VERSION ""

NS_ :

BS_:

BU_:

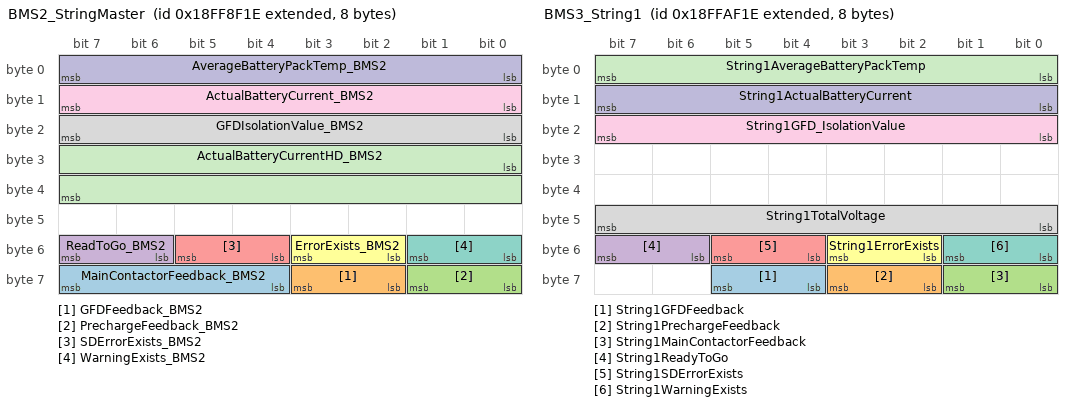
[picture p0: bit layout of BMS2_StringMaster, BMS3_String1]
BO_ 2566885150 BMS2_StringMaster: 8 Vector__XXX
 SG_ MainContactorFeedback_BMS2 : 60|4@1+ (1,0) [0|15] "" Vector__XXX
 SG_ GFDFeedback_BMS2 : 58|2@1+ (1,0) [0|3] "" Vector__XXX
 SG_ PrechargeFeedback_BMS2 : 56|2@1+ (1,0) [0|3] "" Vector__XXX
 SG_ ReadToGo_BMS2 : 54|2@1+ (1,0) [0|3] "" Vector__XXX
 SG_ SDErrorExists_BMS2 : 52|2@1+ (1,0) [0|3] "" Vector__XXX
 SG_ ErrorExists_BMS2 : 50|2@1+ (1,0) [0|3] "" Vector__XXX
 SG_ WarningExists_BMS2 : 48|2@1+ (1,0) [0|3] "" Vector__XXX
 SG_ GFDIsolationValue_BMS2 : 16|8@1+ (4,0) [0|1020] "kOhm" Vector__XXX
 SG_ ActualBatteryCurrent_BMS2 : 8|8@1+ (8,-1000) [-1000|1040] "A" Vector__XXX
 SG_ AverageBatteryPackTemp_BMS2 : 0|8@1+ (0.5,-50) [-50|77.5] "degC" Vector__XXX
 SG_ ActualBatteryCurrentHD_BMS2 : 24|16@1+ (0.065,-2130) [-2130|2129.775] "Amps" Vector__XXX

BO_ 2566893342 BMS3_String1: 8 Vector__XXX
 SG_ String1GFDFeedback : 60|2@1+ (1,0) [0|3] "" Vector__XXX
 SG_ String1PrechargeFeedback : 58|2@1+ (1,0) [0|3] "" Vector__XXX
 SG_ String1MainContactorFeedback : 56|2@1+ (1,0) [0|3] "" Vector__XXX
 SG_ String1ReadyToGo : 54|2@1+ (1,0) [0|3] "" Vector__XXX
 SG_ String1SDErrorExists : 52|2@1+ (1,0) [0|3] "" Vector__XXX
 SG_ String1ErrorExists : 50|2@1+ (1,0) [0|3] "" Vector__XXX
 SG_ String1WarningExists : 48|2@1+ (1,0) [0|3] "" Vector__XXX
 SG_ String1TotalVoltage : 40|8@1+ (3.2,0) [0|816] "Vdc" Vector__XXX
 SG_ String1GFD_IsolationValue : 16|8@1+ (4,0) [0|1020] "kOhm" Vector__XXX
 SG_ String1ActualBatteryCurrent : 8|8@1+ (4,-500) [-500|520] "A" Vector__XXX
 SG_ String1AverageBatteryPackTemp : 0|8@1+ (0.5,50) [50|177.5] "C" Vector__XXX

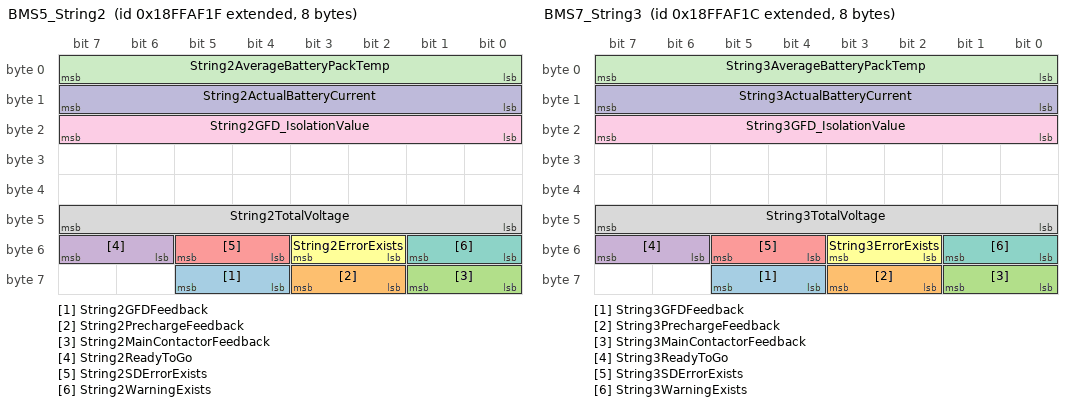
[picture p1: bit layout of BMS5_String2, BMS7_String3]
BO_ 2566893343 BMS5_String2: 8 Vector__XXX
 SG_ String2GFDFeedback : 60|2@1+ (1,0) [0|3] "" Vector__XXX
 SG_ String2PrechargeFeedback : 58|2@1+ (1,0) [0|3] "" Vector__XXX
 SG_ String2MainContactorFeedback : 56|2@1+ (1,0) [0|3] "" Vector__XXX
 SG_ String2ReadyToGo : 54|2@1+ (1,0) [0|3] "" Vector__XXX
 SG_ String2SDErrorExists : 52|2@1+ (1,0) [0|3] "" Vector__XXX
 SG_ String2ErrorExists : 50|2@1+ (1,0) [0|3] "" Vector__XXX
 SG_ String2WarningExists : 48|2@1+ (1,0) [0|3] "" Vector__XXX
 SG_ String2TotalVoltage : 40|8@1+ (3.2,0) [0|816] "Vdc" Vector__XXX
 SG_ String2GFD_IsolationValue : 16|8@1+ (4,0) [0|1020] "kOhm" Vector__XXX
 SG_ String2ActualBatteryCurrent : 8|8@1+ (4,-500) [-500|520] "A" Vector__XXX
 SG_ String2AverageBatteryPackTemp : 0|8@1+ (0.5,50) [50|177.5] "C" Vector__XXX

BO_ 2566893340 BMS7_String3: 8 Vector__XXX
 SG_ String3GFDFeedback : 60|2@1+ (1,0) [0|3] "" Vector__XXX
 SG_ String3PrechargeFeedback : 58|2@1+ (1,0) [0|3] "" Vector__XXX
 SG_ String3MainContactorFeedback : 56|2@1+ (1,0) [0|3] "" Vector__XXX
 SG_ String3ReadyToGo : 54|2@1+ (1,0) [0|3] "" Vector__XXX
 SG_ String3SDErrorExists : 52|2@1+ (1,0) [0|3] "" Vector__XXX
 SG_ String3ErrorExists : 50|2@1+ (1,0) [0|3] "" Vector__XXX
 SG_ String3WarningExists : 48|2@1+ (1,0) [0|3] "" Vector__XXX
 SG_ String3TotalVoltage : 40|8@1+ (3.2,0) [0|816] "Vdc" Vector__XXX
 SG_ String3GFD_IsolationValue : 16|8@1+ (4,0) [0|1020] "kOhm" Vector__XXX
 SG_ String3ActualBatteryCurrent : 8|8@1+ (4,-500) [-500|520] "A" Vector__XXX
 SG_ String3AverageBatteryPackTemp : 0|8@1+ (0.5,50) [50|177.5] "C" Vector__XXX

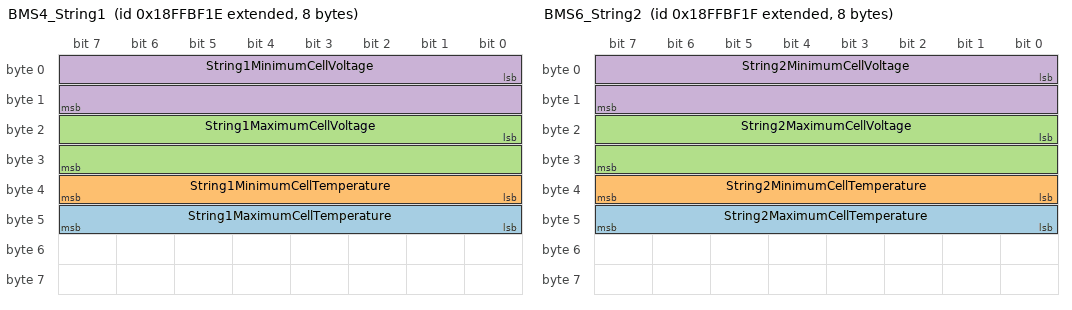
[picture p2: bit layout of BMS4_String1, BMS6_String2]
BO_ 2566897438 BMS4_String1: 8 Vector__XXX
 SG_ String1MaximumCellTemperature : 40|8@1+ (0.5,-50) [-50|77.5] "C" Vector__XXX
 SG_ String1MinimumCellTemperature : 32|8@1+ (0.5,-50) [-50|77.5] "C" Vector__XXX
 SG_ String1MaximumCellVoltage : 16|16@1+ (1,0) [0|65535] "mV" Vector__XXX
 SG_ String1MinimumCellVoltage : 0|16@1+ (1,0) [0|65535] "mV" Vector__XXX

BO_ 2566897439 BMS6_String2: 8 Vector__XXX
 SG_ String2MaximumCellTemperature : 40|8@1+ (0.5,-50) [-50|77.5] "C" Vector__XXX
 SG_ String2MinimumCellTemperature : 32|8@1+ (0.5,-50) [-50|77.5] "C" Vector__XXX
 SG_ String2MaximumCellVoltage : 16|16@1+ (1,0) [0|65535] "mV" Vector__XXX
 SG_ String2MinimumCellVoltage : 0|16@1+ (1,0) [0|65535] "mV" Vector__XXX

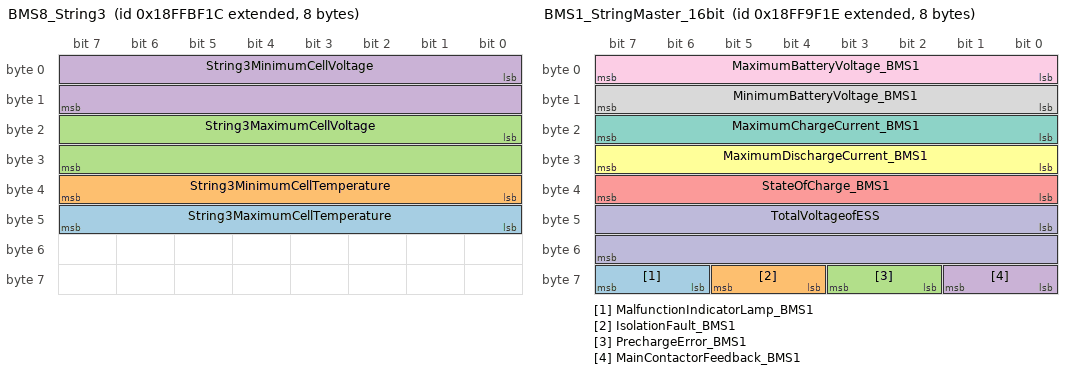
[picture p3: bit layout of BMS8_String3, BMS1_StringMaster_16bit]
BO_ 2566897436 BMS8_String3: 8 Vector__XXX
 SG_ String3MaximumCellTemperature : 40|8@1+ (0.5,-50) [-50|77.5] "C" Vector__XXX
 SG_ String3MinimumCellTemperature : 32|8@1+ (0.5,-50) [-50|77.5] "C" Vector__XXX
 SG_ String3MaximumCellVoltage : 16|16@1+ (1,0) [0|65535] "mV" Vector__XXX
 SG_ String3MinimumCellVoltage : 0|16@1+ (1,0) [0|65535] "mV" Vector__XXX

BO_ 2566889246 BMS1_StringMaster_16bit: 8 Vector__XXX
 SG_ MalfunctionIndicatorLamp_BMS1 : 62|2@1+ (1,0) [0|3] "" Vector__XXX
 SG_ IsolationFault_BMS1 : 60|2@1+ (1,0) [0|3] "" Vector__XXX
 SG_ PrechargeError_BMS1 : 58|2@1+ (1,0) [0|3] "" Vector__XXX
 SG_ MainContactorFeedback_BMS1 : 56|2@1+ (1,0) [0|3] "" Vector__XXX
 SG_ StateOfCharge_BMS1 : 32|8@1+ (0.4,0) [0|102] "%" Vector__XXX
 SG_ MaximumDischargeCurrent_BMS1 : 24|8@1+ (4,0) [0|1020] "A" Vector__XXX
 SG_ MaximumChargeCurrent_BMS1 : 16|8@1+ (4,0) [0|1020] "A" Vector__XXX
 SG_ MinimumBatteryVoltage_BMS1 : 8|8@1+ (3.2,0) [0|816] "Vdc" Vector__XXX
 SG_ MaximumBatteryVoltage_BMS1 : 0|8@1+ (3.2,0) [0|816] "Vdc" Vector__XXX
 SG_ TotalVoltageofESS : 40|16@1+ (0.1,0) [0|6425.5] "V" Vector__XXX

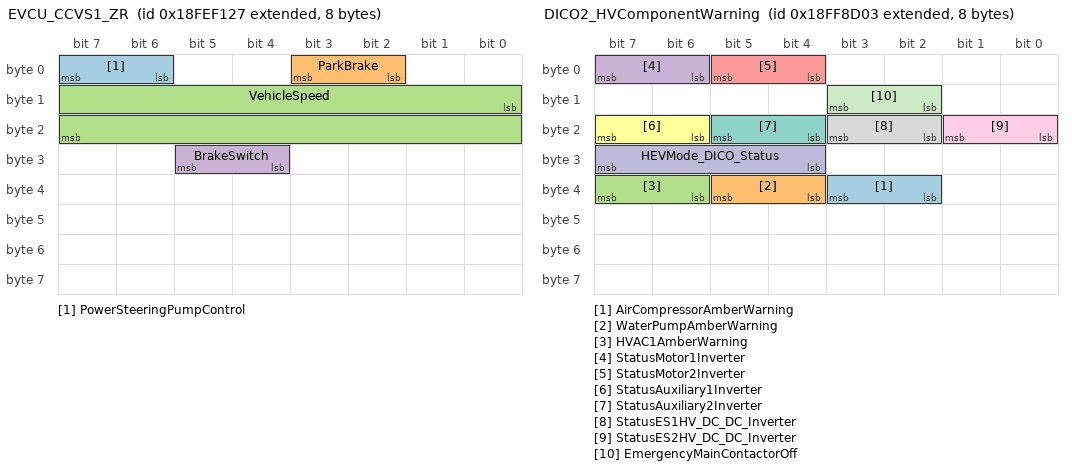
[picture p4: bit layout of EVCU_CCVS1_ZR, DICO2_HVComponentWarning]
BO_ 2566844711 EVCU_CCVS1_ZR: 8 Vector__XXX
 SG_ PowerSteeringPumpControl : 6|2@1+ (1,0) [0|3] "" Vector__XXX
 SG_ ParkBrake : 2|2@1+ (1,0) [0|3] "Enum" Vector__XXX
 SG_ VehicleSpeed : 8|16@1+ (0.00390625,0) [0|250.996] "km/h" Vector__XXX
 SG_ BrakeSwitch : 28|2@1+ (1,0) [0|1] "Enum" Vector__XXX

BO_ 2566885379 DICO5_DriveTempValues: 8 Vector__XXX
 SG_ Motor1WindingTemperature : 8|8@1+ (1,0) [0|255] "C" Vector__XXX
 SG_ iVPM2HeatsinkTemperature : 16|8@1+ (1,-40) [-40|215] "C" Vector__XXX
 SG_ iVPM1HeatsinkTemperature : 0|8@1+ (1,-40) [-40|215] "C" Vector__XXX

BO_ 2566885635 DICO6_BrakeResistor1Temp: 8 Vector__XXX
 SG_ BrakeResistor1Temperature : 16|8@1+ (1,-40) [-40|210] "C" Vector__XXX

BO_ 2566863655 AuxInverterRef1: 8 Vector__XXX
 SG_ SpeedControlAC2WaterPump : 8|8@1+ (0.25,0) [0|63.75] "%" Vector__XXX
 SG_ SpeedControlAC3_AirCompressor : 16|8@1+ (0.25,0) [0|63.75] "%" Vector__XXX
 SG_ SpeedControlAC1_HVAC : 0|8@1+ (0.25,0) [0|63.75] "%" Vector__XXX

BO_ 2566884611 DICO2_HVComponentWarning: 8 Vector__XXX
 SG_ AirCompressorAmberWarning : 34|2@1+ (1,0) [0|3] "" Vector__XXX
 SG_ WaterPumpAmberWarning : 36|2@1+ (1,0) [0|3] "" Vector__XXX
 SG_ HVAC1AmberWarning : 38|2@1+ (1,0) [0|3] "" Vector__XXX
 SG_ StatusMotor1Inverter : 6|2@1+ (1,0) [0|3] "Enum" Vector__XXX
 SG_ StatusMotor2Inverter : 4|2@1+ (1,0) [0|1] "Enum" Vector__XXX
 SG_ StatusAuxiliary1Inverter : 22|2@1+ (1,0) [0|1] "" Vector__XXX
 SG_ StatusAuxiliary2Inverter : 20|2@1+ (1,0) [0|1] "" Vector__XXX
 SG_ StatusES1HV_DC_DC_Inverter : 18|2@1+ (1,0) [0|1] "" Vector__XXX
 SG_ StatusES2HV_DC_DC_Inverter : 16|2@1+ (1,0) [0|1] "" Vector__XXX
 SG_ HEVMode_DICO_Status : 28|4@1+ (1,0) [0|1] "" Vector__XXX
 SG_ EmergencyMainContactorOff : 10|2@1+ (1,0) [0|1] "" Vector__XXX

BO_ 2566885123 DICO1_EVCU: 8 Vector__XXX
 SG_ DriveMotorSpeed : 16|16@1+ (0.46689,-15000) [-15000|15000] "RPM" Vector__XXX
 SG_ GlobalEnablePrechargeSiemens : 11|1@1+ (1,0) [0|1] "" Vector__XXX
 SG_ KeyStartAcknowledge : 2|1@1+ (1,0) [0|1] "" Vector__XXX
 SG_ BrakeResistorPowerFb : 48|8@1+ (1,0) [0|250] "kW" Vector__XXX
 SG_ DriveSystemActive : 0|1@1+ (1,0) [0|1] "Enum" Vector__XXX
 SG_ InitializationPhase : 1|1@1+ (1,0) [0|1] "Enum" Vector__XXX
 SG_ PreChargingActive : 3|1@1+ (1,0) [0|1] "Enum" Vector__XXX
 SG_ DNRStatus : 4|3@1+ (1,0) [0|7] "Enum" Vector__XXX
 SG_ DirectionOfVehicle : 7|1@1+ (1,0) [0|1] "Enum" Vector__XXX
 SG_ RedStopLamp : 8|1@1+ (1,0) [0|1] "Enum" Vector__XXX
 SG_ RedLampFlashing : 9|1@1+ (1,0) [0|1] "Enum" Vector__XXX
 SG_ AmberWarningLamp : 10|1@1+ (1,0) [0|1] "Enum" Vector__XXX
 SG_ CoolingPumpRequestTraction : 12|1@1+ (1,0) [0|1] "Enum" Vector__XXX
 SG_ CoolingFanRequestTraction : 13|1@1+ (1,0) [0|1] "Enum" Vector__XXX
 SG_ PrechargeContactorClosed : 14|1@1+ (1,0) [0|1] "Enum" Vector__XXX
 SG_ MainContactorClosed : 15|1@1+ (1,0) [0|1] "Enum" Vector__XXX
 SG_ ActualDriveMotorTorque : 40|8@1+ (1,-125) [-125|125] "%" Vector__XXX
 SG_ ErrorBufferIndication : 63|1@1+ (1,0) [0|1] "Enum" Vector__XXX
 SG_ ErrorBufferNumer : 56|4@1+ (1,0) [0|1] "Decimal" Vector__XXX

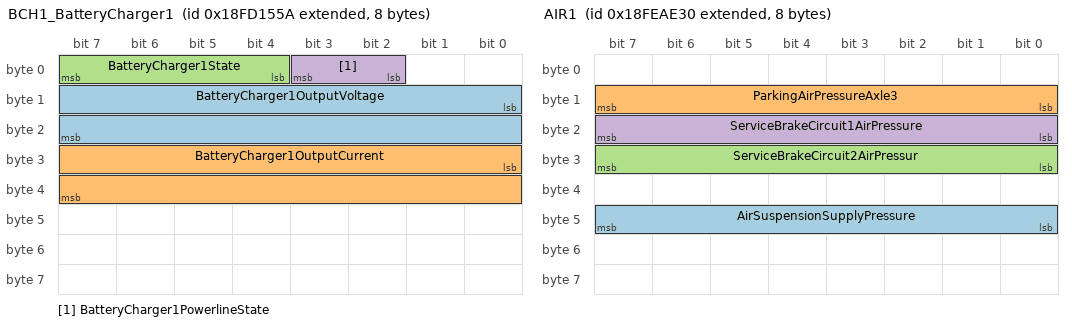
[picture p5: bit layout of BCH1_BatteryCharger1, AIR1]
BO_ 2566722906 BCH1_BatteryCharger1: 8 Vector__XXX
 SG_ BatteryCharger1OutputVoltage : 8|16@1+ (0.05,0) [0|3212.75] "Vdc" Vector__XXX
 SG_ BatteryCharger1OutputCurrent : 24|16@1+ (0.05,-1600) [-1600|1600] "A" Vector__XXX
 SG_ BatteryCharger1State : 4|4@1+ (1,0) [0|1] "Enum" Vector__XXX
 SG_ BatteryCharger1PowerlineState : 2|2@1+ (1,0) [0|1] "Enum" Vector__XXX

BO_ 2566722650 BCH2_BatteryCharger2: 8 Vector__XXX
 SG_ BatteryCharger2OutputVoltage : 8|16@1+ (0.05,0) [0|3276.75] "Vdc" Vector__XXX
 SG_ BatteryCharger2OutputCurrent : 24|16@1+ (0.05,-1600) [-1600|1676.75] "A" Vector__XXX

BO_ 2566827568 AIR1: 8 Vector__XXX
 SG_ AirSuspensionSupplyPressure : 40|8@1+ (0.1,0) [0|25.5] "kPa" Vector__XXX
 SG_ ParkingAirPressureAxle3 : 8|8@1+ (0.1,0) [0|25.5] "kPa" Vector__XXX
 SG_ ServiceBrakeCircuit2AirPressur : 24|8@1+ (0.1,0) [0|25.5] "kPa" Vector__XXX
 SG_ ServiceBrakeCircuit1AirPressure : 16|8@1+ (0.1,0) [0|25.5] "kPa" Vector__XXX

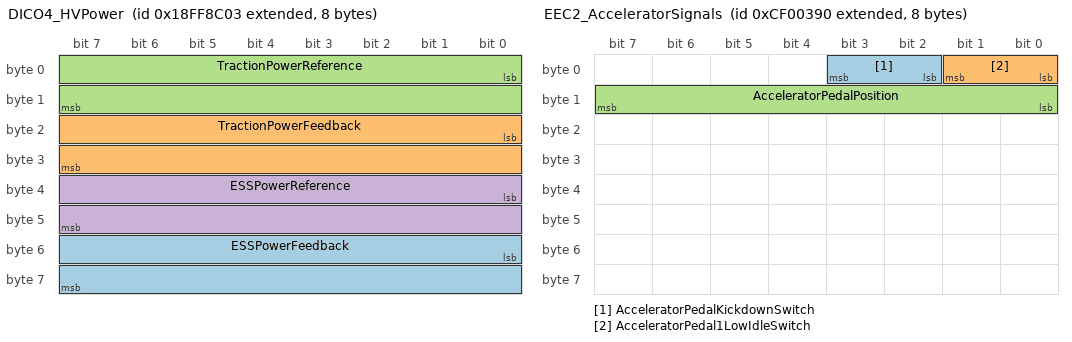
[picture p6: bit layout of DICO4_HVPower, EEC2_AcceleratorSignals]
BO_ 2566884355 DICO4_HVPower: 8 Vector__XXX
 SG_ ESSPowerFeedback : 48|16@1+ (0.0159,-510) [-510|510.001] "kW" Vector__XXX
 SG_ TractionPowerFeedback : 16|16@1+ (0.0159,-510) [-510|510.001] "kW" Vector__XXX
 SG_ TractionPowerReference : 0|16@1+ (0.0159,-510) [-510|510] "kW" Vector__XXX
 SG_ ESSPowerReference : 32|16@1+ (0.0159,-510) [-510|510] "kW" Vector__XXX

BO_ 2566884867 DICO3_DCLinkVoltageCurrent: 8 Vector__XXX
 SG_ DCLinkVoltageDriveSystem : 0|8@1+ (3.2,0) [0|800] "Vdc" Vector__XXX
 SG_ DCLinkTractionCurrent : 8|8@1+ (4,-500) [-500|500] "A" Vector__XXX

BO_ 2364539792 EEC2_AcceleratorSignals: 8 Vector__XXX
 SG_ AcceleratorPedalKickdownSwitch : 2|2@1+ (1,0) [0|3] "" Vector__XXX
 SG_ AcceleratorPedal1LowIdleSwitch : 0|2@1+ (1,0) [0|3] "" Vector__XXX
 SG_ AcceleratorPedalPosition : 8|8@1+ (0.4,0) [0|102] "%" Vector__XXX

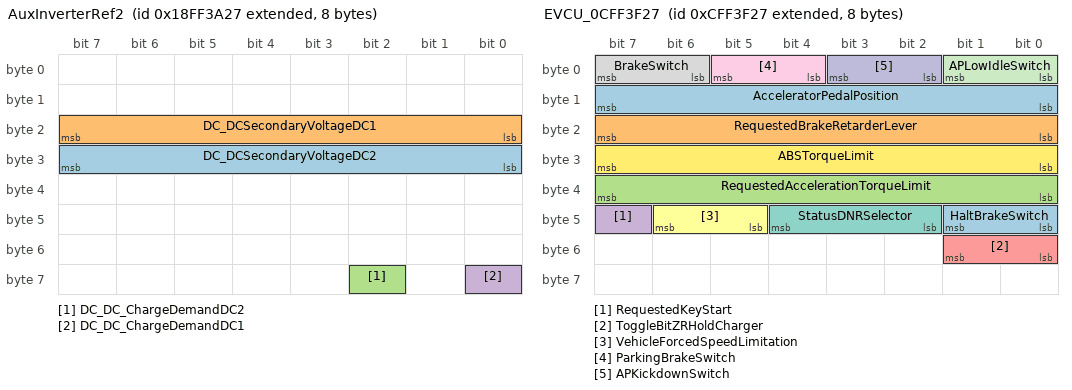
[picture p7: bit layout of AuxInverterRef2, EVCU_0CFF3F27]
BO_ 2566863399 AuxInverterRef2: 8 Vector__XXX
 SG_ DC_DCSecondaryVoltageDC2 : 24|8@1+ (0.2,0) [0|51] "Vdc" Vector__XXX
 SG_ DC_DCSecondaryVoltageDC1 : 16|8@1+ (0.2,0) [0|51] "Vdc" Vector__XXX
 SG_ DC_DC_ChargeDemandDC2 : 58|1@1+ (1,0) [0|1] "Enum" Vector__XXX
 SG_ DC_DC_ChargeDemandDC1 : 56|1@1+ (1,0) [0|1] "" Vector__XXX

BO_ 2566749479 FMS_TellTale_Status: 8 Vector__XXX
 SG_ TellTaleStatus : 1|5@1+ (1,0) [0|31] "" Vector__XXX
 SG_ TelltaleVisible : 0|1@1+ (1,0) [0|1] "" Vector__XXX

BO_ 2566852647 DIA_VH10_Bat: 8 Vector__XXX
 SG_ State_2_7 : 23|1@1+ (1,0) [0|1] "" Vector__XXX
 SG_ State_2_6 : 22|1@1+ (1,0) [0|1] "" Vector__XXX
 SG_ State_2_5 : 21|1@1+ (1,0) [0|1] "" Vector__XXX
 SG_ State_2_4 : 20|1@1+ (1,0) [0|1] "" Vector__XXX
 SG_ State_2_3 : 19|1@1+ (1,0) [0|1] "" Vector__XXX
 SG_ State_2_2 : 18|1@1+ (1,0) [0|1] "" Vector__XXX
 SG_ State_2_1 : 17|1@1+ (1,0) [0|1] "" Vector__XXX
 SG_ EmergencyShutdown : 16|1@1+ (1,0) [0|1] "" Vector__XXX
 SG_ State_1_15 : 14|1@1+ (1,0) [0|1] "" Vector__XXX
 SG_ State_1_14 : 13|1@1+ (1,0) [0|1] "" Vector__XXX
 SG_ State_1_13 : 12|1@1+ (1,0) [0|1] "" Vector__XXX
 SG_ State_1_12 : 11|1@1+ (1,0) [0|1] "" Vector__XXX
 SG_ State_1_11 : 10|1@1+ (1,0) [0|1] "" Vector__XXX
 SG_ State_1_10 : 9|1@1+ (1,0) [0|1] "" Vector__XXX
 SG_ State_1_9 : 8|1@1+ (1,0) [0|1] "" Vector__XXX
 SG_ State_1_8 : 7|1@1+ (1,0) [0|1] "" Vector__XXX
 SG_ State_1_7 : 6|1@1+ (1,0) [0|1] "" Vector__XXX
 SG_ State_1_6 : 5|1@1+ (1,0) [0|1] "" Vector__XXX
 SG_ State_1_5 : 4|1@1+ (1,0) [0|1] "" Vector__XXX
 SG_ State_1_4 : 3|1@1+ (1,0) [0|1] "" Vector__XXX
 SG_ State_1_3 : 2|1@1+ (1,0) [0|1] "" Vector__XXX
 SG_ State_1_2 : 1|1@1+ (1,0) [0|1] "" Vector__XXX
 SG_ State_1_1 : 0|1@1+ (1,0) [0|1] "" Vector__XXX
 SG_ SauconRelays : 48|1@1+ (1,0) [0|1] "" Vector__XXX
 SG_ EmergencySwitchTractionMotor : 47|1@1+ (1,0) [0|1] "" Vector__XXX
 SG_ BatteryVoltage24VLow : 46|1@1+ (1,0) [0|1] "" Vector__XXX
 SG_ SwitchOffplus15Inhibit : 45|1@1+ (1,0) [0|1] "" Vector__XXX
 SG_ ZRHold : 44|1@1+ (1,0) [0|1] "" Vector__XXX
 SG_ Plus15Ignition : 43|1@1+ (1,0) [0|1] "" Vector__XXX
 SG_ Plus30 : 42|1@1+ (1,0) [0|1] "" Vector__XXX
 SG_ EmergencySwitch24V : 41|1@1+ (1,0) [0|1] "" Vector__XXX
 SG_ HighCurrentSwitchOff : 40|1@1+ (1,0) [0|1] "" Vector__XXX
 SG_ ParkBrakeActive : 39|1@1+ (1,0) [0|1] "" Vector__XXX
 SG_ EmergencyFlashers : 38|1@1+ (1,0) [0|1] "" Vector__XXX
 SG_ ZRIcanWakeup : 37|1@1+ (1,0) [0|1] "" Vector__XXX
 SG_ SpeedAbove3kmh : 36|1@1+ (1,0) [0|1] "" Vector__XXX
 SG_ DMUXStateWakeUp : 35|1@1+ (1,0) [0|1] "" Vector__XXX
 SG_ SwitchEngineStart : 34|1@1+ (1,0) [0|1] "" Vector__XXX
 SG_ SwitchIgnitionK15 : 33|1@1+ (1,0) [0|1] "" Vector__XXX
 SG_ SwitchBatteryK30 : 32|1@1+ (1,0) [0|1] "" Vector__XXX

BO_ 2365538087 EVCU_0CFF3F27: 8 Vector__XXX
 SG_ AcceleratorPedalPosition : 8|8@1+ (0.4,0) [0|100] "%" Vector__XXX
 SG_ RequestedBrakeRetarderLever : 16|8@1+ (1,-125) [-125|130] "%" Vector__XXX
 SG_ RequestedAccelerationTorqueLimit : 32|8@1+ (1,-125) [0|130] "%" Vector__XXX
 SG_ RequestedKeyStart : 47|1@1+ (1,0) [0|1] "" Vector__XXX
 SG_ ToggleBitZRHoldCharger : 48|2@1+ (1,0) [0|3] "" Vector__XXX
 SG_ VehicleForcedSpeedLimitation : 45|2@1+ (1,0) [0|1] "Enum" Vector__XXX
 SG_ StatusDNRSelector : 42|3@1+ (1,0) [0|1] "Enum" Vector__XXX
 SG_ BrakeSwitch : 6|2@1+ (1,0) [0|1] "Enum" Vector__XXX
 SG_ ParkingBrakeSwitch : 4|2@1+ (1,0) [0|3] "Enum" Vector__XXX
 SG_ APKickdownSwitch : 2|2@1+ (1,0) [0|3] "Enum" Vector__XXX
 SG_ APLowIdleSwitch : 0|2@1+ (1,0) [0|3] "Enum" Vector__XXX
 SG_ ABSTorqueLimit : 24|8@1+ (1,-125) [-125|130] "%" Vector__XXX
 SG_ HaltBrakeSwitch : 40|2@1+ (1,0) [0|3] "Enum" Vector__XXX

BO_ 2365537831 EVCU_HEVModeBrakeResRef: 8 Vector__XXX
 SG_ BrakeReisistorReference : 32|8@1+ (0.25,0) [0|63.75] "kW" Vector__XXX
 SG_ HEVMode_ZR_Status : 28|4@1+ (1,0) [0|15] "" Vector__XXX

BO_ 2566842927 EVCU_Vehicle_Weight_18FEEA2F: 8 Vector__XXX
 SG_ AxleLocation : 0|8@1+ (1,0) [0|255] "Enum" Vector__XXX
 SG_ VehicleWeight : 8|16@1+ (0.5,0) [0|32767.5] "kg" Vector__XXX

BO_ 2565866755 EVCU_18F00503: 8 Vector__XXX
 SG_ SelectedGear : 0|8@1+ (1,0) [0|255] "Enum" Vector__XXX

BO_ 2566845735 FMS_AmbientConditions: 8 Vector__XXX
 SG_ ExteriorTemperature : 24|16@1+ (0.03125,-273) [-273|1774.96875] "DegC" Vector__XXX
 SG_ InteriorTemperature : 8|16@1+ (0.03215,-273) [-273|1833.95] "DegC" Vector__XXX

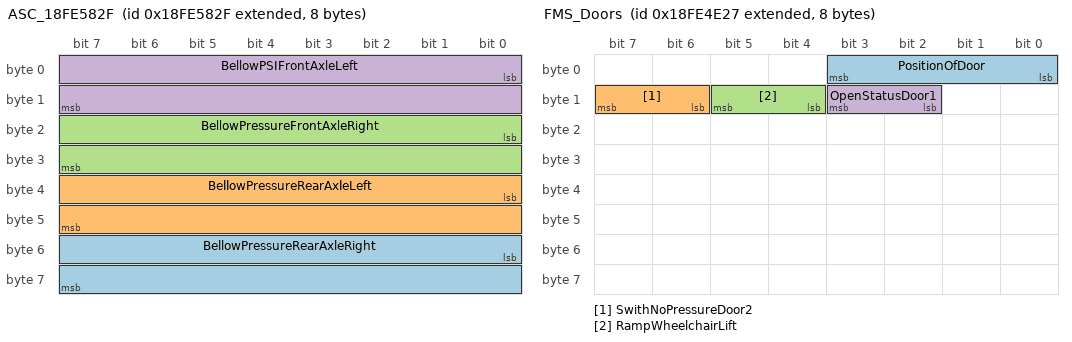
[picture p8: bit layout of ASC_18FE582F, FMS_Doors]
BO_ 2566805551 ASC_18FE582F: 8 Vector__XXX
 SG_ BellowPressureRearAxleRight : 48|16@1+ (0.1,0) [0|6553.5] "kPa" Vector__XXX
 SG_ BellowPressureRearAxleLeft : 32|16@1+ (0.1,0) [0|6553.5] "kPa" Vector__XXX
 SG_ BellowPressureFrontAxleRight : 16|16@1+ (0.1,0) [0|6553.5] "kPa" Vector__XXX
 SG_ BellowPSIFrontAxleLeft : 0|16@1+ (0.1,0) [0|6553.5] "kPa" Vector__XXX

BO_ 2566832407 VDHR_VehicleDistance: 8 Vector__XXX
 SG_ TotalVehicleDistanceHighRes : 0|32@1+ (5,0) [0|21474836475] "Meter" Vector__XXX
 SG_ TripDistanceHighRes : 32|32@1+ (5,0) [0|21474836475] "Meter" Vector__XXX

BO_ 2566802983 FMS_Doors: 8 Vector__XXX
 SG_ PositionOfDoor : 0|4@1+ (1,0) [0|15] "" Vector__XXX
 SG_ SwithNoPressureDoor2 : 14|2@1+ (1,0) [0|3] "" Vector__XXX
 SG_ RampWheelchairLift : 12|2@1+ (1,0) [0|3] "" Vector__XXX
 SG_ OpenStatusDoor1 : 10|2@1+ (1,0) [0|3] "" Vector__XXX

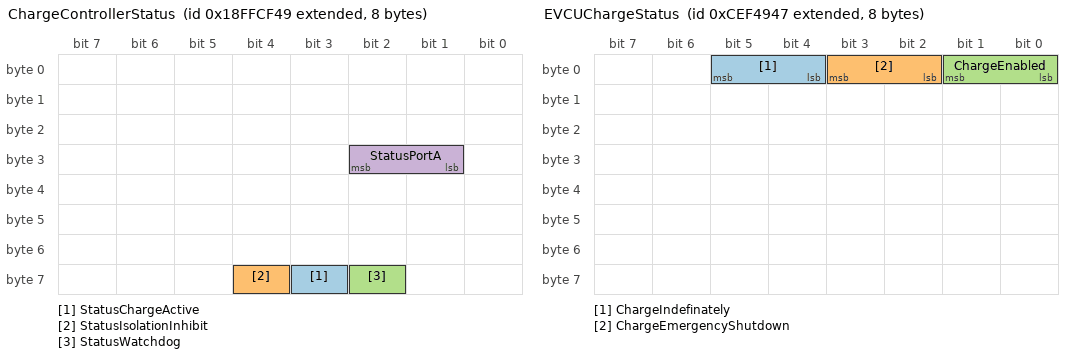
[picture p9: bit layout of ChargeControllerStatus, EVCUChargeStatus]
BO_ 2566901577 ChargeControllerStatus: 8 Vector__XXX
 SG_ StatusChargeActive : 59|1@1+ (1,0) [0|1] "" Vector__XXX
 SG_ StatusIsolationInhibit : 60|1@1+ (1,0) [0|1] "" Vector__XXX
 SG_ StatusWatchdog : 58|1@1+ (1,0) [0|1] "" Vector__XXX
 SG_ StatusPortA : 25|2@1+ (1,0) [0|3] "" Vector__XXX

BO_ 2364492103 EVCUChargeStatus: 8 Vector__XXX
 SG_ ChargeIndefinately : 4|2@1+ (1,0) [0|3] "" Vector__XXX
 SG_ ChargeEmergencyShutdown : 2|2@1+ (1,0) [0|3] "" Vector__XXX
 SG_ ChargeEnabled : 0|2@1+ (1,0) [0|3] "" Vector__XXX

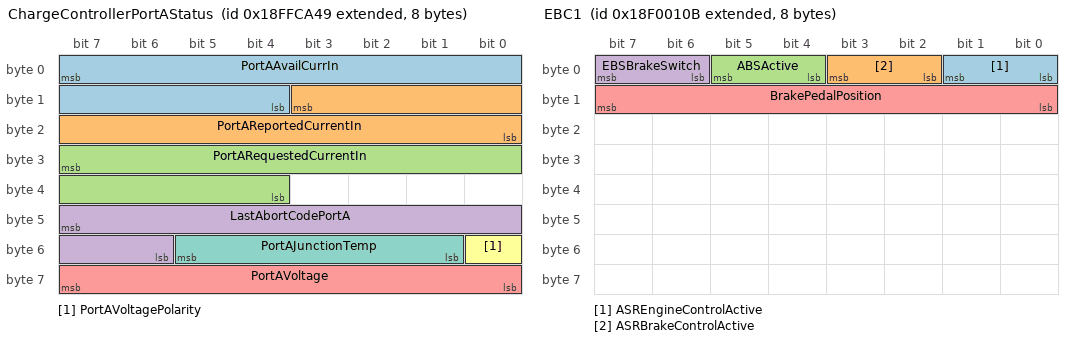
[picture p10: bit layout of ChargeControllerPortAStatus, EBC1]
BO_ 2566900297 ChargeControllerPortAStatus: 8 Vector__XXX
 SG_ PortAAvailCurrIn : 7|12@0+ (0.25,-512) [-512|511.75] "Amp" Vector__XXX
 SG_ PortAReportedCurrentIn : 11|12@0+ (0.25,-512) [-512|511.75] "Amp" Vector__XXX
 SG_ PortARequestedCurrentIn : 31|12@0+ (0.25,-512) [-512|511.75] "Amp" Vector__XXX
 SG_ LastAbortCodePortA : 47|10@0+ (1,0) [0|1023] "" Vector__XXX
 SG_ PortAVoltage : 56|8@1+ (4,0) [0|1020] "Volts" Vector__XXX
 SG_ PortAVoltagePolarity : 48|1@1+ (1,0) [0|1] "" Vector__XXX
 SG_ PortAJunctionTemp : 49|5@1+ (5,-50) [0|1] "C" Vector__XXX

BO_ 2566838782 EVCUGFDStatus_NullAddress: 8 Vector__XXX

BO_ 2566843687 CruiseControlSetSpeed: 8 Vector__XXX

BO_ 2566884099 DICO7_AuxiliaryInverterPower: 8 Vector__XXX
 SG_ PowerFeedbackMotor3 : 0|8@1+ (0.2,0) [0|50] "kW" Vector__XXX
 SG_ PowerFeedbackMotor4 : 8|8@1+ (0.2,0) [0|50] "kW" Vector__XXX
 SG_ SpeedMotor3 : 16|8@1+ (20,0) [0|5000] "rpm" Vector__XXX
 SG_ SpeedMotor4 : 24|8@1+ (20,0) [0|5000] "rpm" Vector__XXX

BO_ 2566885891 DICO8_BrakeResistor2Temp: 8 Vector__XXX
 SG_ BrakeResistor2Temperature : 0|8@1+ (1,0) [0|255] "" Vector__XXX

BO_ 2566701658 HybridSystemState: 8 Vector__XXX
 SG_ OverspeedIndicator : 22|2@1+ (1,0) [0|3] "" Vector__XXX
 SG_ OverspeedAudibleAlarm : 24|2@1+ (1,0) [0|3] "" Vector__XXX

BO_ 2566827553 EBS_BrakePressure: 8 Vector__XXX
 SG_ ServiceBrakeCircuit2AirPsiEBS : 24|8@1+ (1,0) [0|255] "" Vector__XXX
 SG_ ServiceBrakeCircuit1AirPsiEBS : 16|8@1+ (1,0) [0|255] "" Vector__XXX
 SG_ ParkingOrAirTrailerPsiEBS : 8|8@1+ (1,0) [0|255] "" Vector__XXX

BO_ 2565865739 EBC1: 8 Vector__XXX
 SG_ ASREngineControlActive : 0|2@1+ (1,0) [0|3] "Enum" Vector__XXX
 SG_ ASRBrakeControlActive : 2|2@1+ (1,0) [0|3] "Enum" Vector__XXX
 SG_ ABSActive : 4|2@1+ (1,0) [0|3] "Enum" Vector__XXX
 SG_ EBSBrakeSwitch : 6|2@1+ (1,0) [0|3] "Enum" Vector__XXX
 SG_ BrakePedalPosition : 8|8@1+ (0.4,0) [0|100] "%" Vector__XXX

BO_ 2565475111 EBC4_RQST: 8 Vector__XXX

BO_ 2349015240 EBS21: 8 Vector__XXX

BO_ 2566873127 MSF: 8 Vector__XXX

BO_ 2566769959 WipersOWW: 8 Vector__XXX
 SG_ WiperSpeed : 3|5@1+ (1,0) [0|31] "" Vector__XXX

BO_ 2566827591 FMS_AIR1: 8 Vector__XXX

BO_ 2566805543 FMS_ASC_AirSuspensionControl: 8 Vector__XXX

BO_ 2566744103 FMS_GCVW_Vehicle_Weight: 8 Vector__XXX

BO_ 2566615335 FMS_Generic_Tx_Message: 8 Vector__XXX

BO_ 2566609191 FMS_HVESP1HIST: 8 Vector__XXX

BO_ 2565902631 FMS_HVESSD2: 8 Vector__XXX

BO_ 2565472295 FMS_RQST: 8 Vector__XXX

BO_ 2566841895 FMS_TD_TimeDate: 8 Vector__XXX

BO_ 2566877735 FMS_VHD5_Power_Values: 8 Vector__XXX

BO_ 2566832423 FMS_VHDR_Distance: 8 Vector__XXX

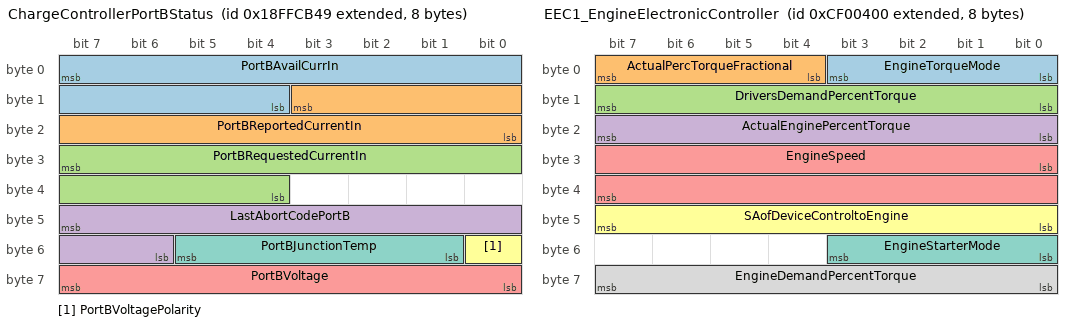
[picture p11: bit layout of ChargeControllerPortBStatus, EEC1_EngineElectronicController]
BO_ 2566900553 ChargeControllerPortBStatus: 8 Vector__XXX
 SG_ PortBAvailCurrIn : 7|12@0+ (0.25,-512) [-512|511.75] "Amp" Vector__XXX
 SG_ PortBReportedCurrentIn : 11|12@0+ (0.25,-512) [-512|511.75] "Amp" Vector__XXX
 SG_ PortBRequestedCurrentIn : 31|12@0+ (0.25,-512) [-512|511.75] "Amp" Vector__XXX
 SG_ LastAbortCodePortB : 47|10@0+ (1,0) [0|1023] "" Vector__XXX
 SG_ PortBVoltage : 56|8@1+ (4,0) [0|1020] "Volts" Vector__XXX
 SG_ PortBVoltagePolarity : 48|1@1+ (1,0) [0|1] "" Vector__XXX
 SG_ PortBJunctionTemp : 49|5@1+ (5,-50) [0|1] "C" Vector__XXX

BO_ 2364539904 EEC1_EngineElectronicController: 8 Vector__XXX
 SG_ EngineTorqueMode : 0|4@1+ (1,0) [0|15] "Enum" Vector__XXX
 SG_ ActualPercTorqueFractional : 4|4@1+ (1,0) [0|1] "" Vector__XXX
 SG_ DriversDemandPercentTorque : 8|8@1+ (1,-125) [-125|125] "%" Vector__XXX
 SG_ ActualEnginePercentTorque : 16|8@1+ (1,-125) [-125|125] "%" Vector__XXX
 SG_ EngineSpeed : 24|16@1+ (0.125,0) [0|8191.875] "rpm" Vector__XXX
 SG_ SAofDeviceControltoEngine : 40|8@1+ (1,0) [0|1] "" Vector__XXX
 SG_ EngineStarterMode : 48|4@1+ (1,0) [0|1] "" Vector__XXX
 SG_ EngineDemandPercentTorque : 56|8@1+ (1,-125) [-125|125] "%" Vector__XXX

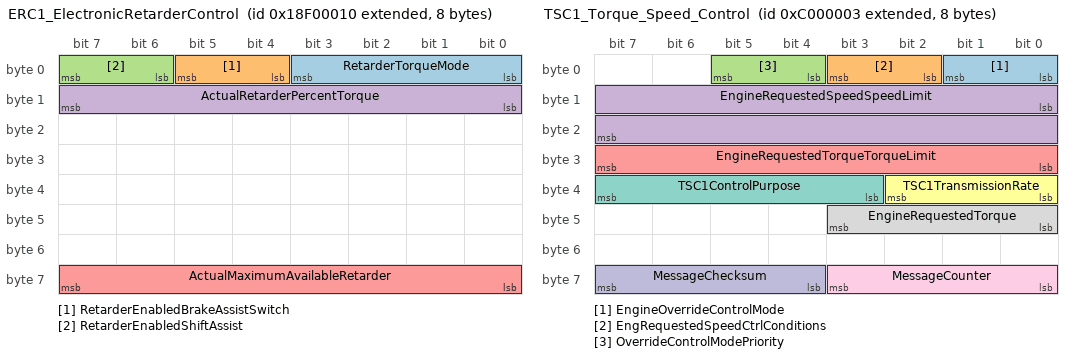
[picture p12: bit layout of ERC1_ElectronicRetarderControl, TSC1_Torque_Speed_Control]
BO_ 2565865488 ERC1_ElectronicRetarderControl: 8 Vector__XXX
 SG_ RetarderTorqueMode : 0|4@1+ (1,0) [0|1] "" Vector__XXX
 SG_ RetarderEnabledBrakeAssistSwitch : 4|2@1+ (1,0) [0|1] "Enum" Vector__XXX
 SG_ RetarderEnabledShiftAssist : 6|2@1+ (1,0) [0|1] "Enum" Vector__XXX
 SG_ ActualRetarderPercentTorque : 8|8@1+ (1,-125) [-125|125] "%" Vector__XXX
 SG_ ActualMaximumAvailableRetarder : 56|8@1+ (1,-125) [-125|125] "%" Vector__XXX

BO_ 2348810243 TSC1_Torque_Speed_Control: 8 Vector__XXX
 SG_ EngineOverrideControlMode : 0|2@1+ (1,0) [0|3] "" Vector__XXX
 SG_ EngRequestedSpeedCtrlConditions : 2|2@1+ (1,0) [0|3] "" Vector__XXX
 SG_ OverrideControlModePriority : 4|2@1+ (1,0) [0|3] "" Vector__XXX
 SG_ EngineRequestedSpeedSpeedLimit : 8|16@1+ (0.125,0) [0|8031.875] "rpm" Vector__XXX
 SG_ EngineRequestedTorqueTorqueLimit : 24|8@1+ (1,-125) [-125|125] "%" Vector__XXX
 SG_ TSC1TransmissionRate : 32|3@1+ (1,0) [0|7] "" Vector__XXX
 SG_ TSC1ControlPurpose : 35|5@1+ (1,0) [0|31] "" Vector__XXX
 SG_ EngineRequestedTorque : 40|4@1+ (0.125,0) [0|1.625] "%" Vector__XXX
 SG_ MessageCounter : 56|4@1+ (1,0) [0|15] "" Vector__XXX
 SG_ MessageChecksum : 60|4@1+ (1,0) [0|15] "" Vector__XXX

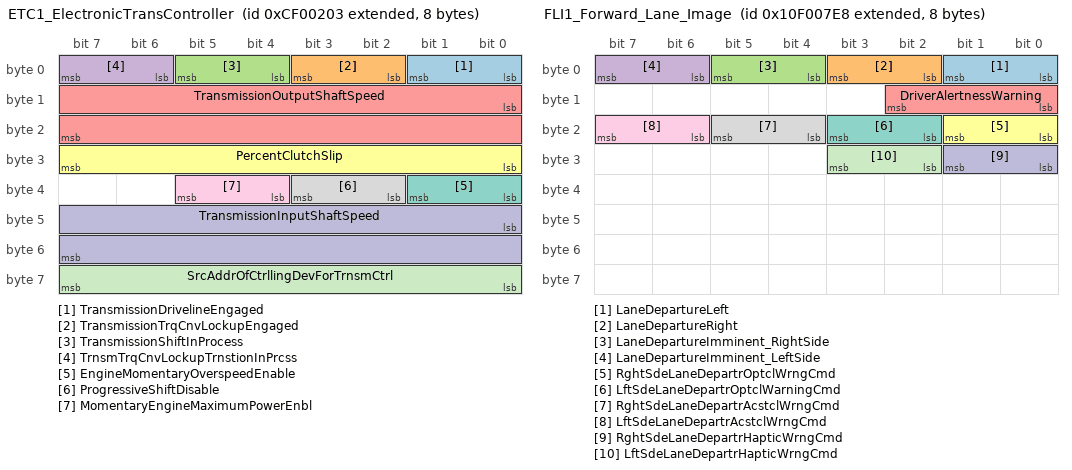
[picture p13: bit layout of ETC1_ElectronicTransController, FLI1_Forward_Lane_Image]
BO_ 2364539395 ETC1_ElectronicTransController: 8 Vector__XXX
 SG_ TransmissionDrivelineEngaged : 0|2@1+ (1,0) [0|3] "" Vector__XXX
 SG_ TransmissionTrqCnvLockupEngaged : 2|2@1+ (1,0) [0|3] "" Vector__XXX
 SG_ TransmissionShiftInProcess : 4|2@1+ (1,0) [0|3] "" Vector__XXX
 SG_ TrnsmTrqCnvLockupTrnstionInPrcss : 6|2@1+ (1,0) [0|3] "" Vector__XXX
 SG_ TransmissionOutputShaftSpeed : 8|16@1+ (0.125,0) [0|8031.875] "rpm" Vector__XXX
 SG_ PercentClutchSlip : 24|8@1+ (0.4,0) [0|100] "%" Vector__XXX
 SG_ EngineMomentaryOverspeedEnable : 32|2@1+ (1,0) [0|3] "" Vector__XXX
 SG_ ProgressiveShiftDisable : 34|2@1+ (1,0) [0|3] "" Vector__XXX
 SG_ MomentaryEngineMaximumPowerEnbl : 36|2@1+ (1,0) [0|3] "" Vector__XXX
 SG_ TransmissionInputShaftSpeed : 40|16@1+ (0.125,0) [0|8031.875] "rpm" Vector__XXX
 SG_ SrcAddrOfCtrllingDevForTrnsmCtrl : 56|8@1+ (1,0) [0|255] "" Vector__XXX

BO_ 2431649768 FLI1_Forward_Lane_Image: 8 Vector__XXX
 SG_ LaneDepartureLeft : 0|2@1+ (1,0) [0|3] "" Vector__XXX
 SG_ LaneDepartureRight : 2|2@1+ (1,0) [0|3] "" Vector__XXX
 SG_ LaneDepartureImminent_RightSide : 4|2@1+ (1,0) [0|3] "" Vector__XXX
 SG_ LaneDepartureImminent_LeftSide : 6|2@1+ (1,0) [0|3] "" Vector__XXX
 SG_ DriverAlertnessWarning : 8|3@1+ (1,0) [0|7] "" Vector__XXX
 SG_ RghtSdeLaneDepartrOptclWrngCmd : 16|2@1+ (1,0) [0|3] "" Vector__XXX
 SG_ LftSdeLaneDepartrOptclWarningCmd : 18|2@1+ (1,0) [0|3] "" Vector__XXX
 SG_ RghtSdeLaneDepartrAcstclWrngCmd : 20|2@1+ (1,0) [0|3] "" Vector__XXX
 SG_ LftSdeLaneDepartrAcstclWrngCmd : 22|2@1+ (1,0) [0|3] "" Vector__XXX
 SG_ RghtSdeLaneDepartrHapticWrngCmd : 24|2@1+ (1,0) [0|3] "" Vector__XXX
 SG_ LftSdeLaneDepartrHapticWrngCmd : 26|2@1+ (1,0) [0|3] "" Vector__XXX

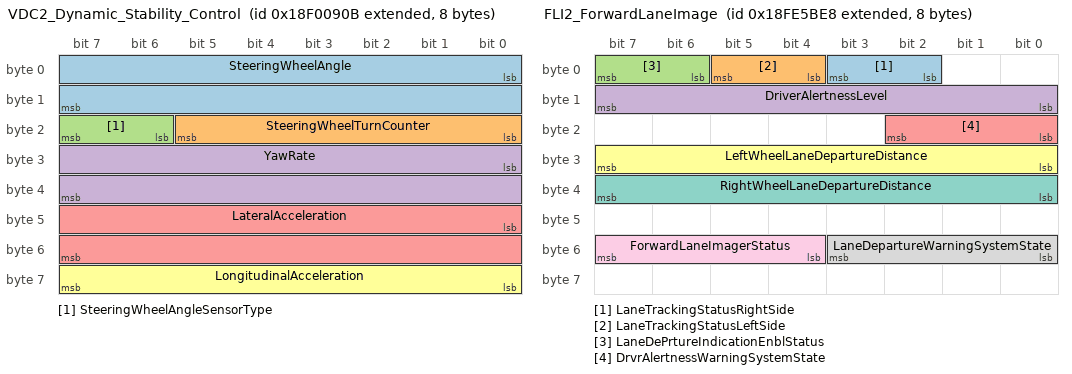
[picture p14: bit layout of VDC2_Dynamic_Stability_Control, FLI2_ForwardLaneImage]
BO_ 2565867787 VDC2_Dynamic_Stability_Control: 8 Vector__XXX
 SG_ SteeringWheelAngle : 0|16@1+ (0.0009765625,-31.374) [-31.374|31.3750234375] "rad" Vector__XXX
 SG_ SteeringWheelTurnCounter : 16|6@1+ (1,-32) [-32|29] "" Vector__XXX
 SG_ SteeringWheelAngleSensorType : 22|2@1+ (1,0) [0|3] "" Vector__XXX
 SG_ YawRate : 24|16@1+ (0.0001220703125,-3.92) [-3.92|3.9236279296875] "rad/s" Vector__XXX
 SG_ LateralAcceleration : 40|16@1+ (0.00048828125,-15.687) [-15.687|15.68751171875] "m/s^2" Vector__XXX
 SG_ LongitudinalAcceleration : 56|8@1+ (0.1,-12.5) [-12.5|12.5] "m/s^2" Vector__XXX

BO_ 2566806504 FLI2_ForwardLaneImage: 8 Vector__XXX
 SG_ LaneTrackingStatusRightSide : 2|2@1+ (1,0) [0|3] "" Vector__XXX
 SG_ LaneTrackingStatusLeftSide : 4|2@1+ (1,0) [0|3] "" Vector__XXX
 SG_ LaneDePrtureIndicationEnblStatus : 6|2@1+ (1,0) [0|3] "" Vector__XXX
 SG_ DriverAlertnessLevel : 8|8@1+ (0.4,0) [0|100] "%" Vector__XXX
 SG_ DrvrAlertnessWarningSystemState : 16|3@1+ (1,0) [0|7] "" Vector__XXX
 SG_ LeftWheelLaneDepartureDistance : 24|8@1+ (1,-125) [-125|125] "cm" Vector__XXX
 SG_ RightWheelLaneDepartureDistance : 32|8@1+ (1,-125) [-125|125] "cm" Vector__XXX
 SG_ LaneDepartureWarningSystemState : 48|4@1+ (1,0) [0|15] "" Vector__XXX
 SG_ ForwardLaneImagerStatus : 52|4@1+ (1,0) [0|15] "" Vector__XXX

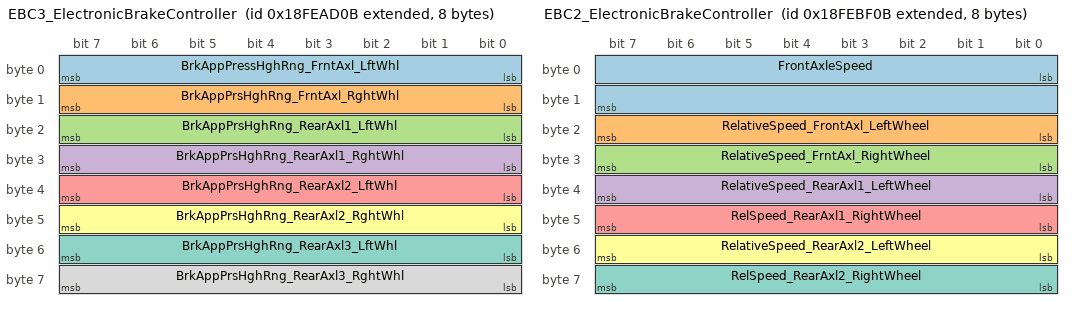
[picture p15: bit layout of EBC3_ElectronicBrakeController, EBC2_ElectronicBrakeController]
BO_ 2566827275 EBC3_ElectronicBrakeController: 8 Vector__XXX
 SG_ BrkAppPressHghRng_FrntAxl_LftWhl : 0|8@1+ (5,0) [0|1250] "kPa" Vector__XXX
 SG_ BrkAppPrsHghRng_FrntAxl_RghtWhl : 8|8@1+ (5,0) [0|1250] "kPa" Vector__XXX
 SG_ BrkAppPrsHghRng_RearAxl1_LftWhl : 16|8@1+ (5,0) [0|1250] "kPa" Vector__XXX
 SG_ BrkAppPrsHghRng_RearAxl1_RghtWhl : 24|8@1+ (5,0) [0|1250] "kPa" Vector__XXX
 SG_ BrkAppPrsHghRng_RearAxl2_LftWhl : 32|8@1+ (5,0) [0|1250] "kPa" Vector__XXX
 SG_ BrkAppPrsHghRng_RearAxl2_RghtWhl : 40|8@1+ (5,0) [0|1250] "kPa" Vector__XXX
 SG_ BrkAppPrsHghRng_RearAxl3_LftWhl : 48|8@1+ (5,0) [0|1250] "kPa" Vector__XXX
 SG_ BrkAppPrsHghRng_RearAxl3_RghtWhl : 56|8@1+ (5,0) [0|1250] "kPa" Vector__XXX

BO_ 2566831883 EBC2_ElectronicBrakeController: 8 Vector__XXX
 SG_ FrontAxleSpeed : 0|16@1+ (0.00390625,0) [0|250.99609375] "km/h" Vector__XXX
 SG_ RelativeSpeed_FrontAxl_LeftWheel : 16|8@1+ (0.0625,-7.8125) [-7.8125|7.8125] "km/h" Vector__XXX
 SG_ RelativeSpeed_FrntAxl_RightWheel : 24|8@1+ (0.0625,-7.8125) [-7.8125|7.8125] "km/h" Vector__XXX
 SG_ RelativeSpeed_RearAxl1_LeftWheel : 32|8@1+ (0.0625,-7.8125) [-7.8125|7.8125] "km/h" Vector__XXX
 SG_ RelSpeed_RearAxl1_RightWheel : 40|8@1+ (0.0625,-7.8125) [-7.8125|7.8125] "km/h" Vector__XXX
 SG_ RelativeSpeed_RearAxl2_LeftWheel : 48|8@1+ (0.0625,-7.8125) [-7.8125|7.8125] "km/h" Vector__XXX
 SG_ RelSpeed_RearAxl2_RightWheel : 56|8@1+ (0.0625,-7.8125) [-7.8125|7.8125] "km/h" Vector__XXX

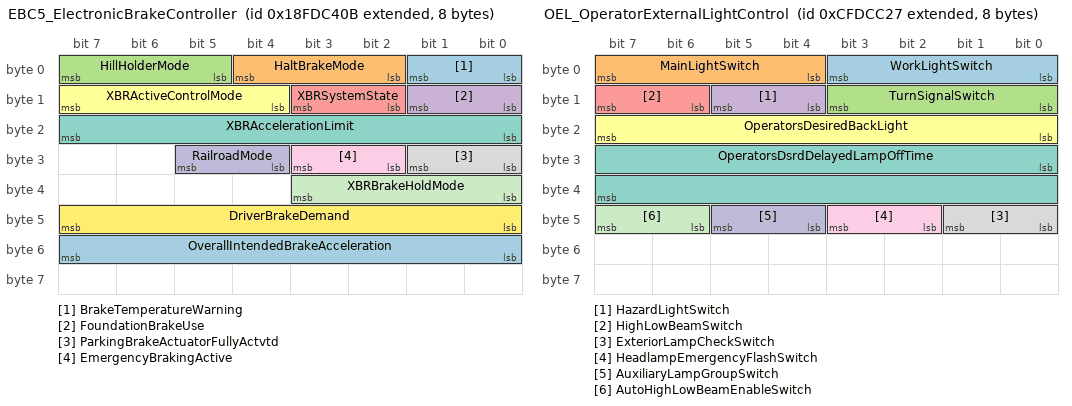
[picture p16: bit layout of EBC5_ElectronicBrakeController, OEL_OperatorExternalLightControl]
BO_ 2566767627 EBC5_ElectronicBrakeController: 8 Vector__XXX
 SG_ BrakeTemperatureWarning : 0|2@1+ (1,0) [0|3] "" Vector__XXX
 SG_ HaltBrakeMode : 2|3@1+ (1,0) [0|7] "" Vector__XXX
 SG_ HillHolderMode : 5|3@1+ (1,0) [0|7] "" Vector__XXX
 SG_ FoundationBrakeUse : 8|2@1+ (1,0) [0|3] "" Vector__XXX
 SG_ XBRSystemState : 10|2@1+ (1,0) [0|3] "" Vector__XXX
 SG_ XBRActiveControlMode : 12|4@1+ (1,0) [0|15] "" Vector__XXX
 SG_ XBRAccelerationLimit : 16|8@1+ (0.1,-12.5) [-12.5|12.5] "m/s^2" Vector__XXX
 SG_ ParkingBrakeActuatorFullyActvtd : 24|2@1+ (1,0) [0|3] "" Vector__XXX
 SG_ EmergencyBrakingActive : 26|2@1+ (1,0) [0|3] "" Vector__XXX
 SG_ RailroadMode : 28|2@1+ (1,0) [0|3] "" Vector__XXX
 SG_ XBRBrakeHoldMode : 32|4@1+ (1,0) [0|15] "" Vector__XXX
 SG_ DriverBrakeDemand : 40|8@1+ (0.1,-12.5) [-12.5|12.5] "m/s^2" Vector__XXX
 SG_ OverallIntendedBrakeAcceleration : 48|8@1+ (0.1,-12.5) [-12.5|12.5] "m/s^2" Vector__XXX

BO_ 2566844762 CCVS1_SourceAddress_5A: 8 Vector__XXX
 SG_ TwoSpeedAxleSwitch : 0|2@1+ (1,0) [0|3] "" Vector__XXX
 SG_ ParkingBrakeSwitch : 2|2@1+ (1,0) [0|3] "" Vector__XXX
 SG_ CruiseControlPauseSwitch : 4|2@1+ (1,0) [0|3] "" Vector__XXX
 SG_ ParkBrakeReleaseInhibitRequest : 6|2@1+ (1,0) [0|3] "" Vector__XXX
 SG_ WheelBasedVehicleSpeed : 8|16@1+ (0.00390625,0) [0|250.99609375] "km/h" Vector__XXX
 SG_ CruiseControlActive : 24|2@1+ (1,0) [0|3] "" Vector__XXX
 SG_ CruiseControlEnableSwitch : 26|2@1+ (1,0) [0|3] "" Vector__XXX
 SG_ BrakeSwitch_CCVS1_Signal : 28|2@1+ (1,0) [0|3] "" Vector__XXX
 SG_ ClutchSwitch : 30|2@1+ (1,0) [0|3] "" Vector__XXX
 SG_ CruiseControlSetSwitch : 32|2@1+ (1,0) [0|3] "" Vector__XXX
 SG_ CruiseControlCoastSwitch : 34|2@1+ (1,0) [0|3] "" Vector__XXX
 SG_ CruiseControlResumeSwitch : 36|2@1+ (1,0) [0|3] "" Vector__XXX
 SG_ CruiseControlAccelerateSwitch : 38|2@1+ (1,0) [0|3] "" Vector__XXX
 SG_ CruiseControlSetSpeed : 40|8@1+ (1,0) [0|250] "km/h" Vector__XXX
 SG_ PTOGovernorState : 48|5@1+ (1,0) [0|31] "" Vector__XXX
 SG_ CruiseControlStates : 53|3@1+ (1,0) [0|7] "" Vector__XXX
 SG_ EngineIdleIncrementSwitch : 56|2@1+ (1,0) [0|3] "" Vector__XXX
 SG_ EngineIdleDecrementSwitch : 58|2@1+ (1,0) [0|3] "" Vector__XXX
 SG_ EngineDiagnosticTestModeSwitch : 60|2@1+ (1,0) [0|3] "" Vector__XXX
 SG_ EngineShutdownOverrideSwitch : 62|2@1+ (1,0) [0|3] "" Vector__XXX

BO_ 2365443111 OEL_OperatorExternalLightControl: 8 Vector__XXX
 SG_ WorkLightSwitch : 0|4@1+ (1,0) [0|15] "" Vector__XXX
 SG_ MainLightSwitch : 4|4@1+ (1,0) [0|15] "" Vector__XXX
 SG_ TurnSignalSwitch : 8|4@1+ (1,0) [0|15] "" Vector__XXX
 SG_ HazardLightSwitch : 12|2@1+ (1,0) [0|3] "" Vector__XXX
 SG_ HighLowBeamSwitch : 14|2@1+ (1,0) [0|3] "" Vector__XXX
 SG_ OperatorsDesiredBackLight : 16|8@1+ (0.4,0) [0|100] "%" Vector__XXX
 SG_ OperatorsDsrdDelayedLampOffTime : 24|16@1+ (1,0) [0|64255] "s" Vector__XXX
 SG_ ExteriorLampCheckSwitch : 40|2@1+ (1,0) [0|3] "" Vector__XXX
 SG_ HeadlampEmergencyFlashSwitch : 42|2@1+ (1,0) [0|3] "" Vector__XXX
 SG_ AuxiliaryLampGroupSwitch : 44|2@1+ (1,0) [0|3] "" Vector__XXX
 SG_ AutoHighLowBeamEnableSwitch : 46|2@1+ (1,0) [0|3] "" Vector__XXX

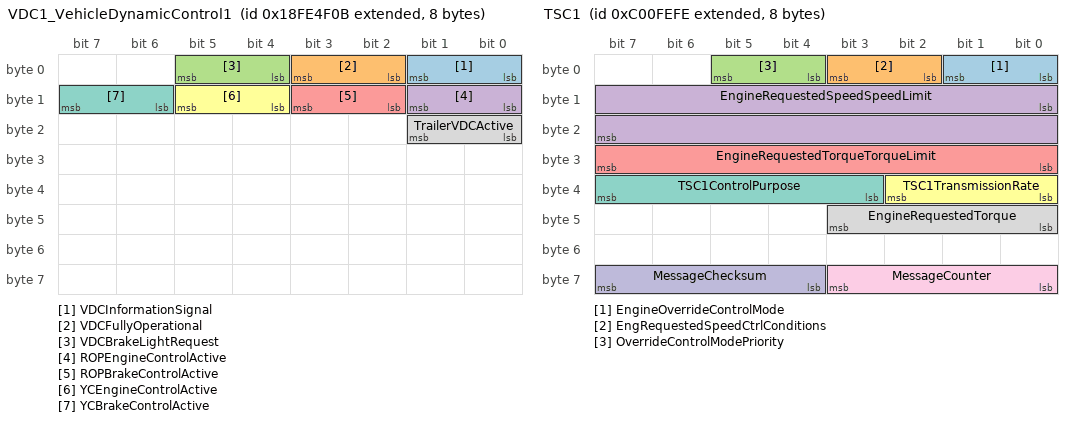
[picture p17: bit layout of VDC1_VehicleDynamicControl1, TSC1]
BO_ 2566803211 VDC1_VehicleDynamicControl1: 8 Vector__XXX
 SG_ VDCInformationSignal : 0|2@1+ (1,0) [0|3] "" Vector__XXX
 SG_ VDCFullyOperational : 2|2@1+ (1,0) [0|3] "" Vector__XXX
 SG_ VDCBrakeLightRequest : 4|2@1+ (1,0) [0|3] "" Vector__XXX
 SG_ ROPEngineControlActive : 8|2@1+ (1,0) [0|3] "" Vector__XXX
 SG_ ROPBrakeControlActive : 10|2@1+ (1,0) [0|3] "" Vector__XXX
 SG_ YCEngineControlActive : 12|2@1+ (1,0) [0|3] "" Vector__XXX
 SG_ YCBrakeControlActive : 14|2@1+ (1,0) [0|3] "" Vector__XXX
 SG_ TrailerVDCActive : 16|2@1+ (1,0) [0|3] "" Vector__XXX

BO_ 2566805807 ASC3_AirSuspensionControl3: 8 Vector__XXX
 SG_ RelativeLevelFrontAxleLeft : 0|16@1+ (0.1,-3200) [-3200|3225.5] "mm" Vector__XXX
 SG_ RelativeLevelFrontAxleRight : 16|16@1+ (0.1,-3200) [-3200|3225.5] "mm" Vector__XXX
 SG_ RelativeLevelRearAxleLeft : 32|16@1+ (0.1,-3200) [-3200|3225.5] "mm" Vector__XXX
 SG_ RelativeLevelRearAxleRight : 48|16@1+ (0.1,-3200) [-3200|3225.5] "mm" Vector__XXX

BO_ 2365479471 ASC1_AirSuspensionControl1: 8 Vector__XXX
 SG_ NominalLevelFrontAxle : 0|4@1+ (1,0) [0|15] "" Vector__XXX
 SG_ NominalLevelRearAxle : 4|4@1+ (1,0) [0|15] "" Vector__XXX
 SG_ BelowNominalLevelFrontAxle : 8|2@1+ (1,0) [0|3] "" Vector__XXX
 SG_ BelowNominalLevelRearAxle : 10|2@1+ (1,0) [0|3] "" Vector__XXX
 SG_ AboveNominalLevelFrontAxle : 12|2@1+ (1,0) [0|3] "" Vector__XXX
 SG_ AboveNominalLevelRearAxle : 14|2@1+ (1,0) [0|3] "" Vector__XXX
 SG_ LoweringControlModeFrontAxle : 16|2@1+ (1,0) [0|3] "" Vector__XXX
 SG_ LoweringControlModeRearAxle : 18|2@1+ (1,0) [0|3] "" Vector__XXX
 SG_ LiftingControlModeFrontAxle : 20|2@1+ (1,0) [0|3] "" Vector__XXX
 SG_ LiftingControlModeRearAxle : 22|2@1+ (1,0) [0|3] "" Vector__XXX
 SG_ KneelingInformation : 24|4@1+ (1,0) [0|15] "" Vector__XXX
 SG_ LevelControlMode : 28|4@1+ (1,0) [0|15] "" Vector__XXX
 SG_ SecurityDevice : 32|2@1+ (1,0) [0|3] "" Vector__XXX
 SG_ VehicleMotionInhibit : 34|2@1+ (1,0) [0|3] "" Vector__XXX
 SG_ DoorRelease : 36|2@1+ (1,0) [0|3] "" Vector__XXX
 SG_ LiftAxle1Position : 38|2@1+ (1,0) [0|3] "" Vector__XXX
 SG_ FrontAxleInBumperRange : 40|2@1+ (1,0) [0|3] "" Vector__XXX
 SG_ RearAxleInBumperRange : 42|2@1+ (1,0) [0|3] "" Vector__XXX
 SG_ LiftAxle2Position : 46|2@1+ (1,0) [0|3] "" Vector__XXX
 SG_ SuspensionRemoteControl1 : 48|2@1+ (1,0) [0|3] "" Vector__XXX
 SG_ SuspensionRemoteControl2 : 50|2@1+ (1,0) [0|3] "" Vector__XXX
 SG_ AllowLevelCtrlDuringBrkngStatus : 52|2@1+ (1,0) [0|3] "" Vector__XXX
 SG_ SpeedDependantLevelControlStatus : 54|2@1+ (1,0) [0|3] "" Vector__XXX
 SG_ SuspensionCtrlRefusalInformation : 56|4@1+ (1,0) [0|15] "" Vector__XXX
 SG_ MemoryLevel : 60|4@1+ (1,0) [0|15] "" Vector__XXX

BO_ 2348875518 TSC1: 8 Vector__XXX
 SG_ EngineOverrideControlMode : 0|2@1+ (1,0) [0|3] "" Vector__XXX
 SG_ EngRequestedSpeedCtrlConditions : 2|2@1+ (1,0) [0|3] "" Vector__XXX
 SG_ OverrideControlModePriority : 4|2@1+ (1,0) [0|3] "" Vector__XXX
 SG_ EngineRequestedSpeedSpeedLimit : 8|16@1+ (0.125,0) [0|8031.875] "rpm" Vector__XXX
 SG_ EngineRequestedTorqueTorqueLimit : 24|8@1+ (1,-125) [-125|125] "%" Vector__XXX
 SG_ TSC1TransmissionRate : 32|3@1+ (1,0) [0|7] "" Vector__XXX
 SG_ TSC1ControlPurpose : 35|5@1+ (1,0) [0|31] "" Vector__XXX
 SG_ EngineRequestedTorque : 40|4@1+ (0.125,0) [0|1.625] "%" Vector__XXX
 SG_ MessageCounter : 56|4@1+ (1,0) [0|15] "" Vector__XXX
 SG_ MessageChecksum : 60|4@1+ (1,0) [0|15] "" Vector__XXX

BO_ 2632711934 TPDT: 8 Vector__XXX
 SG_ SequenceNumber : 0|8@1+ (1,0) [0|255] "" Vector__XXX
 SG_ PacketizedData : 8|56@1+ (1,0) [0|7.20575940379279E+016] "" Vector__XXX

BO_ 2632777470 TPCM: 8 Vector__XXX
 SG_ TPCM_Mux M : 0|8@1+ (1,0) [0|0] "" Vector__XXX
 SG_ TotalMessageSize16 m16 : 8|16@1+ (1,0) [0|64255] "" Vector__XXX
 SG_ TotalNumberOfPackets16 m16 : 24|8@1+ (1,0) [0|255] "" Vector__XXX
 SG_ MaximumNumberOfPackets m16 : 32|8@1+ (1,0) [0|255] "" Vector__XXX
 SG_ PGNOfThePacketedMessage16 m16 : 40|24@1+ (1,0) [0|16777215] "" Vector__XXX
 SG_ NumberOfPacketsThatCanBeSent m17 : 8|8@1+ (1,0) [0|255] "" Vector__XXX
 SG_ NextPacketNumberToBeSent m17 : 16|8@1+ (1,0) [0|255] "" Vector__XXX
 SG_ PGNOfThePacketedMessage17 m17 : 40|24@1+ (1,0) [0|16777215] "" Vector__XXX
 SG_ TotalMessageSize19 m19 : 8|16@1+ (1,0) [0|64255] "" Vector__XXX
 SG_ TotalNumberOfPackets19 m19 : 24|8@1+ (1,0) [0|255] "" Vector__XXX
 SG_ PGNOfThePacketedMessage19 m19 : 40|24@1+ (1,0) [0|16777215] "" Vector__XXX
 SG_ TotalMessageSize32 m32 : 8|16@1+ (1,0) [0|64255] "" Vector__XXX
 SG_ TotalNumberOfPackets32 m32 : 24|8@1+ (1,0) [0|255] "" Vector__XXX
 SG_ PGNOfThePacketedMessage32 m32 : 40|24@1+ (1,0) [0|16777215] "" Vector__XXX
 SG_ ConnectionAbortReason m255 : 8|8@1+ (1,0) [0|255] "" Vector__XXX
 SG_ ParameterGrpNoOfPacketedMessage m255 : 40|24@1+ (1,0) [0|16777215] "" Vector__XXX

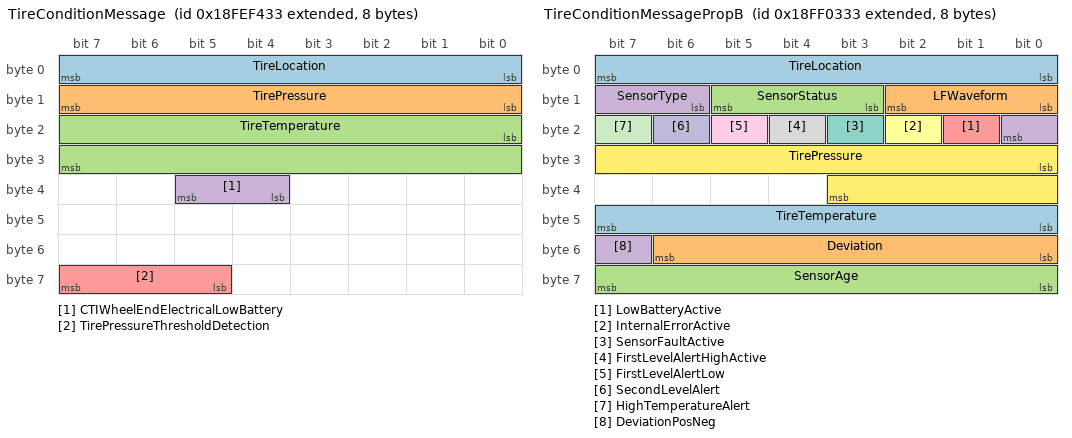
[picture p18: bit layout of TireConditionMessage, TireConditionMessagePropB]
BO_ 2566845491 TireConditionMessage: 8 Vector__XXX
 SG_ TireLocation : 0|8@1+ (1,0) [0|1] "" Vector__XXX
 SG_ TirePressure : 8|8@1+ (4,0) [0|1000] "kpa" Vector__XXX
 SG_ TireTemperature : 16|16@1+ (0.03125,-273) [-273|1735] "deg C" Vector__XXX
 SG_ CTIWheelEndElectricalLowBattery : 36|2@1+ (1,0) [0|1] "" Vector__XXX
 SG_ TirePressureThresholdDetection : 61|3@1+ (1,0) [0|1] "" Vector__XXX

BO_ 2566849331 TireConditionMessagePropB: 8 Vector__XXX
 SG_ TireLocation : 0|8@1+ (1,0) [0|1] "" Vector__XXX
 SG_ LFWaveform : 8|3@1+ (1,0) [0|1] "" Vector__XXX
 SG_ SensorStatus : 11|3@1+ (1,0) [0|1] "" Vector__XXX
 SG_ SensorType : 14|3@1+ (1,0) [0|1] "" Vector__XXX
 SG_ LowBatteryActive : 17|1@1+ (1,0) [0|1] "" Vector__XXX
 SG_ InternalErrorActive : 18|1@1+ (1,0) [0|1] "" Vector__XXX
 SG_ SensorFaultActive : 19|1@1+ (1,0) [0|1] "" Vector__XXX
 SG_ FirstLevelAlertHighActive : 20|1@1+ (1,0) [0|1] "" Vector__XXX
 SG_ FirstLevelAlertLow : 21|1@1+ (1,0) [0|1] "" Vector__XXX
 SG_ SecondLevelAlert : 22|1@1+ (1,0) [0|1] "" Vector__XXX
 SG_ HighTemperatureAlert : 23|1@1+ (1,0) [0|1] "" Vector__XXX
 SG_ TirePressure : 24|12@1+ (1,0) [0|4000] "kPa" Vector__XXX
 SG_ TireTemperature : 40|8@1+ (1,-40) [0|1] "Deg C" Vector__XXX
 SG_ Deviation : 48|7@1+ (4,0) [0|508] "kPa" Vector__XXX
 SG_ SensorAge : 56|8@1+ (1,0) [0|1] "Minutes" Vector__XXX
 SG_ DeviationPosNeg : 55|1@1+ (1,0) [0|1] "" Vector__XXX

BO_ 2566849587 FaultSettingMessage: 8 Vector__XXX

BO_ 2566849843 TrailerConnectionMessage: 8 Vector__XXX

BO_ 2566850355 DualTireImbalanceMessage: 8 Vector__XXX

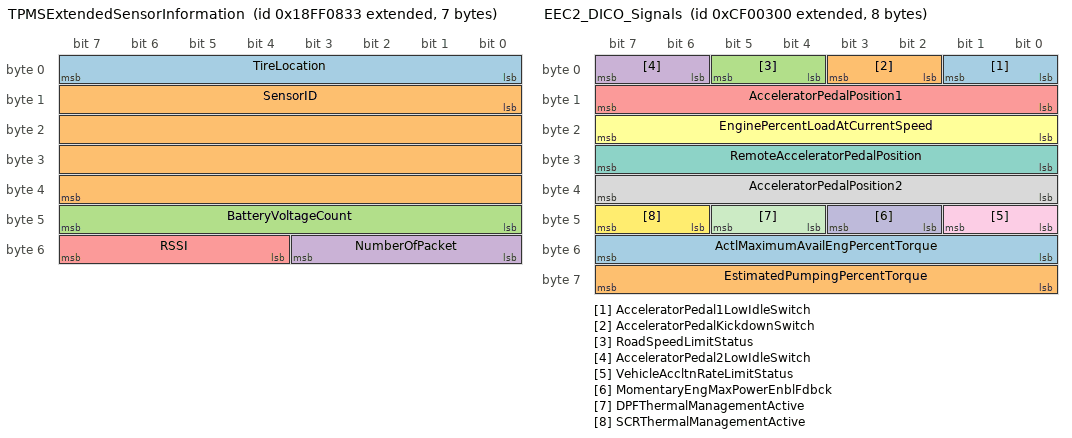
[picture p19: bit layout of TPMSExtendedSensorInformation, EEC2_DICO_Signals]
BO_ 2566850611 TPMSExtendedSensorInformation: 7 Vector__XXX
 SG_ TireLocation : 0|8@1+ (1,0) [0|1] "" Vector__XXX
 SG_ SensorID : 8|32@1+ (1,0) [0|1] "" Vector__XXX
 SG_ BatteryVoltageCount : 40|8@1+ (0.018,0) [0|1] "Vdc" Vector__XXX
 SG_ NumberOfPacket : 48|4@1+ (1,0) [0|1] "" Vector__XXX
 SG_ RSSI : 52|4@1+ (2,-110) [-110|-80] "dBm" Vector__XXX

BO_ 2566834735 DM01_Suspension_Controller: 50 Vector__XXX
 SG_ ProtectLamp : 0|2@1+ (1,0) [0|3] "" Vector__XXX
 SG_ AmberWarningLamp : 2|2@1+ (1,0) [0|3] "" Vector__XXX
 SG_ RedStopLamp : 4|2@1+ (1,0) [0|3] "" Vector__XXX
 SG_ MalfunctionIndicatorLamp : 6|2@1+ (1,0) [0|3] "" Vector__XXX
 SG_ FlashProtectLamp : 8|2@1+ (1,0) [0|3] "" Vector__XXX
 SG_ FlashAmberWarningLamp : 10|2@1+ (1,0) [0|3] "" Vector__XXX
 SG_ FlashRedStopLamp : 12|2@1+ (1,0) [0|3] "" Vector__XXX
 SG_ FlashMalfunctionIndicatorLamp : 14|2@1+ (1,0) [0|3] "" Vector__XXX
 SG_ SuspectParameterNumber : 23|19@0+ (1,0) [0|524287] "" Vector__XXX
 SG_ FailureModeIdentifier : 32|5@1+ (1,0) [0|31] "" Vector__XXX
 SG_ OccurrenceCount : 40|7@1+ (1,0) [0|127] "" Vector__XXX
 SG_ SPNConversionMethod : 47|1@1+ (1,0) [0|1] "" Vector__XXX
 SG_ SuspectParameterNumber2 : 55|19@0+ (1,0) [0|524287] "" Vector__XXX
 SG_ FailureModeIdentifier2 : 64|5@1+ (1,0) [0|31] "" Vector__XXX
 SG_ OccurrenceCount2 : 72|7@1+ (1,0) [0|127] "" Vector__XXX
 SG_ SPNConversionMethod2 : 79|1@1+ (1,0) [0|1] "" Vector__XXX
 SG_ SuspectParameterNumber3 : 87|19@0+ (1,0) [0|524287] "" Vector__XXX
 SG_ FailureModeIdentifier3 : 96|5@1+ (1,0) [0|31] "" Vector__XXX
 SG_ OccurrenceCount3 : 104|7@1+ (1,0) [0|127] "" Vector__XXX
 SG_ SPNConversionMethod3 : 111|1@1+ (1,0) [0|1] "" Vector__XXX
 SG_ SuspectParameterNumber4 : 119|19@0+ (1,0) [0|524287] "" Vector__XXX
 SG_ FailureModeIdentifier4 : 128|5@1+ (1,0) [0|31] "" Vector__XXX
 SG_ OccurrenceCount4 : 136|7@1+ (1,0) [0|127] "" Vector__XXX
 SG_ SPNConversionMethod4 : 143|1@1+ (1,0) [0|1] "" Vector__XXX
 SG_ SuspectParameterNumber5 : 151|19@0+ (1,0) [0|524287] "" Vector__XXX
 SG_ FailureModeIdentifier5 : 160|5@1+ (1,0) [0|31] "" Vector__XXX
 SG_ OccurrenceCount5 : 168|7@1+ (1,0) [0|127] "" Vector__XXX
 SG_ SPNConversionMethod5 : 175|1@1+ (1,0) [0|1] "" Vector__XXX
 SG_ SuspectParameterNumber6 : 183|19@0+ (1,0) [0|524287] "" Vector__XXX
 SG_ FailureModeIdentifier6 : 192|5@1+ (1,0) [0|31] "" Vector__XXX
 SG_ OccurrenceCount6 : 200|7@1+ (1,0) [0|127] "" Vector__XXX
 SG_ SPNConversionMethod6 : 207|1@1+ (1,0) [0|1] "" Vector__XXX
 SG_ SuspectParameterNumber7 : 215|19@0+ (1,0) [0|524287] "" Vector__XXX
 SG_ FailureModeIdentifier7 : 224|5@1+ (1,0) [0|31] "" Vector__XXX
 SG_ OccurrenceCount7 : 232|7@1+ (1,0) [0|127] "" Vector__XXX
 SG_ SPNConversionMethod7 : 239|1@1+ (1,0) [0|1] "" Vector__XXX
 SG_ SuspectParameterNumber8 : 247|19@0+ (1,0) [0|524287] "" Vector__XXX
 SG_ FailureModeIdentifier8 : 256|5@1+ (1,0) [0|31] "" Vector__XXX
 SG_ OccurrenceCount8 : 264|7@1+ (1,0) [0|127] "" Vector__XXX
 SG_ SPNConversionMethod8 : 271|1@1+ (1,0) [0|1] "" Vector__XXX
 SG_ SuspectParameterNumber9 : 279|19@0+ (1,0) [0|524287] "" Vector__XXX
 SG_ FailureModeIdentifier9 : 288|5@1+ (1,0) [0|31] "" Vector__XXX
 SG_ OccurrenceCount9 : 296|7@1+ (1,0) [0|127] "" Vector__XXX
 SG_ SPNConversionMethod9 : 303|1@1+ (1,0) [0|1] "" Vector__XXX
 SG_ SuspectParameterNumber10 : 311|19@0+ (1,0) [0|524287] "" Vector__XXX
 SG_ FailureModeIdentifier10 : 320|5@1+ (1,0) [0|31] "" Vector__XXX
 SG_ OccurrenceCount10 : 328|7@1+ (1,0) [0|127] "" Vector__XXX
 SG_ SPNConversionMethod10 : 335|1@1+ (1,0) [0|1] "" Vector__XXX
 SG_ SuspectParameterNumber11 : 343|19@0+ (1,0) [0|524287] "" Vector__XXX
 SG_ FailureModeIdentifier11 : 352|5@1+ (1,0) [0|31] "" Vector__XXX
 SG_ OccurrenceCount11 : 360|7@1+ (1,0) [0|127] "" Vector__XXX
 SG_ SPNConversionMethod11 : 367|1@1+ (1,0) [0|1] "" Vector__XXX
 SG_ SuspectParameterNumber12 : 375|19@0+ (1,0) [0|524287] "" Vector__XXX
 SG_ FailureModeIdentifier12 : 384|5@1+ (1,0) [0|31] "" Vector__XXX
 SG_ OccurrenceCount12 : 392|7@1+ (1,0) [0|127] "" Vector__XXX
 SG_ SPNConversionMethod12 : 399|1@1+ (1,0) [0|1] "" Vector__XXX

BO_ 2566834737 DM01_CabController_ZR: 50 Vector__XXX
 SG_ ProtectLamp : 0|2@1+ (1,0) [0|3] "" Vector__XXX
 SG_ AmberWarningLamp : 2|2@1+ (1,0) [0|3] "" Vector__XXX
 SG_ RedStopLamp : 4|2@1+ (1,0) [0|3] "" Vector__XXX
 SG_ MalfunctionIndicatorLamp : 6|2@1+ (1,0) [0|3] "" Vector__XXX
 SG_ FlashProtectLamp : 8|2@1+ (1,0) [0|3] "" Vector__XXX
 SG_ FlashAmberWarningLamp : 10|2@1+ (1,0) [0|3] "" Vector__XXX
 SG_ FlashRedStopLamp : 12|2@1+ (1,0) [0|3] "" Vector__XXX
 SG_ FlashMalfunctionIndicatorLamp : 14|2@1+ (1,0) [0|3] "" Vector__XXX
 SG_ SuspectParameterNumber : 23|19@0+ (1,0) [0|524287] "" Vector__XXX
 SG_ FailureModeIdentifier : 32|5@1+ (1,0) [0|31] "" Vector__XXX
 SG_ OccurrenceCount : 40|7@1+ (1,0) [0|127] "" Vector__XXX
 SG_ SPNConversionMethod : 47|1@1+ (1,0) [0|1] "" Vector__XXX
 SG_ SuspectParameterNumber2 : 55|19@0+ (1,0) [0|524287] "" Vector__XXX
 SG_ FailureModeIdentifier2 : 64|5@1+ (1,0) [0|31] "" Vector__XXX
 SG_ OccurrenceCount2 : 72|7@1+ (1,0) [0|127] "" Vector__XXX
 SG_ SPNConversionMethod2 : 79|1@1+ (1,0) [0|1] "" Vector__XXX
 SG_ SuspectParameterNumber3 : 87|19@0+ (1,0) [0|524287] "" Vector__XXX
 SG_ FailureModeIdentifier3 : 96|5@1+ (1,0) [0|31] "" Vector__XXX
 SG_ OccurrenceCount3 : 104|7@1+ (1,0) [0|127] "" Vector__XXX
 SG_ SPNConversionMethod3 : 111|1@1+ (1,0) [0|1] "" Vector__XXX
 SG_ SuspectParameterNumber4 : 119|19@0+ (1,0) [0|524287] "" Vector__XXX
 SG_ FailureModeIdentifier4 : 128|5@1+ (1,0) [0|31] "" Vector__XXX
 SG_ OccurrenceCount4 : 136|7@1+ (1,0) [0|127] "" Vector__XXX
 SG_ SPNConversionMethod4 : 143|1@1+ (1,0) [0|1] "" Vector__XXX
 SG_ SuspectParameterNumber5 : 151|19@0+ (1,0) [0|524287] "" Vector__XXX
 SG_ FailureModeIdentifier5 : 160|5@1+ (1,0) [0|31] "" Vector__XXX
 SG_ OccurrenceCount5 : 168|7@1+ (1,0) [0|127] "" Vector__XXX
 SG_ SPNConversionMethod5 : 175|1@1+ (1,0) [0|1] "" Vector__XXX
 SG_ SuspectParameterNumber6 : 183|19@0+ (1,0) [0|524287] "" Vector__XXX
 SG_ FailureModeIdentifier6 : 192|5@1+ (1,0) [0|31] "" Vector__XXX
 SG_ OccurrenceCount6 : 200|7@1+ (1,0) [0|127] "" Vector__XXX
 SG_ SPNConversionMethod6 : 207|1@1+ (1,0) [0|1] "" Vector__XXX
 SG_ SuspectParameterNumber7 : 215|19@0+ (1,0) [0|524287] "" Vector__XXX
 SG_ FailureModeIdentifier7 : 224|5@1+ (1,0) [0|31] "" Vector__XXX
 SG_ OccurrenceCount7 : 232|7@1+ (1,0) [0|127] "" Vector__XXX
 SG_ SPNConversionMethod7 : 239|1@1+ (1,0) [0|1] "" Vector__XXX
 SG_ SuspectParameterNumber8 : 247|19@0+ (1,0) [0|524287] "" Vector__XXX
 SG_ FailureModeIdentifier8 : 256|5@1+ (1,0) [0|31] "" Vector__XXX
 SG_ OccurrenceCount8 : 264|7@1+ (1,0) [0|127] "" Vector__XXX
 SG_ SPNConversionMethod8 : 271|1@1+ (1,0) [0|1] "" Vector__XXX
 SG_ SuspectParameterNumber9 : 279|19@0+ (1,0) [0|524287] "" Vector__XXX
 SG_ FailureModeIdentifier9 : 288|5@1+ (1,0) [0|31] "" Vector__XXX
 SG_ OccurrenceCount9 : 296|7@1+ (1,0) [0|127] "" Vector__XXX
 SG_ SPNConversionMethod9 : 303|1@1+ (1,0) [0|1] "" Vector__XXX
 SG_ SuspectParameterNumber10 : 311|19@0+ (1,0) [0|524287] "" Vector__XXX
 SG_ FailureModeIdentifier10 : 320|5@1+ (1,0) [0|31] "" Vector__XXX
 SG_ OccurrenceCount10 : 328|7@1+ (1,0) [0|127] "" Vector__XXX
 SG_ SPNConversionMethod10 : 335|1@1+ (1,0) [0|1] "" Vector__XXX
 SG_ SuspectParameterNumber11 : 343|19@0+ (1,0) [0|524287] "" Vector__XXX
 SG_ FailureModeIdentifier11 : 352|5@1+ (1,0) [0|31] "" Vector__XXX
 SG_ OccurrenceCount11 : 360|7@1+ (1,0) [0|127] "" Vector__XXX
 SG_ SPNConversionMethod11 : 367|1@1+ (1,0) [0|1] "" Vector__XXX
 SG_ SuspectParameterNumber12 : 375|19@0+ (1,0) [0|524287] "" Vector__XXX
 SG_ FailureModeIdentifier12 : 384|5@1+ (1,0) [0|31] "" Vector__XXX
 SG_ OccurrenceCount12 : 392|7@1+ (1,0) [0|127] "" Vector__XXX
 SG_ SPNConversionMethod12 : 399|1@1+ (1,0) [0|1] "" Vector__XXX

BO_ 2566834761 DM01_ChargeController: 50 Vector__XXX
 SG_ ProtectLamp : 0|2@1+ (1,0) [0|3] "" Vector__XXX
 SG_ AmberWarningLamp : 2|2@1+ (1,0) [0|3] "" Vector__XXX
 SG_ RedStopLamp : 4|2@1+ (1,0) [0|3] "" Vector__XXX
 SG_ MalfunctionIndicatorLamp : 6|2@1+ (1,0) [0|3] "" Vector__XXX
 SG_ FlashProtectLamp : 8|2@1+ (1,0) [0|3] "" Vector__XXX
 SG_ FlashAmberWarningLamp : 10|2@1+ (1,0) [0|3] "" Vector__XXX
 SG_ FlashRedStopLamp : 12|2@1+ (1,0) [0|3] "" Vector__XXX
 SG_ FlashMalfunctionIndicatorLamp : 14|2@1+ (1,0) [0|3] "" Vector__XXX
 SG_ SuspectParameterNumber : 23|19@0+ (1,0) [0|524287] "" Vector__XXX
 SG_ FailureModeIdentifier : 32|5@1+ (1,0) [0|31] "" Vector__XXX
 SG_ OccurrenceCount : 40|7@1+ (1,0) [0|127] "" Vector__XXX
 SG_ SPNConversionMethod : 47|1@1+ (1,0) [0|1] "" Vector__XXX
 SG_ SuspectParameterNumber2 : 55|19@0+ (1,0) [0|524287] "" Vector__XXX
 SG_ FailureModeIdentifier2 : 64|5@1+ (1,0) [0|31] "" Vector__XXX
 SG_ OccurrenceCount2 : 72|7@1+ (1,0) [0|127] "" Vector__XXX
 SG_ SPNConversionMethod2 : 79|1@1+ (1,0) [0|1] "" Vector__XXX
 SG_ SuspectParameterNumber3 : 87|19@0+ (1,0) [0|524287] "" Vector__XXX
 SG_ FailureModeIdentifier3 : 96|5@1+ (1,0) [0|31] "" Vector__XXX
 SG_ OccurrenceCount3 : 104|7@1+ (1,0) [0|127] "" Vector__XXX
 SG_ SPNConversionMethod3 : 111|1@1+ (1,0) [0|1] "" Vector__XXX
 SG_ SuspectParameterNumber4 : 119|19@0+ (1,0) [0|524287] "" Vector__XXX
 SG_ FailureModeIdentifier4 : 128|5@1+ (1,0) [0|31] "" Vector__XXX
 SG_ OccurrenceCount4 : 136|7@1+ (1,0) [0|127] "" Vector__XXX
 SG_ SPNConversionMethod4 : 143|1@1+ (1,0) [0|1] "" Vector__XXX
 SG_ SuspectParameterNumber5 : 151|19@0+ (1,0) [0|524287] "" Vector__XXX
 SG_ FailureModeIdentifier5 : 160|5@1+ (1,0) [0|31] "" Vector__XXX
 SG_ OccurrenceCount5 : 168|7@1+ (1,0) [0|127] "" Vector__XXX
 SG_ SPNConversionMethod5 : 175|1@1+ (1,0) [0|1] "" Vector__XXX
 SG_ SuspectParameterNumber6 : 183|19@0+ (1,0) [0|524287] "" Vector__XXX
 SG_ FailureModeIdentifier6 : 192|5@1+ (1,0) [0|31] "" Vector__XXX
 SG_ OccurrenceCount6 : 200|7@1+ (1,0) [0|127] "" Vector__XXX
 SG_ SPNConversionMethod6 : 207|1@1+ (1,0) [0|1] "" Vector__XXX
 SG_ SuspectParameterNumber7 : 215|19@0+ (1,0) [0|524287] "" Vector__XXX
 SG_ FailureModeIdentifier7 : 224|5@1+ (1,0) [0|31] "" Vector__XXX
 SG_ OccurrenceCount7 : 232|7@1+ (1,0) [0|127] "" Vector__XXX
 SG_ SPNConversionMethod7 : 239|1@1+ (1,0) [0|1] "" Vector__XXX
 SG_ SuspectParameterNumber8 : 247|19@0+ (1,0) [0|524287] "" Vector__XXX
 SG_ FailureModeIdentifier8 : 256|5@1+ (1,0) [0|31] "" Vector__XXX
 SG_ OccurrenceCount8 : 264|7@1+ (1,0) [0|127] "" Vector__XXX
 SG_ SPNConversionMethod8 : 271|1@1+ (1,0) [0|1] "" Vector__XXX
 SG_ SuspectParameterNumber9 : 279|19@0+ (1,0) [0|524287] "" Vector__XXX
 SG_ FailureModeIdentifier9 : 288|5@1+ (1,0) [0|31] "" Vector__XXX
 SG_ OccurrenceCount9 : 296|7@1+ (1,0) [0|127] "" Vector__XXX
 SG_ SPNConversionMethod9 : 303|1@1+ (1,0) [0|1] "" Vector__XXX
 SG_ SuspectParameterNumber10 : 311|19@0+ (1,0) [0|524287] "" Vector__XXX
 SG_ FailureModeIdentifier10 : 320|5@1+ (1,0) [0|31] "" Vector__XXX
 SG_ OccurrenceCount10 : 328|7@1+ (1,0) [0|127] "" Vector__XXX
 SG_ SPNConversionMethod10 : 335|1@1+ (1,0) [0|1] "" Vector__XXX
 SG_ SuspectParameterNumber11 : 343|19@0+ (1,0) [0|524287] "" Vector__XXX
 SG_ FailureModeIdentifier11 : 352|5@1+ (1,0) [0|31] "" Vector__XXX
 SG_ OccurrenceCount11 : 360|7@1+ (1,0) [0|127] "" Vector__XXX
 SG_ SPNConversionMethod11 : 367|1@1+ (1,0) [0|1] "" Vector__XXX
 SG_ SuspectParameterNumber12 : 375|19@0+ (1,0) [0|524287] "" Vector__XXX
 SG_ FailureModeIdentifier12 : 384|5@1+ (1,0) [0|31] "" Vector__XXX
 SG_ OccurrenceCount12 : 392|7@1+ (1,0) [0|127] "" Vector__XXX
 SG_ SPNConversionMethod12 : 399|1@1+ (1,0) [0|1] "" Vector__XXX

BO_ 2566834691 DM01_Siemens_DICO: 50 Vector__XXX
 SG_ ProtectLamp : 0|2@1+ (1,0) [0|3] "" Vector__XXX
 SG_ AmberWarningLamp : 2|2@1+ (1,0) [0|3] "" Vector__XXX
 SG_ RedStopLamp : 4|2@1+ (1,0) [0|3] "" Vector__XXX
 SG_ MalfunctionIndicatorLamp : 6|2@1+ (1,0) [0|3] "" Vector__XXX
 SG_ FlashProtectLamp : 8|2@1+ (1,0) [0|3] "" Vector__XXX
 SG_ FlashAmberWarningLamp : 10|2@1+ (1,0) [0|3] "" Vector__XXX
 SG_ FlashRedStopLamp : 12|2@1+ (1,0) [0|3] "" Vector__XXX
 SG_ FlashMalfunctionIndicatorLamp : 14|2@1+ (1,0) [0|3] "" Vector__XXX
 SG_ SuspectParameterNumber : 23|19@0+ (1,0) [0|524287] "" Vector__XXX
 SG_ FailureModeIdentifier : 32|5@1+ (1,0) [0|31] "" Vector__XXX
 SG_ OccurrenceCount : 40|7@1+ (1,0) [0|127] "" Vector__XXX
 SG_ SPNConversionMethod : 47|1@1+ (1,0) [0|1] "" Vector__XXX
 SG_ SuspectParameterNumber2 : 55|19@0+ (1,0) [0|524287] "" Vector__XXX
 SG_ FailureModeIdentifier2 : 64|5@1+ (1,0) [0|31] "" Vector__XXX
 SG_ OccurrenceCount2 : 72|7@1+ (1,0) [0|127] "" Vector__XXX
 SG_ SPNConversionMethod2 : 79|1@1+ (1,0) [0|1] "" Vector__XXX
 SG_ SuspectParameterNumber3 : 87|19@0+ (1,0) [0|524287] "" Vector__XXX
 SG_ FailureModeIdentifier3 : 96|5@1+ (1,0) [0|31] "" Vector__XXX
 SG_ OccurrenceCount3 : 104|7@1+ (1,0) [0|127] "" Vector__XXX
 SG_ SPNConversionMethod3 : 111|1@1+ (1,0) [0|1] "" Vector__XXX
 SG_ SuspectParameterNumber4 : 119|19@0+ (1,0) [0|524287] "" Vector__XXX
 SG_ FailureModeIdentifier4 : 128|5@1+ (1,0) [0|31] "" Vector__XXX
 SG_ OccurrenceCount4 : 136|7@1+ (1,0) [0|127] "" Vector__XXX
 SG_ SPNConversionMethod4 : 143|1@1+ (1,0) [0|1] "" Vector__XXX
 SG_ SuspectParameterNumber5 : 151|19@0+ (1,0) [0|524287] "" Vector__XXX
 SG_ FailureModeIdentifier5 : 160|5@1+ (1,0) [0|31] "" Vector__XXX
 SG_ OccurrenceCount5 : 168|7@1+ (1,0) [0|127] "" Vector__XXX
 SG_ SPNConversionMethod5 : 175|1@1+ (1,0) [0|1] "" Vector__XXX
 SG_ SuspectParameterNumber6 : 183|19@0+ (1,0) [0|524287] "" Vector__XXX
 SG_ FailureModeIdentifier6 : 192|5@1+ (1,0) [0|31] "" Vector__XXX
 SG_ OccurrenceCount6 : 200|7@1+ (1,0) [0|127] "" Vector__XXX
 SG_ SPNConversionMethod6 : 207|1@1+ (1,0) [0|1] "" Vector__XXX
 SG_ SuspectParameterNumber7 : 215|19@0+ (1,0) [0|524287] "" Vector__XXX
 SG_ FailureModeIdentifier7 : 224|5@1+ (1,0) [0|31] "" Vector__XXX
 SG_ OccurrenceCount7 : 232|7@1+ (1,0) [0|127] "" Vector__XXX
 SG_ SPNConversionMethod7 : 239|1@1+ (1,0) [0|1] "" Vector__XXX
 SG_ SuspectParameterNumber8 : 247|19@0+ (1,0) [0|524287] "" Vector__XXX
 SG_ FailureModeIdentifier8 : 256|5@1+ (1,0) [0|31] "" Vector__XXX
 SG_ OccurrenceCount8 : 264|7@1+ (1,0) [0|127] "" Vector__XXX
 SG_ SPNConversionMethod8 : 271|1@1+ (1,0) [0|1] "" Vector__XXX
 SG_ SuspectParameterNumber9 : 279|19@0+ (1,0) [0|524287] "" Vector__XXX
 SG_ FailureModeIdentifier9 : 288|5@1+ (1,0) [0|31] "" Vector__XXX
 SG_ OccurrenceCount9 : 296|7@1+ (1,0) [0|127] "" Vector__XXX
 SG_ SPNConversionMethod9 : 303|1@1+ (1,0) [0|1] "" Vector__XXX
 SG_ SuspectParameterNumber10 : 311|19@0+ (1,0) [0|524287] "" Vector__XXX
 SG_ FailureModeIdentifier10 : 320|5@1+ (1,0) [0|31] "" Vector__XXX
 SG_ OccurrenceCount10 : 328|7@1+ (1,0) [0|127] "" Vector__XXX
 SG_ SPNConversionMethod10 : 335|1@1+ (1,0) [0|1] "" Vector__XXX
 SG_ SuspectParameterNumber11 : 343|19@0+ (1,0) [0|524287] "" Vector__XXX
 SG_ FailureModeIdentifier11 : 352|5@1+ (1,0) [0|31] "" Vector__XXX
 SG_ OccurrenceCount11 : 360|7@1+ (1,0) [0|127] "" Vector__XXX
 SG_ SPNConversionMethod11 : 367|1@1+ (1,0) [0|1] "" Vector__XXX
 SG_ SuspectParameterNumber12 : 375|19@0+ (1,0) [0|524287] "" Vector__XXX
 SG_ FailureModeIdentifier12 : 384|5@1+ (1,0) [0|31] "" Vector__XXX
 SG_ OccurrenceCount12 : 392|7@1+ (1,0) [0|127] "" Vector__XXX
 SG_ SPNConversionMethod12 : 399|1@1+ (1,0) [0|1] "" Vector__XXX

BO_ 2566834920 DM01_LaneDepartureCamera: 50 Vector__XXX
 SG_ ProtectLamp : 0|2@1+ (1,0) [0|3] "" Vector__XXX
 SG_ AmberWarningLamp : 2|2@1+ (1,0) [0|3] "" Vector__XXX
 SG_ RedStopLamp : 4|2@1+ (1,0) [0|3] "" Vector__XXX
 SG_ MalfunctionIndicatorLamp : 6|2@1+ (1,0) [0|3] "" Vector__XXX
 SG_ FlashProtectLamp : 8|2@1+ (1,0) [0|3] "" Vector__XXX
 SG_ FlashAmberWarningLamp : 10|2@1+ (1,0) [0|3] "" Vector__XXX
 SG_ FlashRedStopLamp : 12|2@1+ (1,0) [0|3] "" Vector__XXX
 SG_ FlashMalfunctionIndicatorLamp : 14|2@1+ (1,0) [0|3] "" Vector__XXX
 SG_ SuspectParameterNumber : 23|19@0+ (1,0) [0|524287] "" Vector__XXX
 SG_ FailureModeIdentifier : 32|5@1+ (1,0) [0|31] "" Vector__XXX
 SG_ OccurrenceCount : 40|7@1+ (1,0) [0|127] "" Vector__XXX
 SG_ SPNConversionMethod : 47|1@1+ (1,0) [0|1] "" Vector__XXX
 SG_ SuspectParameterNumber2 : 55|19@0+ (1,0) [0|524287] "" Vector__XXX
 SG_ FailureModeIdentifier2 : 64|5@1+ (1,0) [0|31] "" Vector__XXX
 SG_ OccurrenceCount2 : 72|7@1+ (1,0) [0|127] "" Vector__XXX
 SG_ SPNConversionMethod2 : 79|1@1+ (1,0) [0|1] "" Vector__XXX
 SG_ SuspectParameterNumber3 : 87|19@0+ (1,0) [0|524287] "" Vector__XXX
 SG_ FailureModeIdentifier3 : 96|5@1+ (1,0) [0|31] "" Vector__XXX
 SG_ OccurrenceCount3 : 104|7@1+ (1,0) [0|127] "" Vector__XXX
 SG_ SPNConversionMethod3 : 111|1@1+ (1,0) [0|1] "" Vector__XXX
 SG_ SuspectParameterNumber4 : 119|19@0+ (1,0) [0|524287] "" Vector__XXX
 SG_ FailureModeIdentifier4 : 128|5@1+ (1,0) [0|31] "" Vector__XXX
 SG_ OccurrenceCount4 : 136|7@1+ (1,0) [0|127] "" Vector__XXX
 SG_ SPNConversionMethod4 : 143|1@1+ (1,0) [0|1] "" Vector__XXX
 SG_ SuspectParameterNumber5 : 151|19@0+ (1,0) [0|524287] "" Vector__XXX
 SG_ FailureModeIdentifier5 : 160|5@1+ (1,0) [0|31] "" Vector__XXX
 SG_ OccurrenceCount5 : 168|7@1+ (1,0) [0|127] "" Vector__XXX
 SG_ SPNConversionMethod5 : 175|1@1+ (1,0) [0|1] "" Vector__XXX
 SG_ SuspectParameterNumber6 : 183|19@0+ (1,0) [0|524287] "" Vector__XXX
 SG_ FailureModeIdentifier6 : 192|5@1+ (1,0) [0|31] "" Vector__XXX
 SG_ OccurrenceCount6 : 200|7@1+ (1,0) [0|127] "" Vector__XXX
 SG_ SPNConversionMethod6 : 207|1@1+ (1,0) [0|1] "" Vector__XXX
 SG_ SuspectParameterNumber7 : 215|19@0+ (1,0) [0|524287] "" Vector__XXX
 SG_ FailureModeIdentifier7 : 224|5@1+ (1,0) [0|31] "" Vector__XXX
 SG_ OccurrenceCount7 : 232|7@1+ (1,0) [0|127] "" Vector__XXX
 SG_ SPNConversionMethod7 : 239|1@1+ (1,0) [0|1] "" Vector__XXX
 SG_ SuspectParameterNumber8 : 247|19@0+ (1,0) [0|524287] "" Vector__XXX
 SG_ FailureModeIdentifier8 : 256|5@1+ (1,0) [0|31] "" Vector__XXX
 SG_ OccurrenceCount8 : 264|7@1+ (1,0) [0|127] "" Vector__XXX
 SG_ SPNConversionMethod8 : 271|1@1+ (1,0) [0|1] "" Vector__XXX
 SG_ SuspectParameterNumber9 : 279|19@0+ (1,0) [0|524287] "" Vector__XXX
 SG_ FailureModeIdentifier9 : 288|5@1+ (1,0) [0|31] "" Vector__XXX
 SG_ OccurrenceCount9 : 296|7@1+ (1,0) [0|127] "" Vector__XXX
 SG_ SPNConversionMethod9 : 303|1@1+ (1,0) [0|1] "" Vector__XXX
 SG_ SuspectParameterNumber10 : 311|19@0+ (1,0) [0|524287] "" Vector__XXX
 SG_ FailureModeIdentifier10 : 320|5@1+ (1,0) [0|31] "" Vector__XXX
 SG_ OccurrenceCount10 : 328|7@1+ (1,0) [0|127] "" Vector__XXX
 SG_ SPNConversionMethod10 : 335|1@1+ (1,0) [0|1] "" Vector__XXX
 SG_ SuspectParameterNumber11 : 343|19@0+ (1,0) [0|524287] "" Vector__XXX
 SG_ FailureModeIdentifier11 : 352|5@1+ (1,0) [0|31] "" Vector__XXX
 SG_ OccurrenceCount11 : 360|7@1+ (1,0) [0|127] "" Vector__XXX
 SG_ SPNConversionMethod11 : 367|1@1+ (1,0) [0|1] "" Vector__XXX
 SG_ SuspectParameterNumber12 : 375|19@0+ (1,0) [0|524287] "" Vector__XXX
 SG_ FailureModeIdentifier12 : 384|5@1+ (1,0) [0|31] "" Vector__XXX
 SG_ OccurrenceCount12 : 392|7@1+ (1,0) [0|127] "" Vector__XXX
 SG_ SPNConversionMethod12 : 399|1@1+ (1,0) [0|1] "" Vector__XXX

BO_ 2566834734 DM01_Power_Steering_Controller: 50 Vector__XXX
 SG_ ProtectLamp : 0|2@1+ (1,0) [0|3] "" Vector__XXX
 SG_ AmberWarningLamp : 2|2@1+ (1,0) [0|3] "" Vector__XXX
 SG_ RedStopLamp : 4|2@1+ (1,0) [0|3] "" Vector__XXX
 SG_ MalfunctionIndicatorLamp : 6|2@1+ (1,0) [0|3] "" Vector__XXX
 SG_ FlashProtectLamp : 8|2@1+ (1,0) [0|3] "" Vector__XXX
 SG_ FlashAmberWarningLamp : 10|2@1+ (1,0) [0|3] "" Vector__XXX
 SG_ FlashRedStopLamp : 12|2@1+ (1,0) [0|3] "" Vector__XXX
 SG_ FlashMalfunctionIndicatorLamp : 14|2@1+ (1,0) [0|3] "" Vector__XXX
 SG_ SuspectParameterNumber : 23|19@0+ (1,0) [0|524287] "" Vector__XXX
 SG_ FailureModeIdentifier : 32|5@1+ (1,0) [0|31] "" Vector__XXX
 SG_ OccurrenceCount : 40|7@1+ (1,0) [0|127] "" Vector__XXX
 SG_ SPNConversionMethod : 47|1@1+ (1,0) [0|1] "" Vector__XXX
 SG_ SuspectParameterNumber2 : 55|19@0+ (1,0) [0|524287] "" Vector__XXX
 SG_ FailureModeIdentifier2 : 64|5@1+ (1,0) [0|31] "" Vector__XXX
 SG_ OccurrenceCount2 : 72|7@1+ (1,0) [0|127] "" Vector__XXX
 SG_ SPNConversionMethod2 : 79|1@1+ (1,0) [0|1] "" Vector__XXX
 SG_ SuspectParameterNumber3 : 87|19@0+ (1,0) [0|524287] "" Vector__XXX
 SG_ FailureModeIdentifier3 : 96|5@1+ (1,0) [0|31] "" Vector__XXX
 SG_ OccurrenceCount3 : 104|7@1+ (1,0) [0|127] "" Vector__XXX
 SG_ SPNConversionMethod3 : 111|1@1+ (1,0) [0|1] "" Vector__XXX
 SG_ SuspectParameterNumber4 : 119|19@0+ (1,0) [0|524287] "" Vector__XXX
 SG_ FailureModeIdentifier4 : 128|5@1+ (1,0) [0|31] "" Vector__XXX
 SG_ OccurrenceCount4 : 136|7@1+ (1,0) [0|127] "" Vector__XXX
 SG_ SPNConversionMethod4 : 143|1@1+ (1,0) [0|1] "" Vector__XXX
 SG_ SuspectParameterNumber5 : 151|19@0+ (1,0) [0|524287] "" Vector__XXX
 SG_ FailureModeIdentifier5 : 160|5@1+ (1,0) [0|31] "" Vector__XXX
 SG_ OccurrenceCount5 : 168|7@1+ (1,0) [0|127] "" Vector__XXX
 SG_ SPNConversionMethod5 : 175|1@1+ (1,0) [0|1] "" Vector__XXX
 SG_ SuspectParameterNumber6 : 183|19@0+ (1,0) [0|524287] "" Vector__XXX
 SG_ FailureModeIdentifier6 : 192|5@1+ (1,0) [0|31] "" Vector__XXX
 SG_ OccurrenceCount6 : 200|7@1+ (1,0) [0|127] "" Vector__XXX
 SG_ SPNConversionMethod6 : 207|1@1+ (1,0) [0|1] "" Vector__XXX
 SG_ SuspectParameterNumber7 : 215|19@0+ (1,0) [0|524287] "" Vector__XXX
 SG_ FailureModeIdentifier7 : 224|5@1+ (1,0) [0|31] "" Vector__XXX
 SG_ OccurrenceCount7 : 232|7@1+ (1,0) [0|127] "" Vector__XXX
 SG_ SPNConversionMethod7 : 239|1@1+ (1,0) [0|1] "" Vector__XXX
 SG_ SuspectParameterNumber8 : 247|19@0+ (1,0) [0|524287] "" Vector__XXX
 SG_ FailureModeIdentifier8 : 256|5@1+ (1,0) [0|31] "" Vector__XXX
 SG_ OccurrenceCount8 : 264|7@1+ (1,0) [0|127] "" Vector__XXX
 SG_ SPNConversionMethod8 : 271|1@1+ (1,0) [0|1] "" Vector__XXX
 SG_ SuspectParameterNumber9 : 279|19@0+ (1,0) [0|524287] "" Vector__XXX
 SG_ FailureModeIdentifier9 : 288|5@1+ (1,0) [0|31] "" Vector__XXX
 SG_ OccurrenceCount9 : 296|7@1+ (1,0) [0|127] "" Vector__XXX
 SG_ SPNConversionMethod9 : 303|1@1+ (1,0) [0|1] "" Vector__XXX
 SG_ SuspectParameterNumber10 : 311|19@0+ (1,0) [0|524287] "" Vector__XXX
 SG_ FailureModeIdentifier10 : 320|5@1+ (1,0) [0|31] "" Vector__XXX
 SG_ OccurrenceCount10 : 328|7@1+ (1,0) [0|127] "" Vector__XXX
 SG_ SPNConversionMethod10 : 335|1@1+ (1,0) [0|1] "" Vector__XXX
 SG_ SuspectParameterNumber11 : 343|19@0+ (1,0) [0|524287] "" Vector__XXX
 SG_ FailureModeIdentifier11 : 352|5@1+ (1,0) [0|31] "" Vector__XXX
 SG_ OccurrenceCount11 : 360|7@1+ (1,0) [0|127] "" Vector__XXX
 SG_ SPNConversionMethod11 : 367|1@1+ (1,0) [0|1] "" Vector__XXX
 SG_ SuspectParameterNumber12 : 375|19@0+ (1,0) [0|524287] "" Vector__XXX
 SG_ FailureModeIdentifier12 : 384|5@1+ (1,0) [0|31] "" Vector__XXX
 SG_ OccurrenceCount12 : 392|7@1+ (1,0) [0|127] "" Vector__XXX
 SG_ SPNConversionMethod12 : 399|1@1+ (1,0) [0|1] "" Vector__XXX

BO_ 2566834690 DM01_ESM_Controller: 50 Vector__XXX
 SG_ ProtectLamp : 0|2@1+ (1,0) [0|3] "" Vector__XXX
 SG_ AmberWarningLamp : 2|2@1+ (1,0) [0|3] "" Vector__XXX
 SG_ RedStopLamp : 4|2@1+ (1,0) [0|3] "" Vector__XXX
 SG_ MalfunctionIndicatorLamp : 6|2@1+ (1,0) [0|3] "" Vector__XXX
 SG_ FlashProtectLamp : 8|2@1+ (1,0) [0|3] "" Vector__XXX
 SG_ FlashAmberWarningLamp : 10|2@1+ (1,0) [0|3] "" Vector__XXX
 SG_ FlashRedStopLamp : 12|2@1+ (1,0) [0|3] "" Vector__XXX
 SG_ FlashMalfunctionIndicatorLamp : 14|2@1+ (1,0) [0|3] "" Vector__XXX
 SG_ SuspectParameterNumber : 23|19@0+ (1,0) [0|524287] "" Vector__XXX
 SG_ FailureModeIdentifier : 32|5@1+ (1,0) [0|31] "" Vector__XXX
 SG_ OccurrenceCount : 40|7@1+ (1,0) [0|127] "" Vector__XXX
 SG_ SPNConversionMethod : 47|1@1+ (1,0) [0|1] "" Vector__XXX
 SG_ SuspectParameterNumber2 : 55|19@0+ (1,0) [0|524287] "" Vector__XXX
 SG_ FailureModeIdentifier2 : 64|5@1+ (1,0) [0|31] "" Vector__XXX
 SG_ OccurrenceCount2 : 72|7@1+ (1,0) [0|127] "" Vector__XXX
 SG_ SPNConversionMethod2 : 79|1@1+ (1,0) [0|1] "" Vector__XXX
 SG_ SuspectParameterNumber3 : 87|19@0+ (1,0) [0|524287] "" Vector__XXX
 SG_ FailureModeIdentifier3 : 96|5@1+ (1,0) [0|31] "" Vector__XXX
 SG_ OccurrenceCount3 : 104|7@1+ (1,0) [0|127] "" Vector__XXX
 SG_ SPNConversionMethod3 : 111|1@1+ (1,0) [0|1] "" Vector__XXX
 SG_ SuspectParameterNumber4 : 119|19@0+ (1,0) [0|524287] "" Vector__XXX
 SG_ FailureModeIdentifier4 : 128|5@1+ (1,0) [0|31] "" Vector__XXX
 SG_ OccurrenceCount4 : 136|7@1+ (1,0) [0|127] "" Vector__XXX
 SG_ SPNConversionMethod4 : 143|1@1+ (1,0) [0|1] "" Vector__XXX
 SG_ SuspectParameterNumber5 : 151|19@0+ (1,0) [0|524287] "" Vector__XXX
 SG_ FailureModeIdentifier5 : 160|5@1+ (1,0) [0|31] "" Vector__XXX
 SG_ OccurrenceCount5 : 168|7@1+ (1,0) [0|127] "" Vector__XXX
 SG_ SPNConversionMethod5 : 175|1@1+ (1,0) [0|1] "" Vector__XXX
 SG_ SuspectParameterNumber6 : 183|19@0+ (1,0) [0|524287] "" Vector__XXX
 SG_ FailureModeIdentifier6 : 192|5@1+ (1,0) [0|31] "" Vector__XXX
 SG_ OccurrenceCount6 : 200|7@1+ (1,0) [0|127] "" Vector__XXX
 SG_ SPNConversionMethod6 : 207|1@1+ (1,0) [0|1] "" Vector__XXX
 SG_ SuspectParameterNumber7 : 215|19@0+ (1,0) [0|524287] "" Vector__XXX
 SG_ FailureModeIdentifier7 : 224|5@1+ (1,0) [0|31] "" Vector__XXX
 SG_ OccurrenceCount7 : 232|7@1+ (1,0) [0|127] "" Vector__XXX
 SG_ SPNConversionMethod7 : 239|1@1+ (1,0) [0|1] "" Vector__XXX
 SG_ SuspectParameterNumber8 : 247|19@0+ (1,0) [0|524287] "" Vector__XXX
 SG_ FailureModeIdentifier8 : 256|5@1+ (1,0) [0|31] "" Vector__XXX
 SG_ OccurrenceCount8 : 264|7@1+ (1,0) [0|127] "" Vector__XXX
 SG_ SPNConversionMethod8 : 271|1@1+ (1,0) [0|1] "" Vector__XXX
 SG_ SuspectParameterNumber9 : 279|19@0+ (1,0) [0|524287] "" Vector__XXX
 SG_ FailureModeIdentifier9 : 288|5@1+ (1,0) [0|31] "" Vector__XXX
 SG_ OccurrenceCount9 : 296|7@1+ (1,0) [0|127] "" Vector__XXX
 SG_ SPNConversionMethod9 : 303|1@1+ (1,0) [0|1] "" Vector__XXX
 SG_ SuspectParameterNumber10 : 311|19@0+ (1,0) [0|524287] "" Vector__XXX
 SG_ FailureModeIdentifier10 : 320|5@1+ (1,0) [0|31] "" Vector__XXX
 SG_ OccurrenceCount10 : 328|7@1+ (1,0) [0|127] "" Vector__XXX
 SG_ SPNConversionMethod10 : 335|1@1+ (1,0) [0|1] "" Vector__XXX
 SG_ SuspectParameterNumber11 : 343|19@0+ (1,0) [0|524287] "" Vector__XXX
 SG_ FailureModeIdentifier11 : 352|5@1+ (1,0) [0|31] "" Vector__XXX
 SG_ OccurrenceCount11 : 360|7@1+ (1,0) [0|127] "" Vector__XXX
 SG_ SPNConversionMethod11 : 367|1@1+ (1,0) [0|1] "" Vector__XXX
 SG_ SuspectParameterNumber12 : 375|19@0+ (1,0) [0|524287] "" Vector__XXX
 SG_ FailureModeIdentifier12 : 384|5@1+ (1,0) [0|31] "" Vector__XXX
 SG_ OccurrenceCount12 : 392|7@1+ (1,0) [0|127] "" Vector__XXX
 SG_ SPNConversionMethod12 : 399|1@1+ (1,0) [0|1] "" Vector__XXX

BO_ 2566834711 DM01_Instrument_Cluster: 50 Vector__XXX
 SG_ ProtectLamp : 0|2@1+ (1,0) [0|3] "" Vector__XXX
 SG_ AmberWarningLamp : 2|2@1+ (1,0) [0|3] "" Vector__XXX
 SG_ RedStopLamp : 4|2@1+ (1,0) [0|3] "" Vector__XXX
 SG_ MalfunctionIndicatorLamp : 6|2@1+ (1,0) [0|3] "" Vector__XXX
 SG_ FlashProtectLamp : 8|2@1+ (1,0) [0|3] "" Vector__XXX
 SG_ FlashAmberWarningLamp : 10|2@1+ (1,0) [0|3] "" Vector__XXX
 SG_ FlashRedStopLamp : 12|2@1+ (1,0) [0|3] "" Vector__XXX
 SG_ FlashMalfunctionIndicatorLamp : 14|2@1+ (1,0) [0|3] "" Vector__XXX
 SG_ SuspectParameterNumber : 23|19@0+ (1,0) [0|524287] "" Vector__XXX
 SG_ FailureModeIdentifier : 32|5@1+ (1,0) [0|31] "" Vector__XXX
 SG_ OccurrenceCount : 40|7@1+ (1,0) [0|127] "" Vector__XXX
 SG_ SPNConversionMethod : 47|1@1+ (1,0) [0|1] "" Vector__XXX
 SG_ SuspectParameterNumber2 : 55|19@0+ (1,0) [0|524287] "" Vector__XXX
 SG_ FailureModeIdentifier2 : 64|5@1+ (1,0) [0|31] "" Vector__XXX
 SG_ OccurrenceCount2 : 72|7@1+ (1,0) [0|127] "" Vector__XXX
 SG_ SPNConversionMethod2 : 79|1@1+ (1,0) [0|1] "" Vector__XXX
 SG_ SuspectParameterNumber3 : 87|19@0+ (1,0) [0|524287] "" Vector__XXX
 SG_ FailureModeIdentifier3 : 96|5@1+ (1,0) [0|31] "" Vector__XXX
 SG_ OccurrenceCount3 : 104|7@1+ (1,0) [0|127] "" Vector__XXX
 SG_ SPNConversionMethod3 : 111|1@1+ (1,0) [0|1] "" Vector__XXX
 SG_ SuspectParameterNumber4 : 119|19@0+ (1,0) [0|524287] "" Vector__XXX
 SG_ FailureModeIdentifier4 : 128|5@1+ (1,0) [0|31] "" Vector__XXX
 SG_ OccurrenceCount4 : 136|7@1+ (1,0) [0|127] "" Vector__XXX
 SG_ SPNConversionMethod4 : 143|1@1+ (1,0) [0|1] "" Vector__XXX
 SG_ SuspectParameterNumber5 : 151|19@0+ (1,0) [0|524287] "" Vector__XXX
 SG_ FailureModeIdentifier5 : 160|5@1+ (1,0) [0|31] "" Vector__XXX
 SG_ OccurrenceCount5 : 168|7@1+ (1,0) [0|127] "" Vector__XXX
 SG_ SPNConversionMethod5 : 175|1@1+ (1,0) [0|1] "" Vector__XXX
 SG_ SuspectParameterNumber6 : 183|19@0+ (1,0) [0|524287] "" Vector__XXX
 SG_ FailureModeIdentifier6 : 192|5@1+ (1,0) [0|31] "" Vector__XXX
 SG_ OccurrenceCount6 : 200|7@1+ (1,0) [0|127] "" Vector__XXX
 SG_ SPNConversionMethod6 : 207|1@1+ (1,0) [0|1] "" Vector__XXX
 SG_ SuspectParameterNumber7 : 215|19@0+ (1,0) [0|524287] "" Vector__XXX
 SG_ FailureModeIdentifier7 : 224|5@1+ (1,0) [0|31] "" Vector__XXX
 SG_ OccurrenceCount7 : 232|7@1+ (1,0) [0|127] "" Vector__XXX
 SG_ SPNConversionMethod7 : 239|1@1+ (1,0) [0|1] "" Vector__XXX
 SG_ SuspectParameterNumber8 : 247|19@0+ (1,0) [0|524287] "" Vector__XXX
 SG_ FailureModeIdentifier8 : 256|5@1+ (1,0) [0|31] "" Vector__XXX
 SG_ OccurrenceCount8 : 264|7@1+ (1,0) [0|127] "" Vector__XXX
 SG_ SPNConversionMethod8 : 271|1@1+ (1,0) [0|1] "" Vector__XXX
 SG_ SuspectParameterNumber9 : 279|19@0+ (1,0) [0|524287] "" Vector__XXX
 SG_ FailureModeIdentifier9 : 288|5@1+ (1,0) [0|31] "" Vector__XXX
 SG_ OccurrenceCount9 : 296|7@1+ (1,0) [0|127] "" Vector__XXX
 SG_ SPNConversionMethod9 : 303|1@1+ (1,0) [0|1] "" Vector__XXX
 SG_ SuspectParameterNumber10 : 311|19@0+ (1,0) [0|524287] "" Vector__XXX
 SG_ FailureModeIdentifier10 : 320|5@1+ (1,0) [0|31] "" Vector__XXX
 SG_ OccurrenceCount10 : 328|7@1+ (1,0) [0|127] "" Vector__XXX
 SG_ SPNConversionMethod10 : 335|1@1+ (1,0) [0|1] "" Vector__XXX
 SG_ SuspectParameterNumber11 : 343|19@0+ (1,0) [0|524287] "" Vector__XXX
 SG_ FailureModeIdentifier11 : 352|5@1+ (1,0) [0|31] "" Vector__XXX
 SG_ OccurrenceCount11 : 360|7@1+ (1,0) [0|127] "" Vector__XXX
 SG_ SPNConversionMethod11 : 367|1@1+ (1,0) [0|1] "" Vector__XXX
 SG_ SuspectParameterNumber12 : 375|19@0+ (1,0) [0|524287] "" Vector__XXX
 SG_ FailureModeIdentifier12 : 384|5@1+ (1,0) [0|31] "" Vector__XXX
 SG_ OccurrenceCount12 : 392|7@1+ (1,0) [0|127] "" Vector__XXX
 SG_ SPNConversionMethod12 : 399|1@1+ (1,0) [0|1] "" Vector__XXX

BO_ 2566834725 DM01_Gateway: 50 Vector__XXX
 SG_ ProtectLamp : 0|2@1+ (1,0) [0|3] "" Vector__XXX
 SG_ AmberWarningLamp : 2|2@1+ (1,0) [0|3] "" Vector__XXX
 SG_ RedStopLamp : 4|2@1+ (1,0) [0|3] "" Vector__XXX
 SG_ MalfunctionIndicatorLamp : 6|2@1+ (1,0) [0|3] "" Vector__XXX
 SG_ FlashProtectLamp : 8|2@1+ (1,0) [0|3] "" Vector__XXX
 SG_ FlashAmberWarningLamp : 10|2@1+ (1,0) [0|3] "" Vector__XXX
 SG_ FlashRedStopLamp : 12|2@1+ (1,0) [0|3] "" Vector__XXX
 SG_ FlashMalfunctionIndicatorLamp : 14|2@1+ (1,0) [0|3] "" Vector__XXX
 SG_ SuspectParameterNumber : 23|19@0+ (1,0) [0|524287] "" Vector__XXX
 SG_ FailureModeIdentifier : 32|5@1+ (1,0) [0|31] "" Vector__XXX
 SG_ OccurrenceCount : 40|7@1+ (1,0) [0|127] "" Vector__XXX
 SG_ SPNConversionMethod : 47|1@1+ (1,0) [0|1] "" Vector__XXX
 SG_ SuspectParameterNumber2 : 55|19@0+ (1,0) [0|524287] "" Vector__XXX
 SG_ FailureModeIdentifier2 : 64|5@1+ (1,0) [0|31] "" Vector__XXX
 SG_ OccurrenceCount2 : 72|7@1+ (1,0) [0|127] "" Vector__XXX
 SG_ SPNConversionMethod2 : 79|1@1+ (1,0) [0|1] "" Vector__XXX
 SG_ SuspectParameterNumber3 : 87|19@0+ (1,0) [0|524287] "" Vector__XXX
 SG_ FailureModeIdentifier3 : 96|5@1+ (1,0) [0|31] "" Vector__XXX
 SG_ OccurrenceCount3 : 104|7@1+ (1,0) [0|127] "" Vector__XXX
 SG_ SPNConversionMethod3 : 111|1@1+ (1,0) [0|1] "" Vector__XXX
 SG_ SuspectParameterNumber4 : 119|19@0+ (1,0) [0|524287] "" Vector__XXX
 SG_ FailureModeIdentifier4 : 128|5@1+ (1,0) [0|31] "" Vector__XXX
 SG_ OccurrenceCount4 : 136|7@1+ (1,0) [0|127] "" Vector__XXX
 SG_ SPNConversionMethod4 : 143|1@1+ (1,0) [0|1] "" Vector__XXX
 SG_ SuspectParameterNumber5 : 151|19@0+ (1,0) [0|524287] "" Vector__XXX
 SG_ FailureModeIdentifier5 : 160|5@1+ (1,0) [0|31] "" Vector__XXX
 SG_ OccurrenceCount5 : 168|7@1+ (1,0) [0|127] "" Vector__XXX
 SG_ SPNConversionMethod5 : 175|1@1+ (1,0) [0|1] "" Vector__XXX
 SG_ SuspectParameterNumber6 : 183|19@0+ (1,0) [0|524287] "" Vector__XXX
 SG_ FailureModeIdentifier6 : 192|5@1+ (1,0) [0|31] "" Vector__XXX
 SG_ OccurrenceCount6 : 200|7@1+ (1,0) [0|127] "" Vector__XXX
 SG_ SPNConversionMethod6 : 207|1@1+ (1,0) [0|1] "" Vector__XXX
 SG_ SuspectParameterNumber7 : 215|19@0+ (1,0) [0|524287] "" Vector__XXX
 SG_ FailureModeIdentifier7 : 224|5@1+ (1,0) [0|31] "" Vector__XXX
 SG_ OccurrenceCount7 : 232|7@1+ (1,0) [0|127] "" Vector__XXX
 SG_ SPNConversionMethod7 : 239|1@1+ (1,0) [0|1] "" Vector__XXX
 SG_ SuspectParameterNumber8 : 247|19@0+ (1,0) [0|524287] "" Vector__XXX
 SG_ FailureModeIdentifier8 : 256|5@1+ (1,0) [0|31] "" Vector__XXX
 SG_ OccurrenceCount8 : 264|7@1+ (1,0) [0|127] "" Vector__XXX
 SG_ SPNConversionMethod8 : 271|1@1+ (1,0) [0|1] "" Vector__XXX
 SG_ SuspectParameterNumber9 : 279|19@0+ (1,0) [0|524287] "" Vector__XXX
 SG_ FailureModeIdentifier9 : 288|5@1+ (1,0) [0|31] "" Vector__XXX
 SG_ OccurrenceCount9 : 296|7@1+ (1,0) [0|127] "" Vector__XXX
 SG_ SPNConversionMethod9 : 303|1@1+ (1,0) [0|1] "" Vector__XXX
 SG_ SuspectParameterNumber10 : 311|19@0+ (1,0) [0|524287] "" Vector__XXX
 SG_ FailureModeIdentifier10 : 320|5@1+ (1,0) [0|31] "" Vector__XXX
 SG_ OccurrenceCount10 : 328|7@1+ (1,0) [0|127] "" Vector__XXX
 SG_ SPNConversionMethod10 : 335|1@1+ (1,0) [0|1] "" Vector__XXX
 SG_ SuspectParameterNumber11 : 343|19@0+ (1,0) [0|524287] "" Vector__XXX
 SG_ FailureModeIdentifier11 : 352|5@1+ (1,0) [0|31] "" Vector__XXX
 SG_ OccurrenceCount11 : 360|7@1+ (1,0) [0|127] "" Vector__XXX
 SG_ SPNConversionMethod11 : 367|1@1+ (1,0) [0|1] "" Vector__XXX
 SG_ SuspectParameterNumber12 : 375|19@0+ (1,0) [0|524287] "" Vector__XXX
 SG_ FailureModeIdentifier12 : 384|5@1+ (1,0) [0|31] "" Vector__XXX
 SG_ OccurrenceCount12 : 392|7@1+ (1,0) [0|127] "" Vector__XXX
 SG_ SPNConversionMethod12 : 399|1@1+ (1,0) [0|1] "" Vector__XXX

BO_ 2566834739 DM01_TirePressureController: 50 Vector__XXX
 SG_ ProtectLamp : 0|2@1+ (1,0) [0|3] "" Vector__XXX
 SG_ AmberWarningLamp : 2|2@1+ (1,0) [0|3] "" Vector__XXX
 SG_ RedStopLamp : 4|2@1+ (1,0) [0|3] "" Vector__XXX
 SG_ MalfunctionIndicatorLamp : 6|2@1+ (1,0) [0|3] "" Vector__XXX
 SG_ FlashProtectLamp : 8|2@1+ (1,0) [0|3] "" Vector__XXX
 SG_ FlashAmberWarningLamp : 10|2@1+ (1,0) [0|3] "" Vector__XXX
 SG_ FlashRedStopLamp : 12|2@1+ (1,0) [0|3] "" Vector__XXX
 SG_ FlashMalfunctionIndicatorLamp : 14|2@1+ (1,0) [0|3] "" Vector__XXX
 SG_ SuspectParameterNumber : 23|19@0+ (1,0) [0|524287] "" Vector__XXX
 SG_ FailureModeIdentifier : 32|5@1+ (1,0) [0|31] "" Vector__XXX
 SG_ OccurrenceCount : 40|7@1+ (1,0) [0|127] "" Vector__XXX
 SG_ SPNConversionMethod : 47|1@1+ (1,0) [0|1] "" Vector__XXX
 SG_ SuspectParameterNumber2 : 55|19@0+ (1,0) [0|524287] "" Vector__XXX
 SG_ FailureModeIdentifier2 : 64|5@1+ (1,0) [0|31] "" Vector__XXX
 SG_ OccurrenceCount2 : 72|7@1+ (1,0) [0|127] "" Vector__XXX
 SG_ SPNConversionMethod2 : 79|1@1+ (1,0) [0|1] "" Vector__XXX
 SG_ SuspectParameterNumber3 : 87|19@0+ (1,0) [0|524287] "" Vector__XXX
 SG_ FailureModeIdentifier3 : 96|5@1+ (1,0) [0|31] "" Vector__XXX
 SG_ OccurrenceCount3 : 104|7@1+ (1,0) [0|127] "" Vector__XXX
 SG_ SPNConversionMethod3 : 111|1@1+ (1,0) [0|1] "" Vector__XXX
 SG_ SuspectParameterNumber4 : 119|19@0+ (1,0) [0|524287] "" Vector__XXX
 SG_ FailureModeIdentifier4 : 128|5@1+ (1,0) [0|31] "" Vector__XXX
 SG_ OccurrenceCount4 : 136|7@1+ (1,0) [0|127] "" Vector__XXX
 SG_ SPNConversionMethod4 : 143|1@1+ (1,0) [0|1] "" Vector__XXX
 SG_ SuspectParameterNumber5 : 151|19@0+ (1,0) [0|524287] "" Vector__XXX
 SG_ FailureModeIdentifier5 : 160|5@1+ (1,0) [0|31] "" Vector__XXX
 SG_ OccurrenceCount5 : 168|7@1+ (1,0) [0|127] "" Vector__XXX
 SG_ SPNConversionMethod5 : 175|1@1+ (1,0) [0|1] "" Vector__XXX
 SG_ SuspectParameterNumber6 : 183|19@0+ (1,0) [0|524287] "" Vector__XXX
 SG_ FailureModeIdentifier6 : 192|5@1+ (1,0) [0|31] "" Vector__XXX
 SG_ OccurrenceCount6 : 200|7@1+ (1,0) [0|127] "" Vector__XXX
 SG_ SPNConversionMethod6 : 207|1@1+ (1,0) [0|1] "" Vector__XXX
 SG_ SuspectParameterNumber7 : 215|19@0+ (1,0) [0|524287] "" Vector__XXX
 SG_ FailureModeIdentifier7 : 224|5@1+ (1,0) [0|31] "" Vector__XXX
 SG_ OccurrenceCount7 : 232|7@1+ (1,0) [0|127] "" Vector__XXX
 SG_ SPNConversionMethod7 : 239|1@1+ (1,0) [0|1] "" Vector__XXX
 SG_ SuspectParameterNumber8 : 247|19@0+ (1,0) [0|524287] "" Vector__XXX
 SG_ FailureModeIdentifier8 : 256|5@1+ (1,0) [0|31] "" Vector__XXX
 SG_ OccurrenceCount8 : 264|7@1+ (1,0) [0|127] "" Vector__XXX
 SG_ SPNConversionMethod8 : 271|1@1+ (1,0) [0|1] "" Vector__XXX
 SG_ SuspectParameterNumber9 : 279|19@0+ (1,0) [0|524287] "" Vector__XXX
 SG_ FailureModeIdentifier9 : 288|5@1+ (1,0) [0|31] "" Vector__XXX
 SG_ OccurrenceCount9 : 296|7@1+ (1,0) [0|127] "" Vector__XXX
 SG_ SPNConversionMethod9 : 303|1@1+ (1,0) [0|1] "" Vector__XXX
 SG_ SuspectParameterNumber10 : 311|19@0+ (1,0) [0|524287] "" Vector__XXX
 SG_ FailureModeIdentifier10 : 320|5@1+ (1,0) [0|31] "" Vector__XXX
 SG_ OccurrenceCount10 : 328|7@1+ (1,0) [0|127] "" Vector__XXX
 SG_ SPNConversionMethod10 : 335|1@1+ (1,0) [0|1] "" Vector__XXX
 SG_ SuspectParameterNumber11 : 343|19@0+ (1,0) [0|524287] "" Vector__XXX
 SG_ FailureModeIdentifier11 : 352|5@1+ (1,0) [0|31] "" Vector__XXX
 SG_ OccurrenceCount11 : 360|7@1+ (1,0) [0|127] "" Vector__XXX
 SG_ SPNConversionMethod11 : 367|1@1+ (1,0) [0|1] "" Vector__XXX
 SG_ SuspectParameterNumber12 : 375|19@0+ (1,0) [0|524287] "" Vector__XXX
 SG_ FailureModeIdentifier12 : 384|5@1+ (1,0) [0|31] "" Vector__XXX
 SG_ OccurrenceCount12 : 392|7@1+ (1,0) [0|127] "" Vector__XXX
 SG_ SPNConversionMethod12 : 399|1@1+ (1,0) [0|1] "" Vector__XXX

BO_ 2566834699 DM01_ElectronicBrakeController: 50 Vector__XXX
 SG_ ProtectLamp : 0|2@1+ (1,0) [0|3] "" Vector__XXX
 SG_ AmberWarningLamp : 2|2@1+ (1,0) [0|3] "" Vector__XXX
 SG_ RedStopLamp : 4|2@1+ (1,0) [0|3] "" Vector__XXX
 SG_ MalfunctionIndicatorLamp : 6|2@1+ (1,0) [0|3] "" Vector__XXX
 SG_ FlashProtectLamp : 8|2@1+ (1,0) [0|3] "" Vector__XXX
 SG_ FlashAmberWarningLamp : 10|2@1+ (1,0) [0|3] "" Vector__XXX
 SG_ FlashRedStopLamp : 12|2@1+ (1,0) [0|3] "" Vector__XXX
 SG_ FlashMalfunctionIndicatorLamp : 14|2@1+ (1,0) [0|3] "" Vector__XXX
 SG_ SuspectParameterNumber : 23|19@0+ (1,0) [0|524287] "" Vector__XXX
 SG_ FailureModeIdentifier : 32|5@1+ (1,0) [0|31] "" Vector__XXX
 SG_ OccurrenceCount : 40|7@1+ (1,0) [0|127] "" Vector__XXX
 SG_ SPNConversionMethod : 47|1@1+ (1,0) [0|1] "" Vector__XXX
 SG_ SuspectParameterNumber2 : 55|19@0+ (1,0) [0|524287] "" Vector__XXX
 SG_ FailureModeIdentifier2 : 64|5@1+ (1,0) [0|31] "" Vector__XXX
 SG_ OccurrenceCount2 : 72|7@1+ (1,0) [0|127] "" Vector__XXX
 SG_ SPNConversionMethod2 : 79|1@1+ (1,0) [0|1] "" Vector__XXX
 SG_ SuspectParameterNumber3 : 87|19@0+ (1,0) [0|524287] "" Vector__XXX
 SG_ FailureModeIdentifier3 : 96|5@1+ (1,0) [0|31] "" Vector__XXX
 SG_ OccurrenceCount3 : 104|7@1+ (1,0) [0|127] "" Vector__XXX
 SG_ SPNConversionMethod3 : 111|1@1+ (1,0) [0|1] "" Vector__XXX
 SG_ SuspectParameterNumber4 : 119|19@0+ (1,0) [0|524287] "" Vector__XXX
 SG_ FailureModeIdentifier4 : 128|5@1+ (1,0) [0|31] "" Vector__XXX
 SG_ OccurrenceCount4 : 136|7@1+ (1,0) [0|127] "" Vector__XXX
 SG_ SPNConversionMethod4 : 143|1@1+ (1,0) [0|1] "" Vector__XXX
 SG_ SuspectParameterNumber5 : 151|19@0+ (1,0) [0|524287] "" Vector__XXX
 SG_ FailureModeIdentifier5 : 160|5@1+ (1,0) [0|31] "" Vector__XXX
 SG_ OccurrenceCount5 : 168|7@1+ (1,0) [0|127] "" Vector__XXX
 SG_ SPNConversionMethod5 : 175|1@1+ (1,0) [0|1] "" Vector__XXX
 SG_ SuspectParameterNumber6 : 183|19@0+ (1,0) [0|524287] "" Vector__XXX
 SG_ FailureModeIdentifier6 : 192|5@1+ (1,0) [0|31] "" Vector__XXX
 SG_ OccurrenceCount6 : 200|7@1+ (1,0) [0|127] "" Vector__XXX
 SG_ SPNConversionMethod6 : 207|1@1+ (1,0) [0|1] "" Vector__XXX
 SG_ SuspectParameterNumber7 : 215|19@0+ (1,0) [0|524287] "" Vector__XXX
 SG_ FailureModeIdentifier7 : 224|5@1+ (1,0) [0|31] "" Vector__XXX
 SG_ OccurrenceCount7 : 232|7@1+ (1,0) [0|127] "" Vector__XXX
 SG_ SPNConversionMethod7 : 239|1@1+ (1,0) [0|1] "" Vector__XXX
 SG_ SuspectParameterNumber8 : 247|19@0+ (1,0) [0|524287] "" Vector__XXX
 SG_ FailureModeIdentifier8 : 256|5@1+ (1,0) [0|31] "" Vector__XXX
 SG_ OccurrenceCount8 : 264|7@1+ (1,0) [0|127] "" Vector__XXX
 SG_ SPNConversionMethod8 : 271|1@1+ (1,0) [0|1] "" Vector__XXX
 SG_ SuspectParameterNumber9 : 279|19@0+ (1,0) [0|524287] "" Vector__XXX
 SG_ FailureModeIdentifier9 : 288|5@1+ (1,0) [0|31] "" Vector__XXX
 SG_ OccurrenceCount9 : 296|7@1+ (1,0) [0|127] "" Vector__XXX
 SG_ SPNConversionMethod9 : 303|1@1+ (1,0) [0|1] "" Vector__XXX
 SG_ SuspectParameterNumber10 : 311|19@0+ (1,0) [0|524287] "" Vector__XXX
 SG_ FailureModeIdentifier10 : 320|5@1+ (1,0) [0|31] "" Vector__XXX
 SG_ OccurrenceCount10 : 328|7@1+ (1,0) [0|127] "" Vector__XXX
 SG_ SPNConversionMethod10 : 335|1@1+ (1,0) [0|1] "" Vector__XXX
 SG_ SuspectParameterNumber11 : 343|19@0+ (1,0) [0|524287] "" Vector__XXX
 SG_ FailureModeIdentifier11 : 352|5@1+ (1,0) [0|31] "" Vector__XXX
 SG_ OccurrenceCount11 : 360|7@1+ (1,0) [0|127] "" Vector__XXX
 SG_ SPNConversionMethod11 : 367|1@1+ (1,0) [0|1] "" Vector__XXX
 SG_ SuspectParameterNumber12 : 375|19@0+ (1,0) [0|524287] "" Vector__XXX
 SG_ FailureModeIdentifier12 : 384|5@1+ (1,0) [0|31] "" Vector__XXX
 SG_ OccurrenceCount12 : 392|7@1+ (1,0) [0|127] "" Vector__XXX
 SG_ SPNConversionMethod12 : 399|1@1+ (1,0) [0|1] "" Vector__XXX

BO_ 2566759719 Door_Control_2_ZR: 8 Vector__XXX
 SG_ LockStatusOfDoor1 : 0|2@1+ (1,0) [0|3] "" Vector__XXX
 SG_ OpenStatusOfDoor1 : 2|2@1+ (1,0) [0|3] "" Vector__XXX
 SG_ EnableStatusOfDoor1 : 4|2@1+ (1,0) [0|3] "" Vector__XXX
 SG_ LockStatusOfDoor2 : 6|2@1+ (1,0) [0|3] "" Vector__XXX
 SG_ OpenStatusOfDoor2 : 8|2@1+ (1,0) [0|3] "" Vector__XXX
 SG_ EnableStatusOfDoor2 : 10|2@1+ (1,0) [0|3] "" Vector__XXX
 SG_ LockStatusOfDoor3 : 12|2@1+ (1,0) [0|3] "" Vector__XXX
 SG_ OpenStatusOfDoor3 : 14|2@1+ (1,0) [0|3] "" Vector__XXX
 SG_ EnableStatusOfDoor3 : 16|2@1+ (1,0) [0|3] "" Vector__XXX
 SG_ LockStatusOfDoor4 : 18|2@1+ (1,0) [0|3] "" Vector__XXX
 SG_ OpenStatusOfDoor4 : 20|2@1+ (1,0) [0|3] "" Vector__XXX
 SG_ EnableStatusOfDoor4 : 22|2@1+ (1,0) [0|3] "" Vector__XXX
 SG_ LockStatusOfDoor5 : 24|2@1+ (1,0) [0|3] "" Vector__XXX
 SG_ OpenStatusOfDoor5 : 26|2@1+ (1,0) [0|3] "" Vector__XXX
 SG_ EnableStatusOfDoor5 : 28|2@1+ (1,0) [0|3] "" Vector__XXX
 SG_ LockStatusOfDoor6 : 30|2@1+ (1,0) [0|3] "" Vector__XXX
 SG_ OpenStatusOfDoor6 : 32|2@1+ (1,0) [0|3] "" Vector__XXX
 SG_ EnableStatusOfDoor6 : 34|2@1+ (1,0) [0|3] "" Vector__XXX
 SG_ LockStatusOfDoor7 : 36|2@1+ (1,0) [0|3] "" Vector__XXX
 SG_ OpenStatusOfDoor7 : 38|2@1+ (1,0) [0|3] "" Vector__XXX
 SG_ EnableStatusOfDoor7 : 40|2@1+ (1,0) [0|3] "" Vector__XXX
 SG_ LockStatusOfDoor8 : 42|2@1+ (1,0) [0|3] "" Vector__XXX
 SG_ OpenStatusOfDoor8 : 44|2@1+ (1,0) [0|3] "" Vector__XXX
 SG_ EnableStatusOfDoor8 : 46|2@1+ (1,0) [0|3] "" Vector__XXX
 SG_ LockStatusOfDoor9 : 48|2@1+ (1,0) [0|3] "" Vector__XXX
 SG_ OpenStatusOfDoor9 : 50|2@1+ (1,0) [0|3] "" Vector__XXX
 SG_ EnableStatusOfDoor9 : 52|2@1+ (1,0) [0|3] "" Vector__XXX
 SG_ LockStatusOfDoor10 : 54|2@1+ (1,0) [0|3] "" Vector__XXX
 SG_ OpenStatusOfDoor10 : 56|2@1+ (1,0) [0|3] "" Vector__XXX
 SG_ EnableStatusOfDoor10 : 58|2@1+ (1,0) [0|3] "" Vector__XXX

BO_ 2364539648 EEC2_DICO_Signals: 8 Vector__XXX
 SG_ AcceleratorPedal1LowIdleSwitch : 0|2@1+ (1,0) [0|3] "" Vector__XXX
 SG_ AcceleratorPedalKickdownSwitch : 2|2@1+ (1,0) [0|3] "" Vector__XXX
 SG_ RoadSpeedLimitStatus : 4|2@1+ (1,0) [0|3] "" Vector__XXX
 SG_ AcceleratorPedal2LowIdleSwitch : 6|2@1+ (1,0) [0|3] "" Vector__XXX
 SG_ AcceleratorPedalPosition1 : 8|8@1+ (0.4,0) [0|100] "%" Vector__XXX
 SG_ EnginePercentLoadAtCurrentSpeed : 16|8@1+ (1,0) [0|250] "%" Vector__XXX
 SG_ RemoteAcceleratorPedalPosition : 24|8@1+ (0.4,0) [0|100] "%" Vector__XXX
 SG_ AcceleratorPedalPosition2 : 32|8@1+ (0.4,0) [0|100] "%" Vector__XXX
 SG_ VehicleAccltnRateLimitStatus : 40|2@1+ (1,0) [0|3] "" Vector__XXX
 SG_ MomentaryEngMaxPowerEnblFdbck : 42|2@1+ (1,0) [0|3] "" Vector__XXX
 SG_ DPFThermalManagementActive : 44|2@1+ (1,0) [0|3] "" Vector__XXX
 SG_ SCRThermalManagementActive : 46|2@1+ (1,0) [0|3] "" Vector__XXX
 SG_ ActlMaximumAvailEngPercentTorque : 48|8@1+ (0.4,0) [0|100] "%" Vector__XXX
 SG_ EstimatedPumpingPercentTorque : 56|8@1+ (1,-125) [-125|125] "%" Vector__XXX

CM_ SG_ 2566885123 GlobalEnablePrechargeSiemens "This may not be the correct signal - if 1 it usually means generator error?";
CM_ SG_ 2566885123 DriveSystemActive "Pulses Enabled";
CM_ SG_ 2566885123 InitializationPhase "1 during initialization";
CM_ SG_ 2566885123 PreChargingActive "1 during startup phase (precharging)";
CM_ SG_ 2566885123 DirectionOfVehicle "1 - vehicle is traveling forward";
CM_ SG_ 2566885123 ErrorBufferIndication "New error code is indicated here with a value of 1";
CM_ SG_ 2566885123 ErrorBufferNumer "Position in error buffer where most recent error is logged";
CM_ BO_ 2566722906 "Not on the ZR Network";
CM_ BO_ 2566722650 "Not on the ZR network";
CM_ SG_ 2566863399 DC_DC_ChargeDemandDC2 "Not Reliable for Logging";
CM_ SG_ 2566863399 DC_DC_ChargeDemandDC1 "On or off for charging enabled from DC to DC inverters";
CM_ SG_ 2566901577 StatusChargeActive "Charge Active status bit";
CM_ BO_ 2566900297 "Port A last abort code is in this message";
CM_ BO_ 2566843687 "Not used yet.";
CM_ BO_ 2566884099 "Not used yet.  Will provide power feedback from auxiliaries";
CM_ BO_ 2566885891 "Not really used yet.  Value can be got from brake resistor 1 since they are in series.";
CM_ SG_ 2566885891 BrakeResistor2Temperature "Not used reisistors connected in series";
CM_ SG_ 2566701658 OverspeedAudibleAlarm "Not Used";
CM_ BO_ 2566609191 "High Voltage Battery State of health";
CM_ BO_ 2565902631 "High voltage battery state of charge";
CM_ BO_ 2566900553 "Port A last abort code is in this message";
CM_ BO_ 2364539904 "SAE Stadard Message";
CM_ SG_ 2364539904 EngineTorqueMode "See SPN512_A and SPN_512_B for engine control";
CM_ SG_ 2364539904 ActualPercTorqueFractional "Used to represent the fractional portion of torque for the actual percent torque";
CM_ BO_ 2565865488 "Electronic Retarder Controller 1";
CM_ SG_ 2565865488 RetarderTorqueMode "0000 Means no retarder request, everything above is a request";
CM_ BO_ 2348810243 "Torque/Speed Control 1";
CM_ BO_ 2364539395 "Electronic Transmission Controller 1";
CM_ BO_ 2431649768 "Forward Lane Image 1";
CM_ BO_ 2565867787 "Vehicle Dynamic Stability Control 2";
CM_ BO_ 2566806504 "Forward Lane Image 2";
CM_ BO_ 2566827275 "Wheel Application Pressure High Range Information";
CM_ BO_ 2566831883 "Wheel Speed Information";
CM_ BO_ 2566767627 "Electronic Brake Controller 5";
CM_ BO_ 2566844762 "Cruise Control/Vehicle Speed 1";
CM_ BO_ 2365443111 "Operators External Light Controls Message";
CM_ BO_ 2566803211 "Vehicle Dynamic Stability Control 1";
CM_ BO_ 2566805807 "Air Suspension Control 3";
CM_ BO_ 2365479471 "Air Suspension Control 1";
CM_ BO_ 2348875518 "Torque/Speed Control 1";
CM_ BO_ 2632711934 "Transport Protocol - Data Transfer";
CM_ BO_ 2632777470 "Transport Protocol - Connection Management";
CM_ SG_ 2632777470 TPCM_Mux "Request to Send";
CM_ SG_ 2566850611 RSSI "Only reads between -80 dBm and -110 dBm";
CM_ BO_ 2566834735 "Active Diagnostic Trouble Codes";
CM_ BO_ 2566834737 "Active Diagnostic Trouble Codes";
CM_ BO_ 2566834761 "Active Diagnostic Trouble Codes";
CM_ BO_ 2566834691 "Active Diagnostic Trouble Codes";
CM_ BO_ 2566834920 "Active Diagnostic Trouble Codes";
CM_ BO_ 2566834734 "Active Diagnostic Trouble Codes";
CM_ BO_ 2566834690 "Active Diagnostic Trouble Codes";
CM_ BO_ 2566834711 "Active Diagnostic Trouble Codes";
CM_ BO_ 2566834725 "Active Diagnostic Trouble Codes";
CM_ BO_ 2566834739 "Active Diagnostic Trouble Codes";
CM_ BO_ 2566834699 "Active Diagnostic Trouble Codes";
CM_ BO_ 2566759719 "Door Control 2";
CM_ BO_ 2364539648 "Electronic Engine Controller 2";
BA_DEF_  "BusType" STRING ;
BA_DEF_  "ProtocolType" STRING ;
BA_DEF_ BO_  "VFrameFormat" ENUM  "StandardCAN","ExtendedCAN","reserved","J1939PG";
BA_DEF_ BO_  "GenMsgCycleTime" INT 0 65535;
BA_DEF_ SG_  "GenSigStartValue" FLOAT -3.4E+038 3.4E+038;
BA_DEF_ SG_  "SPN" INT -3.4E+038 3.4E+038;
BA_DEF_DEF_  "BusType" "CAN";
BA_DEF_DEF_  "ProtocolType" "J1939";
BA_DEF_DEF_  "VFrameFormat" "J1939PG";
BA_DEF_DEF_  "GenMsgCycleTime" 0;
BA_DEF_DEF_  "GenSigStartValue" 0;
BA_DEF_DEF_  "SPN" 0;
BA_ "GenMsgCycleTime" BO_ 2348810243 10;
BA_ "GenMsgCycleTime" BO_ 2364539395 10;
BA_ "GenMsgCycleTime" BO_ 2431649768 50;
BA_ "GenMsgCycleTime" BO_ 2565867787 10;
BA_ "GenMsgCycleTime" BO_ 2566806504 100;
BA_ "GenMsgCycleTime" BO_ 2566827275 100;
BA_ "GenMsgCycleTime" BO_ 2566831883 100;
BA_ "GenMsgCycleTime" BO_ 2566767627 100;
BA_ "GenMsgCycleTime" BO_ 2566844762 100;
BA_ "GenMsgCycleTime" BO_ 2365443111 1000;
BA_ "GenMsgCycleTime" BO_ 2566803211 100;
BA_ "GenMsgCycleTime" BO_ 2566805807 100;
BA_ "GenMsgCycleTime" BO_ 2365479471 100;
BA_ "GenMsgCycleTime" BO_ 2348875518 10;
BA_ "GenMsgCycleTime" BO_ 2566759719 100;
BA_ "GenMsgCycleTime" BO_ 2364539648 50;
BA_ "GenSigStartValue" SG_ 2566893342 String1AverageBatteryPackTemp 50;
BA_ "GenSigStartValue" SG_ 2566893343 String2AverageBatteryPackTemp 50;
BA_ "GenSigStartValue" SG_ 2566893340 String3AverageBatteryPackTemp 50;
BA_ "SPN" SG_ 2632711934 SequenceNumber 2572;
BA_ "SPN" SG_ 2632711934 PacketizedData 2573;
BA_ "SPN" SG_ 2632777470 TotalMessageSize16 2557;
BA_ "SPN" SG_ 2632777470 TotalNumberOfPackets16 2558;
BA_ "SPN" SG_ 2632777470 MaximumNumberOfPackets 2559;
BA_ "SPN" SG_ 2632777470 PGNOfThePacketedMessage16 2560;
BA_ "SPN" SG_ 2632777470 NumberOfPacketsThatCanBeSent 2561;
BA_ "SPN" SG_ 2632777470 NextPacketNumberToBeSent 2562;
BA_ "SPN" SG_ 2632777470 PGNOfThePacketedMessage17 2563;
BA_ "SPN" SG_ 2632777470 TotalMessageSize19 2564;
BA_ "SPN" SG_ 2632777470 TotalNumberOfPackets19 2565;
BA_ "SPN" SG_ 2632777470 PGNOfThePacketedMessage19 2566;
BA_ "SPN" SG_ 2632777470 TotalMessageSize32 2567;
BA_ "SPN" SG_ 2632777470 TotalNumberOfPackets32 2568;
BA_ "SPN" SG_ 2632777470 PGNOfThePacketedMessage32 2569;
BA_ "SPN" SG_ 2632777470 ConnectionAbortReason 2570;
BA_ "SPN" SG_ 2632777470 ParameterGrpNoOfPacketedMessage 2571;
BA_ "GenSigStartValue" SG_ 2566850611 RSSI -80;
BA_ "SPN" SG_ 2566834735 ProtectLamp 987;
BA_ "SPN" SG_ 2566834735 AmberWarningLamp 624;
BA_ "SPN" SG_ 2566834735 RedStopLamp 623;
BA_ "SPN" SG_ 2566834735 MalfunctionIndicatorLamp 1213;
BA_ "SPN" SG_ 2566834735 FlashProtectLamp 3041;
BA_ "SPN" SG_ 2566834735 FlashAmberWarningLamp 3040;
BA_ "SPN" SG_ 2566834735 FlashRedStopLamp 3039;
BA_ "SPN" SG_ 2566834735 FlashMalfunctionIndicatorLamp 3038;
BA_ "SPN" SG_ 2566834735 SuspectParameterNumber 1214;
BA_ "SPN" SG_ 2566834735 FailureModeIdentifier 1215;
BA_ "SPN" SG_ 2566834735 OccurrenceCount 1216;
BA_ "SPN" SG_ 2566834735 SPNConversionMethod 1706;
BA_ "SPN" SG_ 2566834735 SuspectParameterNumber2 1214;
BA_ "SPN" SG_ 2566834735 FailureModeIdentifier2 1215;
BA_ "SPN" SG_ 2566834735 OccurrenceCount2 1216;
BA_ "SPN" SG_ 2566834735 SPNConversionMethod2 1706;
BA_ "SPN" SG_ 2566834735 SuspectParameterNumber3 1214;
BA_ "SPN" SG_ 2566834735 FailureModeIdentifier3 1215;
BA_ "SPN" SG_ 2566834735 OccurrenceCount3 1216;
BA_ "SPN" SG_ 2566834735 SPNConversionMethod3 1706;
BA_ "SPN" SG_ 2566834735 SuspectParameterNumber4 1214;
BA_ "SPN" SG_ 2566834735 FailureModeIdentifier4 1215;
BA_ "SPN" SG_ 2566834735 OccurrenceCount4 1216;
BA_ "SPN" SG_ 2566834735 SPNConversionMethod4 1706;
BA_ "SPN" SG_ 2566834735 SuspectParameterNumber5 1214;
BA_ "SPN" SG_ 2566834735 FailureModeIdentifier5 1215;
BA_ "SPN" SG_ 2566834735 OccurrenceCount5 1216;
BA_ "SPN" SG_ 2566834735 SPNConversionMethod5 1706;
BA_ "SPN" SG_ 2566834735 SuspectParameterNumber6 1214;
BA_ "SPN" SG_ 2566834735 FailureModeIdentifier6 1215;
BA_ "SPN" SG_ 2566834735 OccurrenceCount6 1216;
BA_ "SPN" SG_ 2566834735 SPNConversionMethod6 1706;
BA_ "SPN" SG_ 2566834735 SuspectParameterNumber7 1214;
BA_ "SPN" SG_ 2566834735 FailureModeIdentifier7 1215;
BA_ "SPN" SG_ 2566834735 OccurrenceCount7 1216;
BA_ "SPN" SG_ 2566834735 SPNConversionMethod7 1706;
BA_ "SPN" SG_ 2566834735 SuspectParameterNumber8 1214;
BA_ "SPN" SG_ 2566834735 FailureModeIdentifier8 1215;
BA_ "SPN" SG_ 2566834735 OccurrenceCount8 1216;
BA_ "SPN" SG_ 2566834735 SPNConversionMethod8 1706;
BA_ "SPN" SG_ 2566834735 SuspectParameterNumber9 1214;
BA_ "SPN" SG_ 2566834735 FailureModeIdentifier9 1215;
BA_ "SPN" SG_ 2566834735 OccurrenceCount9 1216;
BA_ "SPN" SG_ 2566834735 SPNConversionMethod9 1706;
BA_ "SPN" SG_ 2566834735 SuspectParameterNumber10 1214;
BA_ "SPN" SG_ 2566834735 FailureModeIdentifier10 1215;
BA_ "SPN" SG_ 2566834735 OccurrenceCount10 1216;
BA_ "SPN" SG_ 2566834735 SPNConversionMethod10 1706;
BA_ "SPN" SG_ 2566834735 SuspectParameterNumber11 1214;
BA_ "SPN" SG_ 2566834735 FailureModeIdentifier11 1215;
BA_ "SPN" SG_ 2566834735 OccurrenceCount11 1216;
BA_ "SPN" SG_ 2566834735 SPNConversionMethod11 1706;
BA_ "SPN" SG_ 2566834735 SuspectParameterNumber12 1214;
BA_ "SPN" SG_ 2566834735 FailureModeIdentifier12 1215;
BA_ "SPN" SG_ 2566834735 OccurrenceCount12 1216;
BA_ "SPN" SG_ 2566834735 SPNConversionMethod12 1706;
BA_ "SPN" SG_ 2566834737 ProtectLamp 987;
BA_ "SPN" SG_ 2566834737 AmberWarningLamp 624;
BA_ "SPN" SG_ 2566834737 RedStopLamp 623;
BA_ "SPN" SG_ 2566834737 MalfunctionIndicatorLamp 1213;
BA_ "SPN" SG_ 2566834737 FlashProtectLamp 3041;
BA_ "SPN" SG_ 2566834737 FlashAmberWarningLamp 3040;
BA_ "SPN" SG_ 2566834737 FlashRedStopLamp 3039;
BA_ "SPN" SG_ 2566834737 FlashMalfunctionIndicatorLamp 3038;
BA_ "SPN" SG_ 2566834737 SuspectParameterNumber 1214;
BA_ "SPN" SG_ 2566834737 FailureModeIdentifier 1215;
BA_ "SPN" SG_ 2566834737 OccurrenceCount 1216;
BA_ "SPN" SG_ 2566834737 SPNConversionMethod 1706;
BA_ "SPN" SG_ 2566834737 SuspectParameterNumber2 1214;
BA_ "SPN" SG_ 2566834737 FailureModeIdentifier2 1215;
BA_ "SPN" SG_ 2566834737 OccurrenceCount2 1216;
BA_ "SPN" SG_ 2566834737 SPNConversionMethod2 1706;
BA_ "SPN" SG_ 2566834737 SuspectParameterNumber3 1214;
BA_ "SPN" SG_ 2566834737 FailureModeIdentifier3 1215;
BA_ "SPN" SG_ 2566834737 OccurrenceCount3 1216;
BA_ "SPN" SG_ 2566834737 SPNConversionMethod3 1706;
BA_ "SPN" SG_ 2566834737 SuspectParameterNumber4 1214;
BA_ "SPN" SG_ 2566834737 FailureModeIdentifier4 1215;
BA_ "SPN" SG_ 2566834737 OccurrenceCount4 1216;
BA_ "SPN" SG_ 2566834737 SPNConversionMethod4 1706;
BA_ "SPN" SG_ 2566834737 SuspectParameterNumber5 1214;
BA_ "SPN" SG_ 2566834737 FailureModeIdentifier5 1215;
BA_ "SPN" SG_ 2566834737 OccurrenceCount5 1216;
BA_ "SPN" SG_ 2566834737 SPNConversionMethod5 1706;
BA_ "SPN" SG_ 2566834737 SuspectParameterNumber6 1214;
BA_ "SPN" SG_ 2566834737 FailureModeIdentifier6 1215;
BA_ "SPN" SG_ 2566834737 OccurrenceCount6 1216;
BA_ "SPN" SG_ 2566834737 SPNConversionMethod6 1706;
BA_ "SPN" SG_ 2566834737 SuspectParameterNumber7 1214;
BA_ "SPN" SG_ 2566834737 FailureModeIdentifier7 1215;
BA_ "SPN" SG_ 2566834737 OccurrenceCount7 1216;
BA_ "SPN" SG_ 2566834737 SPNConversionMethod7 1706;
BA_ "SPN" SG_ 2566834737 SuspectParameterNumber8 1214;
BA_ "SPN" SG_ 2566834737 FailureModeIdentifier8 1215;
BA_ "SPN" SG_ 2566834737 OccurrenceCount8 1216;
BA_ "SPN" SG_ 2566834737 SPNConversionMethod8 1706;
BA_ "SPN" SG_ 2566834737 SuspectParameterNumber9 1214;
BA_ "SPN" SG_ 2566834737 FailureModeIdentifier9 1215;
BA_ "SPN" SG_ 2566834737 OccurrenceCount9 1216;
BA_ "SPN" SG_ 2566834737 SPNConversionMethod9 1706;
BA_ "SPN" SG_ 2566834737 SuspectParameterNumber10 1214;
BA_ "SPN" SG_ 2566834737 FailureModeIdentifier10 1215;
BA_ "SPN" SG_ 2566834737 OccurrenceCount10 1216;
BA_ "SPN" SG_ 2566834737 SPNConversionMethod10 1706;
BA_ "SPN" SG_ 2566834737 SuspectParameterNumber11 1214;
BA_ "SPN" SG_ 2566834737 FailureModeIdentifier11 1215;
BA_ "SPN" SG_ 2566834737 OccurrenceCount11 1216;
BA_ "SPN" SG_ 2566834737 SPNConversionMethod11 1706;
BA_ "SPN" SG_ 2566834737 SuspectParameterNumber12 1214;
BA_ "SPN" SG_ 2566834737 FailureModeIdentifier12 1215;
BA_ "SPN" SG_ 2566834737 OccurrenceCount12 1216;
BA_ "SPN" SG_ 2566834737 SPNConversionMethod12 1706;
BA_ "SPN" SG_ 2566834761 ProtectLamp 987;
BA_ "SPN" SG_ 2566834761 AmberWarningLamp 624;
BA_ "SPN" SG_ 2566834761 RedStopLamp 623;
BA_ "SPN" SG_ 2566834761 MalfunctionIndicatorLamp 1213;
BA_ "SPN" SG_ 2566834761 FlashProtectLamp 3041;
BA_ "SPN" SG_ 2566834761 FlashAmberWarningLamp 3040;
BA_ "SPN" SG_ 2566834761 FlashRedStopLamp 3039;
BA_ "SPN" SG_ 2566834761 FlashMalfunctionIndicatorLamp 3038;
BA_ "SPN" SG_ 2566834761 SuspectParameterNumber 1214;
BA_ "SPN" SG_ 2566834761 FailureModeIdentifier 1215;
BA_ "SPN" SG_ 2566834761 OccurrenceCount 1216;
BA_ "SPN" SG_ 2566834761 SPNConversionMethod 1706;
BA_ "SPN" SG_ 2566834761 SuspectParameterNumber2 1214;
BA_ "SPN" SG_ 2566834761 FailureModeIdentifier2 1215;
BA_ "SPN" SG_ 2566834761 OccurrenceCount2 1216;
BA_ "SPN" SG_ 2566834761 SPNConversionMethod2 1706;
BA_ "SPN" SG_ 2566834761 SuspectParameterNumber3 1214;
BA_ "SPN" SG_ 2566834761 FailureModeIdentifier3 1215;
BA_ "SPN" SG_ 2566834761 OccurrenceCount3 1216;
BA_ "SPN" SG_ 2566834761 SPNConversionMethod3 1706;
BA_ "SPN" SG_ 2566834761 SuspectParameterNumber4 1214;
BA_ "SPN" SG_ 2566834761 FailureModeIdentifier4 1215;
BA_ "SPN" SG_ 2566834761 OccurrenceCount4 1216;
BA_ "SPN" SG_ 2566834761 SPNConversionMethod4 1706;
BA_ "SPN" SG_ 2566834761 SuspectParameterNumber5 1214;
BA_ "SPN" SG_ 2566834761 FailureModeIdentifier5 1215;
BA_ "SPN" SG_ 2566834761 OccurrenceCount5 1216;
BA_ "SPN" SG_ 2566834761 SPNConversionMethod5 1706;
BA_ "SPN" SG_ 2566834761 SuspectParameterNumber6 1214;
BA_ "SPN" SG_ 2566834761 FailureModeIdentifier6 1215;
BA_ "SPN" SG_ 2566834761 OccurrenceCount6 1216;
BA_ "SPN" SG_ 2566834761 SPNConversionMethod6 1706;
BA_ "SPN" SG_ 2566834761 SuspectParameterNumber7 1214;
BA_ "SPN" SG_ 2566834761 FailureModeIdentifier7 1215;
BA_ "SPN" SG_ 2566834761 OccurrenceCount7 1216;
BA_ "SPN" SG_ 2566834761 SPNConversionMethod7 1706;
BA_ "SPN" SG_ 2566834761 SuspectParameterNumber8 1214;
BA_ "SPN" SG_ 2566834761 FailureModeIdentifier8 1215;
BA_ "SPN" SG_ 2566834761 OccurrenceCount8 1216;
BA_ "SPN" SG_ 2566834761 SPNConversionMethod8 1706;
BA_ "SPN" SG_ 2566834761 SuspectParameterNumber9 1214;
BA_ "SPN" SG_ 2566834761 FailureModeIdentifier9 1215;
BA_ "SPN" SG_ 2566834761 OccurrenceCount9 1216;
BA_ "SPN" SG_ 2566834761 SPNConversionMethod9 1706;
BA_ "SPN" SG_ 2566834761 SuspectParameterNumber10 1214;
BA_ "SPN" SG_ 2566834761 FailureModeIdentifier10 1215;
BA_ "SPN" SG_ 2566834761 OccurrenceCount10 1216;
BA_ "SPN" SG_ 2566834761 SPNConversionMethod10 1706;
BA_ "SPN" SG_ 2566834761 SuspectParameterNumber11 1214;
BA_ "SPN" SG_ 2566834761 FailureModeIdentifier11 1215;
BA_ "SPN" SG_ 2566834761 OccurrenceCount11 1216;
BA_ "SPN" SG_ 2566834761 SPNConversionMethod11 1706;
BA_ "SPN" SG_ 2566834761 SuspectParameterNumber12 1214;
BA_ "SPN" SG_ 2566834761 FailureModeIdentifier12 1215;
BA_ "SPN" SG_ 2566834761 OccurrenceCount12 1216;
BA_ "SPN" SG_ 2566834761 SPNConversionMethod12 1706;
BA_ "SPN" SG_ 2566834691 ProtectLamp 987;
BA_ "SPN" SG_ 2566834691 AmberWarningLamp 624;
BA_ "SPN" SG_ 2566834691 RedStopLamp 623;
BA_ "SPN" SG_ 2566834691 MalfunctionIndicatorLamp 1213;
BA_ "SPN" SG_ 2566834691 FlashProtectLamp 3041;
BA_ "SPN" SG_ 2566834691 FlashAmberWarningLamp 3040;
BA_ "SPN" SG_ 2566834691 FlashRedStopLamp 3039;
BA_ "SPN" SG_ 2566834691 FlashMalfunctionIndicatorLamp 3038;
BA_ "SPN" SG_ 2566834691 SuspectParameterNumber 1214;
BA_ "SPN" SG_ 2566834691 FailureModeIdentifier 1215;
BA_ "SPN" SG_ 2566834691 OccurrenceCount 1216;
BA_ "SPN" SG_ 2566834691 SPNConversionMethod 1706;
BA_ "SPN" SG_ 2566834691 SuspectParameterNumber2 1214;
BA_ "SPN" SG_ 2566834691 FailureModeIdentifier2 1215;
BA_ "SPN" SG_ 2566834691 OccurrenceCount2 1216;
BA_ "SPN" SG_ 2566834691 SPNConversionMethod2 1706;
BA_ "SPN" SG_ 2566834691 SuspectParameterNumber3 1214;
BA_ "SPN" SG_ 2566834691 FailureModeIdentifier3 1215;
BA_ "SPN" SG_ 2566834691 OccurrenceCount3 1216;
BA_ "SPN" SG_ 2566834691 SPNConversionMethod3 1706;
BA_ "SPN" SG_ 2566834691 SuspectParameterNumber4 1214;
BA_ "SPN" SG_ 2566834691 FailureModeIdentifier4 1215;
BA_ "SPN" SG_ 2566834691 OccurrenceCount4 1216;
BA_ "SPN" SG_ 2566834691 SPNConversionMethod4 1706;
BA_ "SPN" SG_ 2566834691 SuspectParameterNumber5 1214;
BA_ "SPN" SG_ 2566834691 FailureModeIdentifier5 1215;
BA_ "SPN" SG_ 2566834691 OccurrenceCount5 1216;
BA_ "SPN" SG_ 2566834691 SPNConversionMethod5 1706;
BA_ "SPN" SG_ 2566834691 SuspectParameterNumber6 1214;
BA_ "SPN" SG_ 2566834691 FailureModeIdentifier6 1215;
BA_ "SPN" SG_ 2566834691 OccurrenceCount6 1216;
BA_ "SPN" SG_ 2566834691 SPNConversionMethod6 1706;
BA_ "SPN" SG_ 2566834691 SuspectParameterNumber7 1214;
BA_ "SPN" SG_ 2566834691 FailureModeIdentifier7 1215;
BA_ "SPN" SG_ 2566834691 OccurrenceCount7 1216;
BA_ "SPN" SG_ 2566834691 SPNConversionMethod7 1706;
BA_ "SPN" SG_ 2566834691 SuspectParameterNumber8 1214;
BA_ "SPN" SG_ 2566834691 FailureModeIdentifier8 1215;
BA_ "SPN" SG_ 2566834691 OccurrenceCount8 1216;
BA_ "SPN" SG_ 2566834691 SPNConversionMethod8 1706;
BA_ "SPN" SG_ 2566834691 SuspectParameterNumber9 1214;
BA_ "SPN" SG_ 2566834691 FailureModeIdentifier9 1215;
BA_ "SPN" SG_ 2566834691 OccurrenceCount9 1216;
BA_ "SPN" SG_ 2566834691 SPNConversionMethod9 1706;
BA_ "SPN" SG_ 2566834691 SuspectParameterNumber10 1214;
BA_ "SPN" SG_ 2566834691 FailureModeIdentifier10 1215;
BA_ "SPN" SG_ 2566834691 OccurrenceCount10 1216;
BA_ "SPN" SG_ 2566834691 SPNConversionMethod10 1706;
BA_ "SPN" SG_ 2566834691 SuspectParameterNumber11 1214;
BA_ "SPN" SG_ 2566834691 FailureModeIdentifier11 1215;
BA_ "SPN" SG_ 2566834691 OccurrenceCount11 1216;
BA_ "SPN" SG_ 2566834691 SPNConversionMethod11 1706;
BA_ "SPN" SG_ 2566834691 SuspectParameterNumber12 1214;
BA_ "SPN" SG_ 2566834691 FailureModeIdentifier12 1215;
BA_ "SPN" SG_ 2566834691 OccurrenceCount12 1216;
BA_ "SPN" SG_ 2566834691 SPNConversionMethod12 1706;
BA_ "SPN" SG_ 2566834920 ProtectLamp 987;
BA_ "SPN" SG_ 2566834920 AmberWarningLamp 624;
BA_ "SPN" SG_ 2566834920 RedStopLamp 623;
BA_ "SPN" SG_ 2566834920 MalfunctionIndicatorLamp 1213;
BA_ "SPN" SG_ 2566834920 FlashProtectLamp 3041;
BA_ "SPN" SG_ 2566834920 FlashAmberWarningLamp 3040;
BA_ "SPN" SG_ 2566834920 FlashRedStopLamp 3039;
BA_ "SPN" SG_ 2566834920 FlashMalfunctionIndicatorLamp 3038;
BA_ "SPN" SG_ 2566834920 SuspectParameterNumber 1214;
BA_ "SPN" SG_ 2566834920 FailureModeIdentifier 1215;
BA_ "SPN" SG_ 2566834920 OccurrenceCount 1216;
BA_ "SPN" SG_ 2566834920 SPNConversionMethod 1706;
BA_ "SPN" SG_ 2566834920 SuspectParameterNumber2 1214;
BA_ "SPN" SG_ 2566834920 FailureModeIdentifier2 1215;
BA_ "SPN" SG_ 2566834920 OccurrenceCount2 1216;
BA_ "SPN" SG_ 2566834920 SPNConversionMethod2 1706;
BA_ "SPN" SG_ 2566834920 SuspectParameterNumber3 1214;
BA_ "SPN" SG_ 2566834920 FailureModeIdentifier3 1215;
BA_ "SPN" SG_ 2566834920 OccurrenceCount3 1216;
BA_ "SPN" SG_ 2566834920 SPNConversionMethod3 1706;
BA_ "SPN" SG_ 2566834920 SuspectParameterNumber4 1214;
BA_ "SPN" SG_ 2566834920 FailureModeIdentifier4 1215;
BA_ "SPN" SG_ 2566834920 OccurrenceCount4 1216;
BA_ "SPN" SG_ 2566834920 SPNConversionMethod4 1706;
BA_ "SPN" SG_ 2566834920 SuspectParameterNumber5 1214;
BA_ "SPN" SG_ 2566834920 FailureModeIdentifier5 1215;
BA_ "SPN" SG_ 2566834920 OccurrenceCount5 1216;
BA_ "SPN" SG_ 2566834920 SPNConversionMethod5 1706;
BA_ "SPN" SG_ 2566834920 SuspectParameterNumber6 1214;
BA_ "SPN" SG_ 2566834920 FailureModeIdentifier6 1215;
BA_ "SPN" SG_ 2566834920 OccurrenceCount6 1216;
BA_ "SPN" SG_ 2566834920 SPNConversionMethod6 1706;
BA_ "SPN" SG_ 2566834920 SuspectParameterNumber7 1214;
BA_ "SPN" SG_ 2566834920 FailureModeIdentifier7 1215;
BA_ "SPN" SG_ 2566834920 OccurrenceCount7 1216;
BA_ "SPN" SG_ 2566834920 SPNConversionMethod7 1706;
BA_ "SPN" SG_ 2566834920 SuspectParameterNumber8 1214;
BA_ "SPN" SG_ 2566834920 FailureModeIdentifier8 1215;
BA_ "SPN" SG_ 2566834920 OccurrenceCount8 1216;
BA_ "SPN" SG_ 2566834920 SPNConversionMethod8 1706;
BA_ "SPN" SG_ 2566834920 SuspectParameterNumber9 1214;
BA_ "SPN" SG_ 2566834920 FailureModeIdentifier9 1215;
BA_ "SPN" SG_ 2566834920 OccurrenceCount9 1216;
BA_ "SPN" SG_ 2566834920 SPNConversionMethod9 1706;
BA_ "SPN" SG_ 2566834920 SuspectParameterNumber10 1214;
BA_ "SPN" SG_ 2566834920 FailureModeIdentifier10 1215;
BA_ "SPN" SG_ 2566834920 OccurrenceCount10 1216;
BA_ "SPN" SG_ 2566834920 SPNConversionMethod10 1706;
BA_ "SPN" SG_ 2566834920 SuspectParameterNumber11 1214;
BA_ "SPN" SG_ 2566834920 FailureModeIdentifier11 1215;
BA_ "SPN" SG_ 2566834920 OccurrenceCount11 1216;
BA_ "SPN" SG_ 2566834920 SPNConversionMethod11 1706;
BA_ "SPN" SG_ 2566834920 SuspectParameterNumber12 1214;
BA_ "SPN" SG_ 2566834920 FailureModeIdentifier12 1215;
BA_ "SPN" SG_ 2566834920 OccurrenceCount12 1216;
BA_ "SPN" SG_ 2566834920 SPNConversionMethod12 1706;
BA_ "SPN" SG_ 2566834734 ProtectLamp 987;
BA_ "SPN" SG_ 2566834734 AmberWarningLamp 624;
BA_ "SPN" SG_ 2566834734 RedStopLamp 623;
BA_ "SPN" SG_ 2566834734 MalfunctionIndicatorLamp 1213;
BA_ "SPN" SG_ 2566834734 FlashProtectLamp 3041;
BA_ "SPN" SG_ 2566834734 FlashAmberWarningLamp 3040;
BA_ "SPN" SG_ 2566834734 FlashRedStopLamp 3039;
BA_ "SPN" SG_ 2566834734 FlashMalfunctionIndicatorLamp 3038;
BA_ "SPN" SG_ 2566834734 SuspectParameterNumber 1214;
BA_ "SPN" SG_ 2566834734 FailureModeIdentifier 1215;
BA_ "SPN" SG_ 2566834734 OccurrenceCount 1216;
BA_ "SPN" SG_ 2566834734 SPNConversionMethod 1706;
BA_ "SPN" SG_ 2566834734 SuspectParameterNumber2 1214;
BA_ "SPN" SG_ 2566834734 FailureModeIdentifier2 1215;
BA_ "SPN" SG_ 2566834734 OccurrenceCount2 1216;
BA_ "SPN" SG_ 2566834734 SPNConversionMethod2 1706;
BA_ "SPN" SG_ 2566834734 SuspectParameterNumber3 1214;
BA_ "SPN" SG_ 2566834734 FailureModeIdentifier3 1215;
BA_ "SPN" SG_ 2566834734 OccurrenceCount3 1216;
BA_ "SPN" SG_ 2566834734 SPNConversionMethod3 1706;
BA_ "SPN" SG_ 2566834734 SuspectParameterNumber4 1214;
BA_ "SPN" SG_ 2566834734 FailureModeIdentifier4 1215;
BA_ "SPN" SG_ 2566834734 OccurrenceCount4 1216;
BA_ "SPN" SG_ 2566834734 SPNConversionMethod4 1706;
BA_ "SPN" SG_ 2566834734 SuspectParameterNumber5 1214;
BA_ "SPN" SG_ 2566834734 FailureModeIdentifier5 1215;
BA_ "SPN" SG_ 2566834734 OccurrenceCount5 1216;
BA_ "SPN" SG_ 2566834734 SPNConversionMethod5 1706;
BA_ "SPN" SG_ 2566834734 SuspectParameterNumber6 1214;
BA_ "SPN" SG_ 2566834734 FailureModeIdentifier6 1215;
BA_ "SPN" SG_ 2566834734 OccurrenceCount6 1216;
BA_ "SPN" SG_ 2566834734 SPNConversionMethod6 1706;
BA_ "SPN" SG_ 2566834734 SuspectParameterNumber7 1214;
BA_ "SPN" SG_ 2566834734 FailureModeIdentifier7 1215;
BA_ "SPN" SG_ 2566834734 OccurrenceCount7 1216;
BA_ "SPN" SG_ 2566834734 SPNConversionMethod7 1706;
BA_ "SPN" SG_ 2566834734 SuspectParameterNumber8 1214;
BA_ "SPN" SG_ 2566834734 FailureModeIdentifier8 1215;
BA_ "SPN" SG_ 2566834734 OccurrenceCount8 1216;
BA_ "SPN" SG_ 2566834734 SPNConversionMethod8 1706;
BA_ "SPN" SG_ 2566834734 SuspectParameterNumber9 1214;
BA_ "SPN" SG_ 2566834734 FailureModeIdentifier9 1215;
BA_ "SPN" SG_ 2566834734 OccurrenceCount9 1216;
BA_ "SPN" SG_ 2566834734 SPNConversionMethod9 1706;
BA_ "SPN" SG_ 2566834734 SuspectParameterNumber10 1214;
BA_ "SPN" SG_ 2566834734 FailureModeIdentifier10 1215;
BA_ "SPN" SG_ 2566834734 OccurrenceCount10 1216;
BA_ "SPN" SG_ 2566834734 SPNConversionMethod10 1706;
BA_ "SPN" SG_ 2566834734 SuspectParameterNumber11 1214;
BA_ "SPN" SG_ 2566834734 FailureModeIdentifier11 1215;
BA_ "SPN" SG_ 2566834734 OccurrenceCount11 1216;
BA_ "SPN" SG_ 2566834734 SPNConversionMethod11 1706;
BA_ "SPN" SG_ 2566834734 SuspectParameterNumber12 1214;
BA_ "SPN" SG_ 2566834734 FailureModeIdentifier12 1215;
BA_ "SPN" SG_ 2566834734 OccurrenceCount12 1216;
BA_ "SPN" SG_ 2566834734 SPNConversionMethod12 1706;
BA_ "SPN" SG_ 2566834690 ProtectLamp 987;
BA_ "SPN" SG_ 2566834690 AmberWarningLamp 624;
BA_ "SPN" SG_ 2566834690 RedStopLamp 623;
BA_ "SPN" SG_ 2566834690 MalfunctionIndicatorLamp 1213;
BA_ "SPN" SG_ 2566834690 FlashProtectLamp 3041;
BA_ "SPN" SG_ 2566834690 FlashAmberWarningLamp 3040;
BA_ "SPN" SG_ 2566834690 FlashRedStopLamp 3039;
BA_ "SPN" SG_ 2566834690 FlashMalfunctionIndicatorLamp 3038;
BA_ "SPN" SG_ 2566834690 SuspectParameterNumber 1214;
BA_ "SPN" SG_ 2566834690 FailureModeIdentifier 1215;
BA_ "SPN" SG_ 2566834690 OccurrenceCount 1216;
BA_ "SPN" SG_ 2566834690 SPNConversionMethod 1706;
BA_ "SPN" SG_ 2566834690 SuspectParameterNumber2 1214;
BA_ "SPN" SG_ 2566834690 FailureModeIdentifier2 1215;
BA_ "SPN" SG_ 2566834690 OccurrenceCount2 1216;
BA_ "SPN" SG_ 2566834690 SPNConversionMethod2 1706;
BA_ "SPN" SG_ 2566834690 SuspectParameterNumber3 1214;
BA_ "SPN" SG_ 2566834690 FailureModeIdentifier3 1215;
BA_ "SPN" SG_ 2566834690 OccurrenceCount3 1216;
BA_ "SPN" SG_ 2566834690 SPNConversionMethod3 1706;
BA_ "SPN" SG_ 2566834690 SuspectParameterNumber4 1214;
BA_ "SPN" SG_ 2566834690 FailureModeIdentifier4 1215;
BA_ "SPN" SG_ 2566834690 OccurrenceCount4 1216;
BA_ "SPN" SG_ 2566834690 SPNConversionMethod4 1706;
BA_ "SPN" SG_ 2566834690 SuspectParameterNumber5 1214;
BA_ "SPN" SG_ 2566834690 FailureModeIdentifier5 1215;
BA_ "SPN" SG_ 2566834690 OccurrenceCount5 1216;
BA_ "SPN" SG_ 2566834690 SPNConversionMethod5 1706;
BA_ "SPN" SG_ 2566834690 SuspectParameterNumber6 1214;
BA_ "SPN" SG_ 2566834690 FailureModeIdentifier6 1215;
BA_ "SPN" SG_ 2566834690 OccurrenceCount6 1216;
BA_ "SPN" SG_ 2566834690 SPNConversionMethod6 1706;
BA_ "SPN" SG_ 2566834690 SuspectParameterNumber7 1214;
BA_ "SPN" SG_ 2566834690 FailureModeIdentifier7 1215;
BA_ "SPN" SG_ 2566834690 OccurrenceCount7 1216;
BA_ "SPN" SG_ 2566834690 SPNConversionMethod7 1706;
BA_ "SPN" SG_ 2566834690 SuspectParameterNumber8 1214;
BA_ "SPN" SG_ 2566834690 FailureModeIdentifier8 1215;
BA_ "SPN" SG_ 2566834690 OccurrenceCount8 1216;
BA_ "SPN" SG_ 2566834690 SPNConversionMethod8 1706;
BA_ "SPN" SG_ 2566834690 SuspectParameterNumber9 1214;
BA_ "SPN" SG_ 2566834690 FailureModeIdentifier9 1215;
BA_ "SPN" SG_ 2566834690 OccurrenceCount9 1216;
BA_ "SPN" SG_ 2566834690 SPNConversionMethod9 1706;
BA_ "SPN" SG_ 2566834690 SuspectParameterNumber10 1214;
BA_ "SPN" SG_ 2566834690 FailureModeIdentifier10 1215;
BA_ "SPN" SG_ 2566834690 OccurrenceCount10 1216;
BA_ "SPN" SG_ 2566834690 SPNConversionMethod10 1706;
BA_ "SPN" SG_ 2566834690 SuspectParameterNumber11 1214;
BA_ "SPN" SG_ 2566834690 FailureModeIdentifier11 1215;
BA_ "SPN" SG_ 2566834690 OccurrenceCount11 1216;
BA_ "SPN" SG_ 2566834690 SPNConversionMethod11 1706;
BA_ "SPN" SG_ 2566834690 SuspectParameterNumber12 1214;
BA_ "SPN" SG_ 2566834690 FailureModeIdentifier12 1215;
BA_ "SPN" SG_ 2566834690 OccurrenceCount12 1216;
BA_ "SPN" SG_ 2566834690 SPNConversionMethod12 1706;
BA_ "SPN" SG_ 2566834711 ProtectLamp 987;
BA_ "SPN" SG_ 2566834711 AmberWarningLamp 624;
BA_ "SPN" SG_ 2566834711 RedStopLamp 623;
BA_ "SPN" SG_ 2566834711 MalfunctionIndicatorLamp 1213;
BA_ "SPN" SG_ 2566834711 FlashProtectLamp 3041;
BA_ "SPN" SG_ 2566834711 FlashAmberWarningLamp 3040;
BA_ "SPN" SG_ 2566834711 FlashRedStopLamp 3039;
BA_ "SPN" SG_ 2566834711 FlashMalfunctionIndicatorLamp 3038;
BA_ "SPN" SG_ 2566834711 SuspectParameterNumber 1214;
BA_ "SPN" SG_ 2566834711 FailureModeIdentifier 1215;
BA_ "SPN" SG_ 2566834711 OccurrenceCount 1216;
BA_ "SPN" SG_ 2566834711 SPNConversionMethod 1706;
BA_ "SPN" SG_ 2566834711 SuspectParameterNumber2 1214;
BA_ "SPN" SG_ 2566834711 FailureModeIdentifier2 1215;
BA_ "SPN" SG_ 2566834711 OccurrenceCount2 1216;
BA_ "SPN" SG_ 2566834711 SPNConversionMethod2 1706;
BA_ "SPN" SG_ 2566834711 SuspectParameterNumber3 1214;
BA_ "SPN" SG_ 2566834711 FailureModeIdentifier3 1215;
BA_ "SPN" SG_ 2566834711 OccurrenceCount3 1216;
BA_ "SPN" SG_ 2566834711 SPNConversionMethod3 1706;
BA_ "SPN" SG_ 2566834711 SuspectParameterNumber4 1214;
BA_ "SPN" SG_ 2566834711 FailureModeIdentifier4 1215;
BA_ "SPN" SG_ 2566834711 OccurrenceCount4 1216;
BA_ "SPN" SG_ 2566834711 SPNConversionMethod4 1706;
BA_ "SPN" SG_ 2566834711 SuspectParameterNumber5 1214;
BA_ "SPN" SG_ 2566834711 FailureModeIdentifier5 1215;
BA_ "SPN" SG_ 2566834711 OccurrenceCount5 1216;
BA_ "SPN" SG_ 2566834711 SPNConversionMethod5 1706;
BA_ "SPN" SG_ 2566834711 SuspectParameterNumber6 1214;
BA_ "SPN" SG_ 2566834711 FailureModeIdentifier6 1215;
BA_ "SPN" SG_ 2566834711 OccurrenceCount6 1216;
BA_ "SPN" SG_ 2566834711 SPNConversionMethod6 1706;
BA_ "SPN" SG_ 2566834711 SuspectParameterNumber7 1214;
BA_ "SPN" SG_ 2566834711 FailureModeIdentifier7 1215;
BA_ "SPN" SG_ 2566834711 OccurrenceCount7 1216;
BA_ "SPN" SG_ 2566834711 SPNConversionMethod7 1706;
BA_ "SPN" SG_ 2566834711 SuspectParameterNumber8 1214;
BA_ "SPN" SG_ 2566834711 FailureModeIdentifier8 1215;
BA_ "SPN" SG_ 2566834711 OccurrenceCount8 1216;
BA_ "SPN" SG_ 2566834711 SPNConversionMethod8 1706;
BA_ "SPN" SG_ 2566834711 SuspectParameterNumber9 1214;
BA_ "SPN" SG_ 2566834711 FailureModeIdentifier9 1215;
BA_ "SPN" SG_ 2566834711 OccurrenceCount9 1216;
BA_ "SPN" SG_ 2566834711 SPNConversionMethod9 1706;
BA_ "SPN" SG_ 2566834711 SuspectParameterNumber10 1214;
BA_ "SPN" SG_ 2566834711 FailureModeIdentifier10 1215;
BA_ "SPN" SG_ 2566834711 OccurrenceCount10 1216;
BA_ "SPN" SG_ 2566834711 SPNConversionMethod10 1706;
BA_ "SPN" SG_ 2566834711 SuspectParameterNumber11 1214;
BA_ "SPN" SG_ 2566834711 FailureModeIdentifier11 1215;
BA_ "SPN" SG_ 2566834711 OccurrenceCount11 1216;
BA_ "SPN" SG_ 2566834711 SPNConversionMethod11 1706;
BA_ "SPN" SG_ 2566834711 SuspectParameterNumber12 1214;
BA_ "SPN" SG_ 2566834711 FailureModeIdentifier12 1215;
BA_ "SPN" SG_ 2566834711 OccurrenceCount12 1216;
BA_ "SPN" SG_ 2566834711 SPNConversionMethod12 1706;
BA_ "SPN" SG_ 2566834725 ProtectLamp 987;
BA_ "SPN" SG_ 2566834725 AmberWarningLamp 624;
BA_ "SPN" SG_ 2566834725 RedStopLamp 623;
BA_ "SPN" SG_ 2566834725 MalfunctionIndicatorLamp 1213;
BA_ "SPN" SG_ 2566834725 FlashProtectLamp 3041;
BA_ "SPN" SG_ 2566834725 FlashAmberWarningLamp 3040;
BA_ "SPN" SG_ 2566834725 FlashRedStopLamp 3039;
BA_ "SPN" SG_ 2566834725 FlashMalfunctionIndicatorLamp 3038;
BA_ "SPN" SG_ 2566834725 SuspectParameterNumber 1214;
BA_ "SPN" SG_ 2566834725 FailureModeIdentifier 1215;
BA_ "SPN" SG_ 2566834725 OccurrenceCount 1216;
BA_ "SPN" SG_ 2566834725 SPNConversionMethod 1706;
BA_ "SPN" SG_ 2566834725 SuspectParameterNumber2 1214;
BA_ "SPN" SG_ 2566834725 FailureModeIdentifier2 1215;
BA_ "SPN" SG_ 2566834725 OccurrenceCount2 1216;
BA_ "SPN" SG_ 2566834725 SPNConversionMethod2 1706;
BA_ "SPN" SG_ 2566834725 SuspectParameterNumber3 1214;
BA_ "SPN" SG_ 2566834725 FailureModeIdentifier3 1215;
BA_ "SPN" SG_ 2566834725 OccurrenceCount3 1216;
BA_ "SPN" SG_ 2566834725 SPNConversionMethod3 1706;
BA_ "SPN" SG_ 2566834725 SuspectParameterNumber4 1214;
BA_ "SPN" SG_ 2566834725 FailureModeIdentifier4 1215;
BA_ "SPN" SG_ 2566834725 OccurrenceCount4 1216;
BA_ "SPN" SG_ 2566834725 SPNConversionMethod4 1706;
BA_ "SPN" SG_ 2566834725 SuspectParameterNumber5 1214;
BA_ "SPN" SG_ 2566834725 FailureModeIdentifier5 1215;
BA_ "SPN" SG_ 2566834725 OccurrenceCount5 1216;
BA_ "SPN" SG_ 2566834725 SPNConversionMethod5 1706;
BA_ "SPN" SG_ 2566834725 SuspectParameterNumber6 1214;
BA_ "SPN" SG_ 2566834725 FailureModeIdentifier6 1215;
BA_ "SPN" SG_ 2566834725 OccurrenceCount6 1216;
BA_ "SPN" SG_ 2566834725 SPNConversionMethod6 1706;
BA_ "SPN" SG_ 2566834725 SuspectParameterNumber7 1214;
BA_ "SPN" SG_ 2566834725 FailureModeIdentifier7 1215;
BA_ "SPN" SG_ 2566834725 OccurrenceCount7 1216;
BA_ "SPN" SG_ 2566834725 SPNConversionMethod7 1706;
BA_ "SPN" SG_ 2566834725 SuspectParameterNumber8 1214;
BA_ "SPN" SG_ 2566834725 FailureModeIdentifier8 1215;
BA_ "SPN" SG_ 2566834725 OccurrenceCount8 1216;
BA_ "SPN" SG_ 2566834725 SPNConversionMethod8 1706;
BA_ "SPN" SG_ 2566834725 SuspectParameterNumber9 1214;
BA_ "SPN" SG_ 2566834725 FailureModeIdentifier9 1215;
BA_ "SPN" SG_ 2566834725 OccurrenceCount9 1216;
BA_ "SPN" SG_ 2566834725 SPNConversionMethod9 1706;
BA_ "SPN" SG_ 2566834725 SuspectParameterNumber10 1214;
BA_ "SPN" SG_ 2566834725 FailureModeIdentifier10 1215;
BA_ "SPN" SG_ 2566834725 OccurrenceCount10 1216;
BA_ "SPN" SG_ 2566834725 SPNConversionMethod10 1706;
BA_ "SPN" SG_ 2566834725 SuspectParameterNumber11 1214;
BA_ "SPN" SG_ 2566834725 FailureModeIdentifier11 1215;
BA_ "SPN" SG_ 2566834725 OccurrenceCount11 1216;
BA_ "SPN" SG_ 2566834725 SPNConversionMethod11 1706;
BA_ "SPN" SG_ 2566834725 SuspectParameterNumber12 1214;
BA_ "SPN" SG_ 2566834725 FailureModeIdentifier12 1215;
BA_ "SPN" SG_ 2566834725 OccurrenceCount12 1216;
BA_ "SPN" SG_ 2566834725 SPNConversionMethod12 1706;
BA_ "SPN" SG_ 2566834739 ProtectLamp 987;
BA_ "SPN" SG_ 2566834739 AmberWarningLamp 624;
BA_ "SPN" SG_ 2566834739 RedStopLamp 623;
BA_ "SPN" SG_ 2566834739 MalfunctionIndicatorLamp 1213;
BA_ "SPN" SG_ 2566834739 FlashProtectLamp 3041;
BA_ "SPN" SG_ 2566834739 FlashAmberWarningLamp 3040;
BA_ "SPN" SG_ 2566834739 FlashRedStopLamp 3039;
BA_ "SPN" SG_ 2566834739 FlashMalfunctionIndicatorLamp 3038;
BA_ "SPN" SG_ 2566834739 SuspectParameterNumber 1214;
BA_ "SPN" SG_ 2566834739 FailureModeIdentifier 1215;
BA_ "SPN" SG_ 2566834739 OccurrenceCount 1216;
BA_ "SPN" SG_ 2566834739 SPNConversionMethod 1706;
BA_ "SPN" SG_ 2566834739 SuspectParameterNumber2 1214;
BA_ "SPN" SG_ 2566834739 FailureModeIdentifier2 1215;
BA_ "SPN" SG_ 2566834739 OccurrenceCount2 1216;
BA_ "SPN" SG_ 2566834739 SPNConversionMethod2 1706;
BA_ "SPN" SG_ 2566834739 SuspectParameterNumber3 1214;
BA_ "SPN" SG_ 2566834739 FailureModeIdentifier3 1215;
BA_ "SPN" SG_ 2566834739 OccurrenceCount3 1216;
BA_ "SPN" SG_ 2566834739 SPNConversionMethod3 1706;
BA_ "SPN" SG_ 2566834739 SuspectParameterNumber4 1214;
BA_ "SPN" SG_ 2566834739 FailureModeIdentifier4 1215;
BA_ "SPN" SG_ 2566834739 OccurrenceCount4 1216;
BA_ "SPN" SG_ 2566834739 SPNConversionMethod4 1706;
BA_ "SPN" SG_ 2566834739 SuspectParameterNumber5 1214;
BA_ "SPN" SG_ 2566834739 FailureModeIdentifier5 1215;
BA_ "SPN" SG_ 2566834739 OccurrenceCount5 1216;
BA_ "SPN" SG_ 2566834739 SPNConversionMethod5 1706;
BA_ "SPN" SG_ 2566834739 SuspectParameterNumber6 1214;
BA_ "SPN" SG_ 2566834739 FailureModeIdentifier6 1215;
BA_ "SPN" SG_ 2566834739 OccurrenceCount6 1216;
BA_ "SPN" SG_ 2566834739 SPNConversionMethod6 1706;
BA_ "SPN" SG_ 2566834739 SuspectParameterNumber7 1214;
BA_ "SPN" SG_ 2566834739 FailureModeIdentifier7 1215;
BA_ "SPN" SG_ 2566834739 OccurrenceCount7 1216;
BA_ "SPN" SG_ 2566834739 SPNConversionMethod7 1706;
BA_ "SPN" SG_ 2566834739 SuspectParameterNumber8 1214;
BA_ "SPN" SG_ 2566834739 FailureModeIdentifier8 1215;
BA_ "SPN" SG_ 2566834739 OccurrenceCount8 1216;
BA_ "SPN" SG_ 2566834739 SPNConversionMethod8 1706;
BA_ "SPN" SG_ 2566834739 SuspectParameterNumber9 1214;
BA_ "SPN" SG_ 2566834739 FailureModeIdentifier9 1215;
BA_ "SPN" SG_ 2566834739 OccurrenceCount9 1216;
BA_ "SPN" SG_ 2566834739 SPNConversionMethod9 1706;
BA_ "SPN" SG_ 2566834739 SuspectParameterNumber10 1214;
BA_ "SPN" SG_ 2566834739 FailureModeIdentifier10 1215;
BA_ "SPN" SG_ 2566834739 OccurrenceCount10 1216;
BA_ "SPN" SG_ 2566834739 SPNConversionMethod10 1706;
BA_ "SPN" SG_ 2566834739 SuspectParameterNumber11 1214;
BA_ "SPN" SG_ 2566834739 FailureModeIdentifier11 1215;
BA_ "SPN" SG_ 2566834739 OccurrenceCount11 1216;
BA_ "SPN" SG_ 2566834739 SPNConversionMethod11 1706;
BA_ "SPN" SG_ 2566834739 SuspectParameterNumber12 1214;
BA_ "SPN" SG_ 2566834739 FailureModeIdentifier12 1215;
BA_ "SPN" SG_ 2566834739 OccurrenceCount12 1216;
BA_ "SPN" SG_ 2566834739 SPNConversionMethod12 1706;
BA_ "SPN" SG_ 2566834699 ProtectLamp 987;
BA_ "SPN" SG_ 2566834699 AmberWarningLamp 624;
BA_ "SPN" SG_ 2566834699 RedStopLamp 623;
BA_ "SPN" SG_ 2566834699 MalfunctionIndicatorLamp 1213;
BA_ "SPN" SG_ 2566834699 FlashProtectLamp 3041;
BA_ "SPN" SG_ 2566834699 FlashAmberWarningLamp 3040;
BA_ "SPN" SG_ 2566834699 FlashRedStopLamp 3039;
BA_ "SPN" SG_ 2566834699 FlashMalfunctionIndicatorLamp 3038;
BA_ "SPN" SG_ 2566834699 SuspectParameterNumber 1214;
BA_ "SPN" SG_ 2566834699 FailureModeIdentifier 1215;
BA_ "SPN" SG_ 2566834699 OccurrenceCount 1216;
BA_ "SPN" SG_ 2566834699 SPNConversionMethod 1706;
BA_ "SPN" SG_ 2566834699 SuspectParameterNumber2 1214;
BA_ "SPN" SG_ 2566834699 FailureModeIdentifier2 1215;
BA_ "SPN" SG_ 2566834699 OccurrenceCount2 1216;
BA_ "SPN" SG_ 2566834699 SPNConversionMethod2 1706;
BA_ "SPN" SG_ 2566834699 SuspectParameterNumber3 1214;
BA_ "SPN" SG_ 2566834699 FailureModeIdentifier3 1215;
BA_ "SPN" SG_ 2566834699 OccurrenceCount3 1216;
BA_ "SPN" SG_ 2566834699 SPNConversionMethod3 1706;
BA_ "SPN" SG_ 2566834699 SuspectParameterNumber4 1214;
BA_ "SPN" SG_ 2566834699 FailureModeIdentifier4 1215;
BA_ "SPN" SG_ 2566834699 OccurrenceCount4 1216;
BA_ "SPN" SG_ 2566834699 SPNConversionMethod4 1706;
BA_ "SPN" SG_ 2566834699 SuspectParameterNumber5 1214;
BA_ "SPN" SG_ 2566834699 FailureModeIdentifier5 1215;
BA_ "SPN" SG_ 2566834699 OccurrenceCount5 1216;
BA_ "SPN" SG_ 2566834699 SPNConversionMethod5 1706;
BA_ "SPN" SG_ 2566834699 SuspectParameterNumber6 1214;
BA_ "SPN" SG_ 2566834699 FailureModeIdentifier6 1215;
BA_ "SPN" SG_ 2566834699 OccurrenceCount6 1216;
BA_ "SPN" SG_ 2566834699 SPNConversionMethod6 1706;
BA_ "SPN" SG_ 2566834699 SuspectParameterNumber7 1214;
BA_ "SPN" SG_ 2566834699 FailureModeIdentifier7 1215;
BA_ "SPN" SG_ 2566834699 OccurrenceCount7 1216;
BA_ "SPN" SG_ 2566834699 SPNConversionMethod7 1706;
BA_ "SPN" SG_ 2566834699 SuspectParameterNumber8 1214;
BA_ "SPN" SG_ 2566834699 FailureModeIdentifier8 1215;
BA_ "SPN" SG_ 2566834699 OccurrenceCount8 1216;
BA_ "SPN" SG_ 2566834699 SPNConversionMethod8 1706;
BA_ "SPN" SG_ 2566834699 SuspectParameterNumber9 1214;
BA_ "SPN" SG_ 2566834699 FailureModeIdentifier9 1215;
BA_ "SPN" SG_ 2566834699 OccurrenceCount9 1216;
BA_ "SPN" SG_ 2566834699 SPNConversionMethod9 1706;
BA_ "SPN" SG_ 2566834699 SuspectParameterNumber10 1214;
BA_ "SPN" SG_ 2566834699 FailureModeIdentifier10 1215;
BA_ "SPN" SG_ 2566834699 OccurrenceCount10 1216;
BA_ "SPN" SG_ 2566834699 SPNConversionMethod10 1706;
BA_ "SPN" SG_ 2566834699 SuspectParameterNumber11 1214;
BA_ "SPN" SG_ 2566834699 FailureModeIdentifier11 1215;
BA_ "SPN" SG_ 2566834699 OccurrenceCount11 1216;
BA_ "SPN" SG_ 2566834699 SPNConversionMethod11 1706;
BA_ "SPN" SG_ 2566834699 SuspectParameterNumber12 1214;
BA_ "SPN" SG_ 2566834699 FailureModeIdentifier12 1215;
BA_ "SPN" SG_ 2566834699 OccurrenceCount12 1216;
BA_ "SPN" SG_ 2566834699 SPNConversionMethod12 1706;
VAL_ 2566885150 ReadToGo_BMS2 0 "Not Availabe,3" ;
VAL_ 2566885150 ErrorExists_BMS2 0 "Error Exists,1" ;
VAL_ 2566889246 MainContactorFeedback_BMS1 0 "Off" 1 "On" 2 "Error" 3 "Not Available" ;
VAL_ 2566844711 PowerSteeringPumpControl 0 "Off" 1 "On" 2 "Error" 3 "Not Available" ;
VAL_ 2566844711 ParkBrake 0 "Off" 1 "On" 2 "Error" 3 "Not Available" ;
VAL_ 2566844711 BrakeSwitch 0 "Off" 1 "On" 2 "Error" 3 "Not Available" ;
VAL_ 2566884611 AirCompressorAmberWarning 0 "Not Active" 1 "Active - No Failure" 2 "Active - Power Reduction" 3 "Error" ;
VAL_ 2566884611 WaterPumpAmberWarning 0 "Not Active" 1 "Active - No Failure" 2 "Active - Power Reduction" 3 "Error" ;
VAL_ 2566884611 HVAC1AmberWarning 0 "Not Active" 1 "Active - No Failure" 2 "Active - Power Reduction" 3 "Error" ;
VAL_ 2566884611 StatusMotor1Inverter 0 "Not Active" 1 "Active - No Failure" 2 "Active - Power Reduction" 3 "Error" ;
VAL_ 2566884611 StatusMotor2Inverter 0 "Not Active" 1 "Active - No Failure" 2 "Active - Power Reduction" 3 "Error" ;
VAL_ 2566884611 StatusAuxiliary1Inverter 0 "Not Active" 1 "Active - No Failure" 2 "Active - Power Reduction" 3 "Error" ;
VAL_ 2566884611 StatusAuxiliary2Inverter 0 "Not Active" 1 "Active - No Failure" 2 "Active - Power Reduction" 3 "Error" ;
VAL_ 2566884611 StatusES1HV_DC_DC_Inverter 0 "Not Active" 1 "Active - No Failure" 2 "Active - Power Reduction" 3 "Error" ;
VAL_ 2566884611 StatusES2HV_DC_DC_Inverter 0 "Not Active" 1 "Active - No Failure" 2 "Active - Power Reduction" 3 "Error" ;
VAL_ 2566884611 HEVMode_DICO_Status 1 "Electric Vehicle Mode" 2 "Hybrid Electric Vehicle Mode" 4 "Constant Generation Mode" 8 "Diesel Electric Mode" 12 "Charge Mode" ;
VAL_ 2566884611 EmergencyMainContactorOff 0 "Normal Operation" 1 "Open Main Contactor Immediately" 2 "Error" 3 "Not Available" ;
VAL_ 2566885123 GlobalEnablePrechargeSiemens 0 "Precharge Enabled,1" ;
VAL_ 2566885123 DNRStatus 1 "Drive Requested" 4 "Reverse Selected" 2 "Neutral" 0 "Error" 3 "Error" 5 "Error" ;
VAL_ 2566722906 BatteryCharger1State 0 "Idling" 1 "Charging Battery" 2 "Standby/Maintain" 12 "Power Reduction Active" 14 "Charger Failure" 15 "Signal Not Available" 13 "Not Supported" ;
VAL_ 2566722906 BatteryCharger1PowerlineState 0 "DC Link Voltage Available" 1 "DC Link Voltage Not Available" ;
VAL_ 2364539792 AcceleratorPedalKickdownSwitch 0 "Not Available ,3" ;
VAL_ 2364539792 AcceleratorPedal1LowIdleSwitch 0 "Not Available,3" ;
VAL_ 2566749479 TellTaleStatus 0 "Not Available,7" ;
VAL_ 2365538087 RequestedKeyStart 1 "Key Start Requested" ;
VAL_ 2365538087 VehicleForcedSpeedLimitation 0 "Not Requested" 1 "Limitation Requested" 2 "Error" 3 "Not Available" ;
VAL_ 2365538087 StatusDNRSelector 1 "Drive Requested" 4 "Reverse Selected" 2 "Neutral" 0 "Error" 3 "Error" 5 "Error" ;
VAL_ 2365538087 BrakeSwitch 0 "Off" 1 "On" 2 "Error" 3 "Not Available" ;
VAL_ 2365538087 ParkingBrakeSwitch 0 "Off" 1 "On" 2 "Error" 3 "Not Available" ;
VAL_ 2365538087 APKickdownSwitch 0 "Off" 1 "On" 2 "Error" 3 "Not Available" ;
VAL_ 2365538087 APLowIdleSwitch 0 "Off" 1 "On" 2 "Error" 3 "Not Available" ;
VAL_ 2365538087 HaltBrakeSwitch 0 "Off" 1 "On" 2 "Error" 3 "Not Available" ;
VAL_ 2365537831 HEVMode_ZR_Status 0 "ELFA System is off" 1 "EV (Electric Vehicle Mode)" 2 "HEV (Hybrid Electric Vehicle Mode)" 11 "Auxiliary Mode" 12 "CHG (Charge Mode)" 4 "CG (Constant Generation Mode)" 8 "DE (Diesel Electric Mode)" ;
VAL_ 2566842927 VehicleWeight 16 "Axle 3,47" ;
VAL_ 2565866755 SelectedGear 125 "Neutral" 126 "Drive" 124 "Reverse" ;
VAL_ 2566802983 PositionOfDoor 2 "Front Door Closed" 0 "FrontDoorOpened" 1 "Door 2 N5D004 Closed" ;
VAL_ 2566802983 SwithNoPressureDoor2 0 "No Pressure" 1 "Pressure" ;
VAL_ 2566802983 RampWheelchairLift 1 "WCL Active" 0 "WCL Not-Active" ;
VAL_ 2566802983 OpenStatusDoor1 1 "Front Door Open" 0 "Front Door Closed" ;
VAL_ 2566900297 PortAVoltagePolarity 0 "Negative" 1 "Positive" ;
VAL_ 2566701658 OverspeedIndicator 1 "Max Speed Exceeded" ;
VAL_ 2565865739 ASREngineControlActive 0 "Control Passive but Installed" 1 "Control Active" 2 "Error" 3 "Not Available" ;
VAL_ 2565865739 ASRBrakeControlActive 0 "Control Passive but Installed" 1 "Control Active" 2 "Error" 3 "Not Available" ;
VAL_ 2565865739 ABSActive 0 "Control Passive but Installed" 1 "Control Active" 2 "Error" 3 "Not Available" ;
VAL_ 2565865739 EBSBrakeSwitch 0 "Switch Input Not Used" 1 "Switch Input Used" 2 "Error" 3 "Not available" ;
VAL_ 2566769959 WiperSpeed 1 "Off" 3 "Low Speed" 9 "Interval Speed" 7 "High Speed" ;
VAL_ 2566900553 PortBVoltagePolarity 0 "Negative" 1 "Positive" ;
VAL_ 2364539904 EngineTorqueMode 0 "+0.00%" 1 "+0.125%" 2 "+0.250%" 3 "+0.375%" 4 "+0.500%" 5 "+0.625%" 6 "0.750%" 7 "+0.875%" 8 "N/A" 9 "N/A" 10 "N/A" 11 "N/A" 12 "N/A" 13 "N/A" 14 "N/A" 15 "N/A" ;
VAL_ 2364539904 EngineStarterMode 0 "Start Not Requested" 1 "Starter Active, gear not engaged" 2 "Starter active, gear engaged" 3 "Start finished, starter not active after being active" 4 "Starter inhibited due to engine already running" 5 "Starter inhibited due to engine not ready for start (preheating)" 6 "Starter inhibited due to driveline engaged or transmission inhibit" 7 "Starter inhibited due to active immobilizer" 8 "Starter inhibited due to starter over-temp" 9 "Starter inhibited due to intake air shutoff valve being active" 10 "Starter inhibited due to active SCR inducement" 11 "Reserved" 12 "Starter inhibited - reason unknown" 13 "error" 14 "Error" 15 "Not Available" ;
VAL_ 2565865488 RetarderEnabledBrakeAssistSwitch 0 "Disabled" 1 "Enabled" 2 "Error" 3 "Not Available" ;
VAL_ 2565865488 RetarderEnabledShiftAssist 0 "Disabled" 1 "Enabled" 2 "Error" 3 "Not Available" ;
VAL_ 2348810243 EngineOverrideControlMode 0 "Override disabled" 1 "Speed control" 2 "Torque control" 3 "Speed/torque limit control" ;
VAL_ 2348810243 EngRequestedSpeedCtrlConditions 0 "Transient Optimized for driveline disengaged and non-lockup conditions" 1 "Stability Optimized for driveline disengaged and non-lockup conditions" 2 "Stability Optimized for driveline engaged and/or in lockup condition 1" 3 "Stability Optimized for driveline engaged and/or in lockup condition 2" ;
VAL_ 2348810243 OverrideControlModePriority 0 "Highest priority" 1 "High priority" 2 "Medium priority" 3 "Low priority" ;
VAL_ 2348810243 TSC1TransmissionRate 0 "1000 ms transmission rate" 1 "750 ms transmission rate" 2 "500 ms transmission rate" 3 "250 ms transmission rate" 4 "100 ms transmission rate" 5 "50 ms transmission rate" 6 "20 ms transmission rate" 7 "Use standard" ;
VAL_ 2348810243 TSC1ControlPurpose 0 "P1 : Accelerator Pedal/Operator Selection" 1 "P2 : Cruise Control" 2 "P3 : PTO Governor" 3 "P4 : Road Speed Governor" 4 "P5 : Engine Protection" 5 "P6 : Transient-Optimized Torque Limit" 6 "P7 : Automated Driving System Input" 7 "P8-P31 : Reserved for SAE Assignment" 31 "P32 : Temporary Powertrain Control" ;
VAL_ 2348810243 EngineRequestedTorque 0 "+0.000%" 1 "+0.125%" 2 "+0.250%" 3 "+0.375%" 4 "+0.500%" 5 "+0.625%" 6 "+0.750%" 7 "+0.875%" 8 "not available" ;
VAL_ 2364539395 TransmissionDrivelineEngaged 0 "Driveline disengaged" 1 "Driveline engaged" 2 "Error" 3 "Not available" ;
VAL_ 2364539395 TransmissionTrqCnvLockupEngaged 0 "Torque converter lockup disengaged" 1 "Torque converter lockup engaged" 2 "Error" 3 "Not available" ;
VAL_ 2364539395 TransmissionShiftInProcess 0 "Shift is not in process" 1 "Shift in process" 2 "Error" 3 "Not available" ;
VAL_ 2364539395 TrnsmTrqCnvLockupTrnstionInPrcss 0 "Transition is not in process" 1 "Transition is in process" 2 "Error" 3 "Not available" ;
VAL_ 2364539395 EngineMomentaryOverspeedEnable 0 "Momentary engine overspeed is disabled" 1 "Momentary engine overspeed is enabled" 2 "Reserved" 3 "Take no action" ;
VAL_ 2364539395 ProgressiveShiftDisable 0 "Progressive shift is not disabled" 1 "Progressive shift is disabled" 2 "Reserved" 3 "Take no action" ;
VAL_ 2364539395 MomentaryEngineMaximumPowerEnbl 0 "not requesting maximum power available" 1 "momentarily requesting maximum power available" 2 "fault" 3 "not available" ;
VAL_ 2431649768 LaneDepartureLeft 0 "Middle of the vehicle not depart" 1 "Middle of the vehicle departs" 2 "Reserved" 3 "Take no action" ;
VAL_ 2431649768 LaneDepartureRight 0 "Middle of the vehicle not depart" 1 "Middle of the vehicle departs" 2 "Reserved" 3 "Take no action" ;
VAL_ 2431649768 LaneDepartureImminent_RightSide 0 "Not imminent" 1 "Imminent" 2 "Reserved" 3 "Not Used" ;
VAL_ 2431649768 LaneDepartureImminent_LeftSide 0 "Not imminent" 1 "Imminent" 2 "Reserved" 3 "Not Used" ;
VAL_ 2431649768 DriverAlertnessWarning 0 "No distracted driving condition detected" 1 "Level 1" 2 "Level 2" 3 "Level 3" 4 "Reserved" 7 "Not Available" ;
VAL_ 2431649768 RghtSdeLaneDepartrOptclWrngCmd 0 "No optical warning on the right side" 1 "Active optical warning on the right side" 2 "Reserved" 3 "Not available" ;
VAL_ 2431649768 LftSdeLaneDepartrOptclWarningCmd 0 "No optical warning on the left side" 1 "Active optical warning on the left side" 2 "Reserved" 3 "Not available" ;
VAL_ 2431649768 RghtSdeLaneDepartrAcstclWrngCmd 0 "No acoustical warning on the right side" 1 "Active acoustical warning on the right side" 2 "Reserved" 3 "Not available" ;
VAL_ 2431649768 LftSdeLaneDepartrAcstclWrngCmd 0 "No acoustical warning on the left side" 1 "Active acoustical warning on the left side" 2 "Reserved" 3 "Not available" ;
VAL_ 2431649768 RghtSdeLaneDepartrHapticWrngCmd 0 "No haptic warning on the right side" 1 "Active haptic warning on the right side" 2 "Reserved" 3 "Not available" ;
VAL_ 2431649768 LftSdeLaneDepartrHapticWrngCmd 0 "No haptic warning on the left side" 1 "Active haptic warning on the left side" 2 "Reserved" 3 "Not available" ;
VAL_ 2565867787 SteeringWheelAngleSensorType 0 "Relative measuring principle" 1 "Absolute measuring principle" 2 "Reserved" 3 "Not Available" ;
VAL_ 2566806504 LaneTrackingStatusRightSide 0 "Not Tracking Right side" 1 "Tracking Right side" 2 "Reserved" 3 "Don't Care/take no action" ;
VAL_ 2566806504 LaneTrackingStatusLeftSide 0 "Not Tracking Left side" 1 "Tracking Left side" 2 "Reserved" 3 "Don't care/Take no action" ;
VAL_ 2566806504 LaneDePrtureIndicationEnblStatus 0 "Lane Departure indication disabled" 1 "Lane Departure Indication enabled" 2 "Reserved" 3 "Not Used" ;
VAL_ 2566806504 DrvrAlertnessWarningSystemState 0 "System installed but disabled" 1 "Initializing" 2 "System temporarily not available" 3 "System available" 4 "System monitoring driver behavior" 5 "Reserved" 7 "Not Available / Not Installed" ;
VAL_ 2566806504 LeftWheelLaneDepartureDistance 251 "Greater than 125 cm / Not in range" 252 "Lane marker not reliable" 253 "Reserved" 254 "Error" 255 "Not available" ;
VAL_ 2566806504 RightWheelLaneDepartureDistance 251 "not in range" 252 "not reliable" 253 "reserved / not used" 254 "error" 255 "not available or not installed" ;
VAL_ 2566806504 LaneDepartureWarningSystemState 0 "System is not ready" 1 "System is temporarily not available" 2 "System is deactivated by driver" 3 "System is ready" 4 "Active warning suppressed by operator behavior" 5 "System is warning lane departure" 6 "Reserved" 14 "Error" 15 "Not available" ;
VAL_ 2566806504 ForwardLaneImagerStatus 0 "Imager fully operational" 1 "Imager warming up / initializing" 2 "Imager partially blocked / partially blind" 3 "Imager fully blocked / fully blind" 4 "Imager misaligned" 5 "Imager view degraded but functional" 6 "Reserved" 14 "Error" 15 "Not Available" ;
VAL_ 2566767627 BrakeTemperatureWarning 0 "Not Active" 1 "Active" 2 "Reserved" 3 "not available" ;
VAL_ 2566767627 HaltBrakeMode 0 "Inactive" 1 "Active" 2 "Active, but not functioning properly" 3 "Not defined" 6 "Halt brake not functional" 7 "Not available" ;
VAL_ 2566767627 HillHolderMode 0 "Inactive" 1 "Active" 2 "Active change to inactive" 3 "Active activate brake" 4 "Reserved" 6 "Hill holder not functional" 7 "Not available" ;
VAL_ 2566767627 FoundationBrakeUse 0 "Foundation brakes not in use" 1 "Foundation brakes in use" 2 "Reserved" 3 "Not available" ;
VAL_ 2566767627 XBRSystemState 0 "Any external brake" 1 "Only external brake XBR Priority 00b" 2 "No external brake" 3 "not available" ;
VAL_ 2566767627 XBRActiveControlMode 0 "No brake" 1 "Driver's brake" 2 "Addition mode of XBR" 3 "Maximum mode of XBR" 4 "XBR Brake Hold" 5 "Reserved for SAE assignment" 15 "Not available" ;
VAL_ 2566767627 ParkingBrakeActuatorFullyActvtd 0 "Parking Brake Actuator not fully activated" 1 "Parking Brake Actuator fully activated" 2 "Error" 3 "Not available" ;
VAL_ 2566767627 EmergencyBrakingActive 0 "inactive" 1 "active" 2 "reserved" 3 "not available" ;
VAL_ 2566767627 RailroadMode 0 "Inactive (Driving mode: Steer Axle on ground)" 1 "Active (Railroad mode: Steer Axle lifted off ground)" 2 "Error" 3 "Not available" ;
VAL_ 2566767627 XBRBrakeHoldMode 0 "Inactive" 1 "Active" 2 "Active but will change to inactive in a short time" 3 "Active but may activate parking brake if needed" 4 "Active but restricted functionality due to faults detected" 5 "XBR Brake Hold Request is not accepted due to boundary conditions not met" 6 "Reserved" 14 "XBR Brake Hold not functional/error" 15 "Not available" ;
VAL_ 2566844762 TwoSpeedAxleSwitch 0 "Low speed range" 1 "High speed range" 2 "Error" 3 "Not available" ;
VAL_ 2566844762 ParkingBrakeSwitch 0 "Parking brake not set" 1 "Parking brake set" 2 "Error" 3 "Not available" ;
VAL_ 2566844762 CruiseControlPauseSwitch 0 "Off" 1 "On" 2 "Error Indicator" 3 "Take No Action" ;
VAL_ 2566844762 ParkBrakeReleaseInhibitRequest 0 "Park Brake Release Inhibit not requested" 1 "Park Brake Release Inhibit requested" 2 "SAE reserved" 3 "Unavailable" ;
VAL_ 2566844762 CruiseControlActive 0 "Cruise control switched off" 1 "Cruise control switched on" 2 "Error" 3 "Not available" ;
VAL_ 2566844762 CruiseControlEnableSwitch 0 "Cruise control disabled" 1 "Cruise control enabled" 2 "Error" 3 "Not available" ;
VAL_ 2566844762 BrakeSwitch_CCVS1_Signal 0 "Brake pedal released" 1 "Brake pedal depressed" 2 "Error" 3 "Not Available" ;
VAL_ 2566844762 ClutchSwitch 0 "Clutch pedal released" 1 "Clutch pedal depressed" 2 "Error" 3 "Not available" ;
VAL_ 2566844762 CruiseControlSetSwitch 0 "Cruise control activator not in the position 'set'" 1 "Cruise control activator in position 'set'" 2 "Error" 3 "Not available" ;
VAL_ 2566844762 CruiseControlCoastSwitch 0 "Cruise control activator not in the position 'coast'" 1 "Cruise control activator in position 'coast'" 2 "Error" 3 "Not available" ;
VAL_ 2566844762 CruiseControlResumeSwitch 0 "Cruise control activator not in the position 'resume'" 1 "Cruise control activator in position 'resume'" 2 "Error" 3 "Not available" ;
VAL_ 2566844762 CruiseControlAccelerateSwitch 0 "Cruise control activator not in the position 'accelerate'" 1 "Cruise control activator in position 'accelerate'" 2 "Error" 3 "Not available" ;
VAL_ 2566844762 PTOGovernorState 0 "Off/Disabled" 1 "Hold" 2 "Remote Hold" 3 "Standby" 4 "Remote Standby" 5 "Set" 6 "Decelerate/Coast" 7 "Resume" 8 "Accelerate" 9 "Accelerator Override" 10 "Preprogrammed set speed 1" 11 "Preprogrammed set speed 2" 12 "Preprogrammed set speed 3" 13 "Preprogrammed set speed 4" 14 "Preprogrammed set speed 5" 15 "Preprogrammed set speed 6" 16 "Preprogrammed set speed 7" 17 "Preprogrammed set speed 8" 18 "PTO set speed memory 1" 19 "PTO set speed memory 2" 20 "PTO set speed memory 3" 21 "Not defined" 31 "Not available" ;
VAL_ 2566844762 CruiseControlStates 0 "Off/Disabled" 1 "Hold" 2 "Accelerate" 3 "Decelerate" 4 "Resume" 5 "Set" 6 "Accelerator Override" 7 "Not available" ;
VAL_ 2566844762 EngineIdleIncrementSwitch 0 "Off" 1 "On" 2 "Error" 3 "Not available" ;
VAL_ 2566844762 EngineIdleDecrementSwitch 0 "Off" 1 "On" 2 "Error" 3 "Not available" ;
VAL_ 2566844762 EngineDiagnosticTestModeSwitch 0 "Off" 1 "On" 2 "Error" 3 "Not available" ;
VAL_ 2566844762 EngineShutdownOverrideSwitch 0 "Off" 1 "On" 2 "Error" 3 "Not available" ;
VAL_ 2365443111 WorkLightSwitch 0 "Off" 1 "Work Light Combination #1 On" 2 "Work Light Combination #2 On" 3 "Work Light Combination #3 On" 4 "Work Light Combination #4 On" 5 "Reserved" 14 "Error" 15 "Not available (do not change)" ;
VAL_ 2365443111 MainLightSwitch 0 "Off" 1 "Park On" 2 "Headlight On" 3 "Headlight and Park On" 4 "Automatic Lights" 5 "Reserved" 8 "Delayed Off" 9 "Reserved" 14 "Error" 15 "Not available (do not change)" ;
VAL_ 2365443111 TurnSignalSwitch 0 "No Turn being signaled" 1 "Left Turn to be Flashing" 2 "Right turn to be Flashing" 3 "Reserved" 14 "Error" 15 "Not available" ;
VAL_ 2365443111 HazardLightSwitch 0 "Hazard Lamps to be Off" 1 "Hazard Lamps to be Flashing" 2 "Error" 3 "Not available (do not change)" ;
VAL_ 2365443111 HighLowBeamSwitch 0 "Low Beam Selected" 1 "High Beam Selected" 2 "Error" 3 "Not available (do not change)" ;
VAL_ 2365443111 ExteriorLampCheckSwitch 0 "Exterior lamp check inactive" 1 "Exterior lamp check active" 2 "Error" 3 "Not available" ;
VAL_ 2365443111 HeadlampEmergencyFlashSwitch 0 "Headlamp emergency flash inactive" 1 "Headlamp emergency flash active" 2 "Error" 3 "Not available" ;
VAL_ 2365443111 AuxiliaryLampGroupSwitch 0 "Off" 1 "On" 2 "Error" 3 "Not available" ;
VAL_ 2365443111 AutoHighLowBeamEnableSwitch 0 "Auto High/Low Beam Switch disabled" 1 "Auto High/Low Beam Switch enabled" 2 "Error" 3 "Not available" ;
VAL_ 2566803211 VDCInformationSignal 0 "Off" 1 "On" 2 "Reserved" 3 "Don't care/take no action" ;
VAL_ 2566803211 VDCFullyOperational 0 "Not fully operational" 1 "Fully operational" 2 "Reserved" 3 "Don't care/Take no action" ;
VAL_ 2566803211 VDCBrakeLightRequest 0 "Turn brake light not on" 1 "Turn brake light on" 2 "Reserved" 3 "Don't care/Take no action" ;
VAL_ 2566803211 ROPEngineControlActive 0 "ROP engine control passive but installed" 1 "ROP engine control active" 2 "Reserved" 3 "Don't care/Take no action" ;
VAL_ 2566803211 ROPBrakeControlActive 0 "ROP brake control passive but installed" 1 "ROP brake control active" 2 "Reserved" 3 "Don't care/Take no action" ;
VAL_ 2566803211 YCEngineControlActive 0 "YC engine control passive but installed" 1 "YC engine control active" 2 "Reserved" 3 "Don't care/Take no action" ;
VAL_ 2566803211 YCBrakeControlActive 0 "YC brake control passive but installed" 1 "YC brake control active" 2 "Reserved" 3 "Don't care/Take no action" ;
VAL_ 2566803211 TrailerVDCActive 0 "VDC passive, but installed" 1 "VDC active" 2 "Reserved" 3 "Not availble or not installed" ;
VAL_ 2365479471 NominalLevelFrontAxle 0 "Level not specified" 1 "Normal Level 1" 2 "Normal Level 2" 3 "Normal Level 3" 4 "Preset Level" 5 "Customer Level" 6 "Upper Level" 7 "Lower Level" 8 "Level change stopped" 9 "Raising" 10 "Lowering" 11 "Reserved" 14 "Error" 15 "Not available" ;
VAL_ 2365479471 NominalLevelRearAxle 0 "Level not specified" 1 "Normal Level 1" 2 "Normal Level 2" 3 "Normal Level 3" 4 "Preset Level" 5 "Customer Level" 6 "Upper Level" 7 "Lower Level" 8 "Level change stopped" 9 "Raising" 10 "Lowering" 11 "Reserved" 14 "Error" 15 "Not available" ;
VAL_ 2365479471 BelowNominalLevelFrontAxle 0 "Not below" 1 "Below" 2 "Error" 3 "Not available" ;
VAL_ 2365479471 BelowNominalLevelRearAxle 0 "Not below" 1 "Below" 2 "Error" 3 "Not available" ;
VAL_ 2365479471 AboveNominalLevelFrontAxle 0 "Not above" 1 "Above" 2 "Error" 3 "Not available" ;
VAL_ 2365479471 AboveNominalLevelRearAxle 0 "Not above" 1 "Above" 2 "Error" 3 "Not available" ;
VAL_ 2365479471 LoweringControlModeFrontAxle 0 "Lowering not active" 1 "Lowering active" 2 "Error" 3 "Not available" ;
VAL_ 2365479471 LoweringControlModeRearAxle 0 "Lowering not active" 1 "Lowering active" 2 "Error" 3 "Not available" ;
VAL_ 2365479471 LiftingControlModeFrontAxle 0 "Lifting not active" 1 "Lifting active" 2 "Error" 3 "Not available" ;
VAL_ 2365479471 LiftingControlModeRearAxle 0 "Lifting not active" 1 "Lifting active" 2 "Error" 3 "Not available" ;
VAL_ 2365479471 KneelingInformation 0 "Not active" 1 "Lowering active" 2 "Kneeling level reached" 3 "Lifting active" 4 "Kneeling aborted" 5 "Not defined" 14 "Error" 15 "Not available" ;
VAL_ 2365479471 LevelControlMode 0 "Normal operation" 1 "Traction help (load transfer)" 2 "Load fixing" 3 "Pressure ratio 1" 4 "Pressure ratio 2" 5 "Optimum traction 1" 6 "Optimum traction 2" 7 "Traction help" 8 "Exhausting bellow function" 9 "Air suspension control prohibited" 10 "Automatic air suspension control prohibited" 11 "Force to bumper level request is in effect" 12 "Not defined" 14 "Error" 15 "Not available" ;
VAL_ 2365479471 SecurityDevice 0 "not active" 1 "active" 2 "error" 3 "not available" ;
VAL_ 2365479471 VehicleMotionInhibit 0 "Vehicle may be moved" 1 "Vehicle motion is inhibited" 2 "Error" 3 "Not available" ;
VAL_ 2365479471 DoorRelease 0 "Doors may not be opened" 1 "Doors may be opened" 2 "Error" 3 "Not available" ;
VAL_ 2365479471 LiftAxle1Position 0 "Lift axle position down / tag axle laden" 1 "Lift axle position up / tag axle unladen" 2 "Error" 3 "Not available" ;
VAL_ 2365479471 FrontAxleInBumperRange 0 "Actual level out of bumper range" 1 "Actual level within bumper range" 2 "Error" 3 "Not available" ;
VAL_ 2365479471 RearAxleInBumperRange 0 "Actual level out of bumper range" 1 "Actual level within bumper range" 2 "Error" 3 "Not available" ;
VAL_ 2365479471 LiftAxle2Position 0 "Lift axle position down / tag axle laden" 1 "Lift axle position up / tag axle unladen" 2 "Error" 3 "Not available" ;
VAL_ 2365479471 SuspensionRemoteControl1 0 "not active" 1 "active" 2 "error" 3 "not available" ;
VAL_ 2365479471 SuspensionRemoteControl2 0 "not active" 1 "active" 2 "error" 3 "not available" ;
VAL_ 2365479471 AllowLevelCtrlDuringBrkngStatus 0 "Deactivated" 1 "Activated" 2 "Reserved" 3 "Don't care/take no action" ;
VAL_ 2365479471 SpeedDependantLevelControlStatus 0 "Inactive" 1 "Active" 2 "Reserved" 3 "Don't care/take no action" ;
VAL_ 2365479471 SuspensionCtrlRefusalInformation 0 "Actual request not refused" 1 "Axle load limit reached  (load transfer)" 2 "Would exceed axle load limit (tag axle)" 3 "Bogie differential not locked" 4 "Above speed limit" 5 "Below speed limit" 6 "General reject" 7 "Requested level not available" 8 "Not defined" 14 "Error" 15 "Not available" ;
VAL_ 2365479471 MemoryLevel 0 "No memory level" 1 "Memory level 1 selected" 2 "Memory level 2 selected" 3 "Memory level 3 selected" 4 "Memory level 4 selected" 5 "Memory level 5 selected" 6 "reserved" 9 "Memory level  1 stored" 10 "Memory level  2 stored" 11 "Memory level  3 stored" 12 "Memory level  4 stored" 13 "Memory level  5 stored" 14 "Error indicator" 15 "not available" ;
VAL_ 2348875518 EngineOverrideControlMode 0 "Override disabled" 1 "Speed control" 2 "Torque control" 3 "Speed/torque limit control" ;
VAL_ 2348875518 EngRequestedSpeedCtrlConditions 0 "Transient Optimized for driveline disengaged and non-lockup conditions" 1 "Stability Optimized for driveline disengaged and non-lockup conditions" 2 "Stability Optimized for driveline engaged and/or in lockup condition 1" 3 "Stability Optimized for driveline engaged and/or in lockup condition 2" ;
VAL_ 2348875518 OverrideControlModePriority 0 "Highest priority" 1 "High priority" 2 "Medium priority" 3 "Low priority" ;
VAL_ 2348875518 TSC1TransmissionRate 0 "1000 ms transmission rate" 1 "750 ms transmission rate" 2 "500 ms transmission rate" 3 "250 ms transmission rate" 4 "100 ms transmission rate" 5 "50 ms transmission rate" 6 "20 ms transmission rate" 7 "Use standard" ;
VAL_ 2348875518 TSC1ControlPurpose 0 "P1 : Accelerator Pedal/Operator Selection" 1 "P2 : Cruise Control" 2 "P3 : PTO Governor" 3 "P4 : Road Speed Governor" 4 "P5 : Engine Protection" 5 "P6 : Transient-Optimized Torque Limit" 6 "P7 : Automated Driving System Input" 7 "P8-P31 : Reserved for SAE Assignment" 31 "P32 : Temporary Powertrain Control" ;
VAL_ 2348875518 EngineRequestedTorque 0 "+0.000%" 1 "+0.125%" 2 "+0.250%" 3 "+0.375%" 4 "+0.500%" 5 "+0.625%" 6 "+0.750%" 7 "+0.875%" 8 "not available" ;
VAL_ 2632777470 TPCM_Mux 16 "RTS" 17 "CTS" 19 "EoM_ACK" 32 "BAM" 255 "ConnAbort" ;
VAL_ 2632777470 ConnectionAbortReason 1 "Already connected" 2 "System resources needed" 3 "Timeout occurred" 4 "CTS messages received when data transfer is in progress" 5 "Maximum retransmit request limit reached" 6 "Unexpected data transfer packet" 7 "Bad sequence number" 8 "Duplicate sequence number" 9 "TotalMessageSize is greater than 1785 bytes" 10 "Reserved for SAE assignment." 250 "Not listed Abort reason" 251 "Per J1939-71 definitions" ;
VAL_ 2566845491 TireLocation 0 "Left Front Tire" 1 "Right Front Tire" 16 "Left Outside Drive" 17 "Left Inside Drive" 18 "Right Inside Drive" 19 "Right Outside Drive" 32 "Left Tag" 33 "Right Tag" ;
VAL_ 2566845491 CTIWheelEndElectricalLowBattery 0 "OK - No Fault - Battery OK" 1 "Not Defined" 2 "Error - Low Battery Condition" 3 "No Data" ;
VAL_ 2566849331 TireLocation 0 "Left Front Tire" 1 "Right Front Tire" 16 "Left Outside Drive" 17 "Left Inside Drive" 18 "Right Inside Drive" 19 "Right Outside Drive" 32 "Left Tag" 33 "Right Tag" ;
VAL_ 2566849331 LFWaveform 0 "None" 1 "Initiation" 2 "Learn" 3 "De-energize" 4 "Factory" 5 "Pressure Change" 6 "EOL" 7 "Reserved" ;
VAL_ 2566849331 SensorStatus 0 "No Change" 1 "De-energize" 2 "Factory Stationary" 3 "Factory Rolling" 4 "Normal Stationary" 5 "Normal Rolling" 6 "Fast Transmit" 7 "Reserved" ;
VAL_ 2566849331 SensorType 3 "External High Pressure" 4 "Low Pressure" 5 "High Pressure" 7 "No Sensor Type" ;
VAL_ 2566849331 DeviationPosNeg 0 "Positive" 1 "Negative" ;
VAL_ 2566850611 TireLocation 0 "Left Front Tire" 1 "Right Front Tire" 16 "Left Outside Drive" 17 "Left Inside Drive" 18 "Right Inside Drive" 19 "Right Outside Drive" 32 "Left Tag" 33 "Right Tag" ;
VAL_ 2566834735 ProtectLamp 0 "Lamp Off" 1 "Lamp On" 2 "Reserved" 3 "Not available" ;
VAL_ 2566834735 AmberWarningLamp 0 "Lamp Off" 1 "Lamp On" 2 "Reserved" 3 "Not available" ;
VAL_ 2566834735 RedStopLamp 0 "Lamp Off" 1 "Lamp On" 2 "Reserved" 3 "Not available" ;
VAL_ 2566834735 MalfunctionIndicatorLamp 0 "Lamp Off" 1 "Lamp On" 2 "Short MIL for WWH OBD" 3 "Not available" ;
VAL_ 2566834735 FlashProtectLamp 0 "Slow Flash (1 Hz, 50 % duty cycle)" 1 "Fast Flash (2 Hz or faster, 50% duty cycle)" 2 "Reserved" 3 "Unavailable / Do Not Flash" ;
VAL_ 2566834735 FlashAmberWarningLamp 0 "Slow Flash (1 Hz, 50 % duty cycle)" 1 "Fast Flash (2 Hz or faster, 50% duty cycle)" 2 "Reserved" 3 "Unavailable / Do Not Flash" ;
VAL_ 2566834735 FlashRedStopLamp 0 "Slow Flash (1 Hz, 50 % duty cycle)" 1 "Fast Flash (2 Hz or faster, 50% duty cycle)" 2 "Reserved" 3 "Unavailable / Do Not Flash" ;
VAL_ 2566834735 FlashMalfunctionIndicatorLamp 0 "Slow Flash (1 Hz, 50 % duty cycle)" 1 "Fast Flash (2 Hz or faster, 50% duty cycle)" 2 "Class C DTC" 3 "Unavailable / Do Not Flash" ;
VAL_ 2566834735 SPNConversionMethod 0 "Convert SPN per Version 4" 1 "Convert SPN per Version 1, 2 or 3" ;
VAL_ 2566834735 SPNConversionMethod2 0 "Convert SPN per Version 4" 1 "Convert SPN per Version 1, 2 or 3" ;
VAL_ 2566834735 SPNConversionMethod3 0 "Convert SPN per Version 4" 1 "Convert SPN per Version 1, 2 or 3" ;
VAL_ 2566834735 SPNConversionMethod4 0 "Convert SPN per Version 4" 1 "Convert SPN per Version 1, 2 or 3" ;
VAL_ 2566834735 SPNConversionMethod5 0 "Convert SPN per Version 4" 1 "Convert SPN per Version 1, 2 or 3" ;
VAL_ 2566834735 SPNConversionMethod6 0 "Convert SPN per Version 4" 1 "Convert SPN per Version 1, 2 or 3" ;
VAL_ 2566834735 SPNConversionMethod7 0 "Convert SPN per Version 4" 1 "Convert SPN per Version 1, 2 or 3" ;
VAL_ 2566834735 SPNConversionMethod8 0 "Convert SPN per Version 4" 1 "Convert SPN per Version 1, 2 or 3" ;
VAL_ 2566834735 SPNConversionMethod9 0 "Convert SPN per Version 4" 1 "Convert SPN per Version 1, 2 or 3" ;
VAL_ 2566834735 SPNConversionMethod10 0 "Convert SPN per Version 4" 1 "Convert SPN per Version 1, 2 or 3" ;
VAL_ 2566834735 SPNConversionMethod11 0 "Convert SPN per Version 4" 1 "Convert SPN per Version 1, 2 or 3" ;
VAL_ 2566834735 SPNConversionMethod12 0 "Convert SPN per Version 4" 1 "Convert SPN per Version 1, 2 or 3" ;
VAL_ 2566834737 ProtectLamp 0 "Lamp Off" 1 "Lamp On" 2 "Reserved" 3 "Not available" ;
VAL_ 2566834737 AmberWarningLamp 0 "Lamp Off" 1 "Lamp On" 2 "Reserved" 3 "Not available" ;
VAL_ 2566834737 RedStopLamp 0 "Lamp Off" 1 "Lamp On" 2 "Reserved" 3 "Not available" ;
VAL_ 2566834737 MalfunctionIndicatorLamp 0 "Lamp Off" 1 "Lamp On" 2 "Short MIL for WWH OBD" 3 "Not available" ;
VAL_ 2566834737 FlashProtectLamp 0 "Slow Flash (1 Hz, 50 % duty cycle)" 1 "Fast Flash (2 Hz or faster, 50% duty cycle)" 2 "Reserved" 3 "Unavailable / Do Not Flash" ;
VAL_ 2566834737 FlashAmberWarningLamp 0 "Slow Flash (1 Hz, 50 % duty cycle)" 1 "Fast Flash (2 Hz or faster, 50% duty cycle)" 2 "Reserved" 3 "Unavailable / Do Not Flash" ;
VAL_ 2566834737 FlashRedStopLamp 0 "Slow Flash (1 Hz, 50 % duty cycle)" 1 "Fast Flash (2 Hz or faster, 50% duty cycle)" 2 "Reserved" 3 "Unavailable / Do Not Flash" ;
VAL_ 2566834737 FlashMalfunctionIndicatorLamp 0 "Slow Flash (1 Hz, 50 % duty cycle)" 1 "Fast Flash (2 Hz or faster, 50% duty cycle)" 2 "Class C DTC" 3 "Unavailable / Do Not Flash" ;
VAL_ 2566834737 SPNConversionMethod 0 "Convert SPN per Version 4" 1 "Convert SPN per Version 1, 2 or 3" ;
VAL_ 2566834737 SPNConversionMethod2 0 "Convert SPN per Version 4" 1 "Convert SPN per Version 1, 2 or 3" ;
VAL_ 2566834737 SPNConversionMethod3 0 "Convert SPN per Version 4" 1 "Convert SPN per Version 1, 2 or 3" ;
VAL_ 2566834737 SPNConversionMethod4 0 "Convert SPN per Version 4" 1 "Convert SPN per Version 1, 2 or 3" ;
VAL_ 2566834737 SPNConversionMethod5 0 "Convert SPN per Version 4" 1 "Convert SPN per Version 1, 2 or 3" ;
VAL_ 2566834737 SPNConversionMethod6 0 "Convert SPN per Version 4" 1 "Convert SPN per Version 1, 2 or 3" ;
VAL_ 2566834737 SPNConversionMethod7 0 "Convert SPN per Version 4" 1 "Convert SPN per Version 1, 2 or 3" ;
VAL_ 2566834737 SPNConversionMethod8 0 "Convert SPN per Version 4" 1 "Convert SPN per Version 1, 2 or 3" ;
VAL_ 2566834737 SPNConversionMethod9 0 "Convert SPN per Version 4" 1 "Convert SPN per Version 1, 2 or 3" ;
VAL_ 2566834737 SPNConversionMethod10 0 "Convert SPN per Version 4" 1 "Convert SPN per Version 1, 2 or 3" ;
VAL_ 2566834737 SPNConversionMethod11 0 "Convert SPN per Version 4" 1 "Convert SPN per Version 1, 2 or 3" ;
VAL_ 2566834737 SPNConversionMethod12 0 "Convert SPN per Version 4" 1 "Convert SPN per Version 1, 2 or 3" ;
VAL_ 2566834761 ProtectLamp 0 "Lamp Off" 1 "Lamp On" 2 "Reserved" 3 "Not available" ;
VAL_ 2566834761 AmberWarningLamp 0 "Lamp Off" 1 "Lamp On" 2 "Reserved" 3 "Not available" ;
VAL_ 2566834761 RedStopLamp 0 "Lamp Off" 1 "Lamp On" 2 "Reserved" 3 "Not available" ;
VAL_ 2566834761 MalfunctionIndicatorLamp 0 "Lamp Off" 1 "Lamp On" 2 "Short MIL for WWH OBD" 3 "Not available" ;
VAL_ 2566834761 FlashProtectLamp 0 "Slow Flash (1 Hz, 50 % duty cycle)" 1 "Fast Flash (2 Hz or faster, 50% duty cycle)" 2 "Reserved" 3 "Unavailable / Do Not Flash" ;
VAL_ 2566834761 FlashAmberWarningLamp 0 "Slow Flash (1 Hz, 50 % duty cycle)" 1 "Fast Flash (2 Hz or faster, 50% duty cycle)" 2 "Reserved" 3 "Unavailable / Do Not Flash" ;
VAL_ 2566834761 FlashRedStopLamp 0 "Slow Flash (1 Hz, 50 % duty cycle)" 1 "Fast Flash (2 Hz or faster, 50% duty cycle)" 2 "Reserved" 3 "Unavailable / Do Not Flash" ;
VAL_ 2566834761 FlashMalfunctionIndicatorLamp 0 "Slow Flash (1 Hz, 50 % duty cycle)" 1 "Fast Flash (2 Hz or faster, 50% duty cycle)" 2 "Class C DTC" 3 "Unavailable / Do Not Flash" ;
VAL_ 2566834761 SPNConversionMethod 0 "Convert SPN per Version 4" 1 "Convert SPN per Version 1, 2 or 3" ;
VAL_ 2566834761 SPNConversionMethod2 0 "Convert SPN per Version 4" 1 "Convert SPN per Version 1, 2 or 3" ;
VAL_ 2566834761 SPNConversionMethod3 0 "Convert SPN per Version 4" 1 "Convert SPN per Version 1, 2 or 3" ;
VAL_ 2566834761 SPNConversionMethod4 0 "Convert SPN per Version 4" 1 "Convert SPN per Version 1, 2 or 3" ;
VAL_ 2566834761 SPNConversionMethod5 0 "Convert SPN per Version 4" 1 "Convert SPN per Version 1, 2 or 3" ;
VAL_ 2566834761 SPNConversionMethod6 0 "Convert SPN per Version 4" 1 "Convert SPN per Version 1, 2 or 3" ;
VAL_ 2566834761 SPNConversionMethod7 0 "Convert SPN per Version 4" 1 "Convert SPN per Version 1, 2 or 3" ;
VAL_ 2566834761 SPNConversionMethod8 0 "Convert SPN per Version 4" 1 "Convert SPN per Version 1, 2 or 3" ;
VAL_ 2566834761 SPNConversionMethod9 0 "Convert SPN per Version 4" 1 "Convert SPN per Version 1, 2 or 3" ;
VAL_ 2566834761 SPNConversionMethod10 0 "Convert SPN per Version 4" 1 "Convert SPN per Version 1, 2 or 3" ;
VAL_ 2566834761 SPNConversionMethod11 0 "Convert SPN per Version 4" 1 "Convert SPN per Version 1, 2 or 3" ;
VAL_ 2566834761 SPNConversionMethod12 0 "Convert SPN per Version 4" 1 "Convert SPN per Version 1, 2 or 3" ;
VAL_ 2566834691 ProtectLamp 0 "Lamp Off" 1 "Lamp On" 2 "Reserved" 3 "Not available" ;
VAL_ 2566834691 AmberWarningLamp 0 "Lamp Off" 1 "Lamp On" 2 "Reserved" 3 "Not available" ;
VAL_ 2566834691 RedStopLamp 0 "Lamp Off" 1 "Lamp On" 2 "Reserved" 3 "Not available" ;
VAL_ 2566834691 MalfunctionIndicatorLamp 0 "Lamp Off" 1 "Lamp On" 2 "Short MIL for WWH OBD" 3 "Not available" ;
VAL_ 2566834691 FlashProtectLamp 0 "Slow Flash (1 Hz, 50 % duty cycle)" 1 "Fast Flash (2 Hz or faster, 50% duty cycle)" 2 "Reserved" 3 "Unavailable / Do Not Flash" ;
VAL_ 2566834691 FlashAmberWarningLamp 0 "Slow Flash (1 Hz, 50 % duty cycle)" 1 "Fast Flash (2 Hz or faster, 50% duty cycle)" 2 "Reserved" 3 "Unavailable / Do Not Flash" ;
VAL_ 2566834691 FlashRedStopLamp 0 "Slow Flash (1 Hz, 50 % duty cycle)" 1 "Fast Flash (2 Hz or faster, 50% duty cycle)" 2 "Reserved" 3 "Unavailable / Do Not Flash" ;
VAL_ 2566834691 FlashMalfunctionIndicatorLamp 0 "Slow Flash (1 Hz, 50 % duty cycle)" 1 "Fast Flash (2 Hz or faster, 50% duty cycle)" 2 "Class C DTC" 3 "Unavailable / Do Not Flash" ;
VAL_ 2566834691 SPNConversionMethod 0 "Convert SPN per Version 4" 1 "Convert SPN per Version 1, 2 or 3" ;
VAL_ 2566834691 SPNConversionMethod2 0 "Convert SPN per Version 4" 1 "Convert SPN per Version 1, 2 or 3" ;
VAL_ 2566834691 SPNConversionMethod3 0 "Convert SPN per Version 4" 1 "Convert SPN per Version 1, 2 or 3" ;
VAL_ 2566834691 SPNConversionMethod4 0 "Convert SPN per Version 4" 1 "Convert SPN per Version 1, 2 or 3" ;
VAL_ 2566834691 SPNConversionMethod5 0 "Convert SPN per Version 4" 1 "Convert SPN per Version 1, 2 or 3" ;
VAL_ 2566834691 SPNConversionMethod6 0 "Convert SPN per Version 4" 1 "Convert SPN per Version 1, 2 or 3" ;
VAL_ 2566834691 SPNConversionMethod7 0 "Convert SPN per Version 4" 1 "Convert SPN per Version 1, 2 or 3" ;
VAL_ 2566834691 SPNConversionMethod8 0 "Convert SPN per Version 4" 1 "Convert SPN per Version 1, 2 or 3" ;
VAL_ 2566834691 SPNConversionMethod9 0 "Convert SPN per Version 4" 1 "Convert SPN per Version 1, 2 or 3" ;
VAL_ 2566834691 SPNConversionMethod10 0 "Convert SPN per Version 4" 1 "Convert SPN per Version 1, 2 or 3" ;
VAL_ 2566834691 SPNConversionMethod11 0 "Convert SPN per Version 4" 1 "Convert SPN per Version 1, 2 or 3" ;
VAL_ 2566834691 SPNConversionMethod12 0 "Convert SPN per Version 4" 1 "Convert SPN per Version 1, 2 or 3" ;
VAL_ 2566834920 ProtectLamp 0 "Lamp Off" 1 "Lamp On" 2 "Reserved" 3 "Not available" ;
VAL_ 2566834920 AmberWarningLamp 0 "Lamp Off" 1 "Lamp On" 2 "Reserved" 3 "Not available" ;
VAL_ 2566834920 RedStopLamp 0 "Lamp Off" 1 "Lamp On" 2 "Reserved" 3 "Not available" ;
VAL_ 2566834920 MalfunctionIndicatorLamp 0 "Lamp Off" 1 "Lamp On" 2 "Short MIL for WWH OBD" 3 "Not available" ;
VAL_ 2566834920 FlashProtectLamp 0 "Slow Flash (1 Hz, 50 % duty cycle)" 1 "Fast Flash (2 Hz or faster, 50% duty cycle)" 2 "Reserved" 3 "Unavailable / Do Not Flash" ;
VAL_ 2566834920 FlashAmberWarningLamp 0 "Slow Flash (1 Hz, 50 % duty cycle)" 1 "Fast Flash (2 Hz or faster, 50% duty cycle)" 2 "Reserved" 3 "Unavailable / Do Not Flash" ;
VAL_ 2566834920 FlashRedStopLamp 0 "Slow Flash (1 Hz, 50 % duty cycle)" 1 "Fast Flash (2 Hz or faster, 50% duty cycle)" 2 "Reserved" 3 "Unavailable / Do Not Flash" ;
VAL_ 2566834920 FlashMalfunctionIndicatorLamp 0 "Slow Flash (1 Hz, 50 % duty cycle)" 1 "Fast Flash (2 Hz or faster, 50% duty cycle)" 2 "Class C DTC" 3 "Unavailable / Do Not Flash" ;
VAL_ 2566834920 SPNConversionMethod 0 "Convert SPN per Version 4" 1 "Convert SPN per Version 1, 2 or 3" ;
VAL_ 2566834920 SPNConversionMethod2 0 "Convert SPN per Version 4" 1 "Convert SPN per Version 1, 2 or 3" ;
VAL_ 2566834920 SPNConversionMethod3 0 "Convert SPN per Version 4" 1 "Convert SPN per Version 1, 2 or 3" ;
VAL_ 2566834920 SPNConversionMethod4 0 "Convert SPN per Version 4" 1 "Convert SPN per Version 1, 2 or 3" ;
VAL_ 2566834920 SPNConversionMethod5 0 "Convert SPN per Version 4" 1 "Convert SPN per Version 1, 2 or 3" ;
VAL_ 2566834920 SPNConversionMethod6 0 "Convert SPN per Version 4" 1 "Convert SPN per Version 1, 2 or 3" ;
VAL_ 2566834920 SPNConversionMethod7 0 "Convert SPN per Version 4" 1 "Convert SPN per Version 1, 2 or 3" ;
VAL_ 2566834920 SPNConversionMethod8 0 "Convert SPN per Version 4" 1 "Convert SPN per Version 1, 2 or 3" ;
VAL_ 2566834920 SPNConversionMethod9 0 "Convert SPN per Version 4" 1 "Convert SPN per Version 1, 2 or 3" ;
VAL_ 2566834920 SPNConversionMethod10 0 "Convert SPN per Version 4" 1 "Convert SPN per Version 1, 2 or 3" ;
VAL_ 2566834920 SPNConversionMethod11 0 "Convert SPN per Version 4" 1 "Convert SPN per Version 1, 2 or 3" ;
VAL_ 2566834920 SPNConversionMethod12 0 "Convert SPN per Version 4" 1 "Convert SPN per Version 1, 2 or 3" ;
VAL_ 2566834734 ProtectLamp 0 "Lamp Off" 1 "Lamp On" 2 "Reserved" 3 "Not available" ;
VAL_ 2566834734 AmberWarningLamp 0 "Lamp Off" 1 "Lamp On" 2 "Reserved" 3 "Not available" ;
VAL_ 2566834734 RedStopLamp 0 "Lamp Off" 1 "Lamp On" 2 "Reserved" 3 "Not available" ;
VAL_ 2566834734 MalfunctionIndicatorLamp 0 "Lamp Off" 1 "Lamp On" 2 "Short MIL for WWH OBD" 3 "Not available" ;
VAL_ 2566834734 FlashProtectLamp 0 "Slow Flash (1 Hz, 50 % duty cycle)" 1 "Fast Flash (2 Hz or faster, 50% duty cycle)" 2 "Reserved" 3 "Unavailable / Do Not Flash" ;
VAL_ 2566834734 FlashAmberWarningLamp 0 "Slow Flash (1 Hz, 50 % duty cycle)" 1 "Fast Flash (2 Hz or faster, 50% duty cycle)" 2 "Reserved" 3 "Unavailable / Do Not Flash" ;
VAL_ 2566834734 FlashRedStopLamp 0 "Slow Flash (1 Hz, 50 % duty cycle)" 1 "Fast Flash (2 Hz or faster, 50% duty cycle)" 2 "Reserved" 3 "Unavailable / Do Not Flash" ;
VAL_ 2566834734 FlashMalfunctionIndicatorLamp 0 "Slow Flash (1 Hz, 50 % duty cycle)" 1 "Fast Flash (2 Hz or faster, 50% duty cycle)" 2 "Class C DTC" 3 "Unavailable / Do Not Flash" ;
VAL_ 2566834734 SPNConversionMethod 0 "Convert SPN per Version 4" 1 "Convert SPN per Version 1, 2 or 3" ;
VAL_ 2566834734 SPNConversionMethod2 0 "Convert SPN per Version 4" 1 "Convert SPN per Version 1, 2 or 3" ;
VAL_ 2566834734 SPNConversionMethod3 0 "Convert SPN per Version 4" 1 "Convert SPN per Version 1, 2 or 3" ;
VAL_ 2566834734 SPNConversionMethod4 0 "Convert SPN per Version 4" 1 "Convert SPN per Version 1, 2 or 3" ;
VAL_ 2566834734 SPNConversionMethod5 0 "Convert SPN per Version 4" 1 "Convert SPN per Version 1, 2 or 3" ;
VAL_ 2566834734 SPNConversionMethod6 0 "Convert SPN per Version 4" 1 "Convert SPN per Version 1, 2 or 3" ;
VAL_ 2566834734 SPNConversionMethod7 0 "Convert SPN per Version 4" 1 "Convert SPN per Version 1, 2 or 3" ;
VAL_ 2566834734 SPNConversionMethod8 0 "Convert SPN per Version 4" 1 "Convert SPN per Version 1, 2 or 3" ;
VAL_ 2566834734 SPNConversionMethod9 0 "Convert SPN per Version 4" 1 "Convert SPN per Version 1, 2 or 3" ;
VAL_ 2566834734 SPNConversionMethod10 0 "Convert SPN per Version 4" 1 "Convert SPN per Version 1, 2 or 3" ;
VAL_ 2566834734 SPNConversionMethod11 0 "Convert SPN per Version 4" 1 "Convert SPN per Version 1, 2 or 3" ;
VAL_ 2566834734 SPNConversionMethod12 0 "Convert SPN per Version 4" 1 "Convert SPN per Version 1, 2 or 3" ;
VAL_ 2566834690 ProtectLamp 0 "Lamp Off" 1 "Lamp On" 2 "Reserved" 3 "Not available" ;
VAL_ 2566834690 AmberWarningLamp 0 "Lamp Off" 1 "Lamp On" 2 "Reserved" 3 "Not available" ;
VAL_ 2566834690 RedStopLamp 0 "Lamp Off" 1 "Lamp On" 2 "Reserved" 3 "Not available" ;
VAL_ 2566834690 MalfunctionIndicatorLamp 0 "Lamp Off" 1 "Lamp On" 2 "Short MIL for WWH OBD" 3 "Not available" ;
VAL_ 2566834690 FlashProtectLamp 0 "Slow Flash (1 Hz, 50 % duty cycle)" 1 "Fast Flash (2 Hz or faster, 50% duty cycle)" 2 "Reserved" 3 "Unavailable / Do Not Flash" ;
VAL_ 2566834690 FlashAmberWarningLamp 0 "Slow Flash (1 Hz, 50 % duty cycle)" 1 "Fast Flash (2 Hz or faster, 50% duty cycle)" 2 "Reserved" 3 "Unavailable / Do Not Flash" ;
VAL_ 2566834690 FlashRedStopLamp 0 "Slow Flash (1 Hz, 50 % duty cycle)" 1 "Fast Flash (2 Hz or faster, 50% duty cycle)" 2 "Reserved" 3 "Unavailable / Do Not Flash" ;
VAL_ 2566834690 FlashMalfunctionIndicatorLamp 0 "Slow Flash (1 Hz, 50 % duty cycle)" 1 "Fast Flash (2 Hz or faster, 50% duty cycle)" 2 "Class C DTC" 3 "Unavailable / Do Not Flash" ;
VAL_ 2566834690 SPNConversionMethod 0 "Convert SPN per Version 4" 1 "Convert SPN per Version 1, 2 or 3" ;
VAL_ 2566834690 SPNConversionMethod2 0 "Convert SPN per Version 4" 1 "Convert SPN per Version 1, 2 or 3" ;
VAL_ 2566834690 SPNConversionMethod3 0 "Convert SPN per Version 4" 1 "Convert SPN per Version 1, 2 or 3" ;
VAL_ 2566834690 SPNConversionMethod4 0 "Convert SPN per Version 4" 1 "Convert SPN per Version 1, 2 or 3" ;
VAL_ 2566834690 SPNConversionMethod5 0 "Convert SPN per Version 4" 1 "Convert SPN per Version 1, 2 or 3" ;
VAL_ 2566834690 SPNConversionMethod6 0 "Convert SPN per Version 4" 1 "Convert SPN per Version 1, 2 or 3" ;
VAL_ 2566834690 SPNConversionMethod7 0 "Convert SPN per Version 4" 1 "Convert SPN per Version 1, 2 or 3" ;
VAL_ 2566834690 SPNConversionMethod8 0 "Convert SPN per Version 4" 1 "Convert SPN per Version 1, 2 or 3" ;
VAL_ 2566834690 SPNConversionMethod9 0 "Convert SPN per Version 4" 1 "Convert SPN per Version 1, 2 or 3" ;
VAL_ 2566834690 SPNConversionMethod10 0 "Convert SPN per Version 4" 1 "Convert SPN per Version 1, 2 or 3" ;
VAL_ 2566834690 SPNConversionMethod11 0 "Convert SPN per Version 4" 1 "Convert SPN per Version 1, 2 or 3" ;
VAL_ 2566834690 SPNConversionMethod12 0 "Convert SPN per Version 4" 1 "Convert SPN per Version 1, 2 or 3" ;
VAL_ 2566834711 ProtectLamp 0 "Lamp Off" 1 "Lamp On" 2 "Reserved" 3 "Not available" ;
VAL_ 2566834711 AmberWarningLamp 0 "Lamp Off" 1 "Lamp On" 2 "Reserved" 3 "Not available" ;
VAL_ 2566834711 RedStopLamp 0 "Lamp Off" 1 "Lamp On" 2 "Reserved" 3 "Not available" ;
VAL_ 2566834711 MalfunctionIndicatorLamp 0 "Lamp Off" 1 "Lamp On" 2 "Short MIL for WWH OBD" 3 "Not available" ;
VAL_ 2566834711 FlashProtectLamp 0 "Slow Flash (1 Hz, 50 % duty cycle)" 1 "Fast Flash (2 Hz or faster, 50% duty cycle)" 2 "Reserved" 3 "Unavailable / Do Not Flash" ;
VAL_ 2566834711 FlashAmberWarningLamp 0 "Slow Flash (1 Hz, 50 % duty cycle)" 1 "Fast Flash (2 Hz or faster, 50% duty cycle)" 2 "Reserved" 3 "Unavailable / Do Not Flash" ;
VAL_ 2566834711 FlashRedStopLamp 0 "Slow Flash (1 Hz, 50 % duty cycle)" 1 "Fast Flash (2 Hz or faster, 50% duty cycle)" 2 "Reserved" 3 "Unavailable / Do Not Flash" ;
VAL_ 2566834711 FlashMalfunctionIndicatorLamp 0 "Slow Flash (1 Hz, 50 % duty cycle)" 1 "Fast Flash (2 Hz or faster, 50% duty cycle)" 2 "Class C DTC" 3 "Unavailable / Do Not Flash" ;
VAL_ 2566834711 SPNConversionMethod 0 "Convert SPN per Version 4" 1 "Convert SPN per Version 1, 2 or 3" ;
VAL_ 2566834711 SPNConversionMethod2 0 "Convert SPN per Version 4" 1 "Convert SPN per Version 1, 2 or 3" ;
VAL_ 2566834711 SPNConversionMethod3 0 "Convert SPN per Version 4" 1 "Convert SPN per Version 1, 2 or 3" ;
VAL_ 2566834711 SPNConversionMethod4 0 "Convert SPN per Version 4" 1 "Convert SPN per Version 1, 2 or 3" ;
VAL_ 2566834711 SPNConversionMethod5 0 "Convert SPN per Version 4" 1 "Convert SPN per Version 1, 2 or 3" ;
VAL_ 2566834711 SPNConversionMethod6 0 "Convert SPN per Version 4" 1 "Convert SPN per Version 1, 2 or 3" ;
VAL_ 2566834711 SPNConversionMethod7 0 "Convert SPN per Version 4" 1 "Convert SPN per Version 1, 2 or 3" ;
VAL_ 2566834711 SPNConversionMethod8 0 "Convert SPN per Version 4" 1 "Convert SPN per Version 1, 2 or 3" ;
VAL_ 2566834711 SPNConversionMethod9 0 "Convert SPN per Version 4" 1 "Convert SPN per Version 1, 2 or 3" ;
VAL_ 2566834711 SPNConversionMethod10 0 "Convert SPN per Version 4" 1 "Convert SPN per Version 1, 2 or 3" ;
VAL_ 2566834711 SPNConversionMethod11 0 "Convert SPN per Version 4" 1 "Convert SPN per Version 1, 2 or 3" ;
VAL_ 2566834711 SPNConversionMethod12 0 "Convert SPN per Version 4" 1 "Convert SPN per Version 1, 2 or 3" ;
VAL_ 2566834725 ProtectLamp 0 "Lamp Off" 1 "Lamp On" 2 "Reserved" 3 "Not available" ;
VAL_ 2566834725 AmberWarningLamp 0 "Lamp Off" 1 "Lamp On" 2 "Reserved" 3 "Not available" ;
VAL_ 2566834725 RedStopLamp 0 "Lamp Off" 1 "Lamp On" 2 "Reserved" 3 "Not available" ;
VAL_ 2566834725 MalfunctionIndicatorLamp 0 "Lamp Off" 1 "Lamp On" 2 "Short MIL for WWH OBD" 3 "Not available" ;
VAL_ 2566834725 FlashProtectLamp 0 "Slow Flash (1 Hz, 50 % duty cycle)" 1 "Fast Flash (2 Hz or faster, 50% duty cycle)" 2 "Reserved" 3 "Unavailable / Do Not Flash" ;
VAL_ 2566834725 FlashAmberWarningLamp 0 "Slow Flash (1 Hz, 50 % duty cycle)" 1 "Fast Flash (2 Hz or faster, 50% duty cycle)" 2 "Reserved" 3 "Unavailable / Do Not Flash" ;
VAL_ 2566834725 FlashRedStopLamp 0 "Slow Flash (1 Hz, 50 % duty cycle)" 1 "Fast Flash (2 Hz or faster, 50% duty cycle)" 2 "Reserved" 3 "Unavailable / Do Not Flash" ;
VAL_ 2566834725 FlashMalfunctionIndicatorLamp 0 "Slow Flash (1 Hz, 50 % duty cycle)" 1 "Fast Flash (2 Hz or faster, 50% duty cycle)" 2 "Class C DTC" 3 "Unavailable / Do Not Flash" ;
VAL_ 2566834725 SPNConversionMethod 0 "Convert SPN per Version 4" 1 "Convert SPN per Version 1, 2 or 3" ;
VAL_ 2566834725 SPNConversionMethod2 0 "Convert SPN per Version 4" 1 "Convert SPN per Version 1, 2 or 3" ;
VAL_ 2566834725 SPNConversionMethod3 0 "Convert SPN per Version 4" 1 "Convert SPN per Version 1, 2 or 3" ;
VAL_ 2566834725 SPNConversionMethod4 0 "Convert SPN per Version 4" 1 "Convert SPN per Version 1, 2 or 3" ;
VAL_ 2566834725 SPNConversionMethod5 0 "Convert SPN per Version 4" 1 "Convert SPN per Version 1, 2 or 3" ;
VAL_ 2566834725 SPNConversionMethod6 0 "Convert SPN per Version 4" 1 "Convert SPN per Version 1, 2 or 3" ;
VAL_ 2566834725 SPNConversionMethod7 0 "Convert SPN per Version 4" 1 "Convert SPN per Version 1, 2 or 3" ;
VAL_ 2566834725 SPNConversionMethod8 0 "Convert SPN per Version 4" 1 "Convert SPN per Version 1, 2 or 3" ;
VAL_ 2566834725 SPNConversionMethod9 0 "Convert SPN per Version 4" 1 "Convert SPN per Version 1, 2 or 3" ;
VAL_ 2566834725 SPNConversionMethod10 0 "Convert SPN per Version 4" 1 "Convert SPN per Version 1, 2 or 3" ;
VAL_ 2566834725 SPNConversionMethod11 0 "Convert SPN per Version 4" 1 "Convert SPN per Version 1, 2 or 3" ;
VAL_ 2566834725 SPNConversionMethod12 0 "Convert SPN per Version 4" 1 "Convert SPN per Version 1, 2 or 3" ;
VAL_ 2566834739 ProtectLamp 0 "Lamp Off" 1 "Lamp On" 2 "Reserved" 3 "Not available" ;
VAL_ 2566834739 AmberWarningLamp 0 "Lamp Off" 1 "Lamp On" 2 "Reserved" 3 "Not available" ;
VAL_ 2566834739 RedStopLamp 0 "Lamp Off" 1 "Lamp On" 2 "Reserved" 3 "Not available" ;
VAL_ 2566834739 MalfunctionIndicatorLamp 0 "Lamp Off" 1 "Lamp On" 2 "Short MIL for WWH OBD" 3 "Not available" ;
VAL_ 2566834739 FlashProtectLamp 0 "Slow Flash (1 Hz, 50 % duty cycle)" 1 "Fast Flash (2 Hz or faster, 50% duty cycle)" 2 "Reserved" 3 "Unavailable / Do Not Flash" ;
VAL_ 2566834739 FlashAmberWarningLamp 0 "Slow Flash (1 Hz, 50 % duty cycle)" 1 "Fast Flash (2 Hz or faster, 50% duty cycle)" 2 "Reserved" 3 "Unavailable / Do Not Flash" ;
VAL_ 2566834739 FlashRedStopLamp 0 "Slow Flash (1 Hz, 50 % duty cycle)" 1 "Fast Flash (2 Hz or faster, 50% duty cycle)" 2 "Reserved" 3 "Unavailable / Do Not Flash" ;
VAL_ 2566834739 FlashMalfunctionIndicatorLamp 0 "Slow Flash (1 Hz, 50 % duty cycle)" 1 "Fast Flash (2 Hz or faster, 50% duty cycle)" 2 "Class C DTC" 3 "Unavailable / Do Not Flash" ;
VAL_ 2566834739 SPNConversionMethod 0 "Convert SPN per Version 4" 1 "Convert SPN per Version 1, 2 or 3" ;
VAL_ 2566834739 SPNConversionMethod2 0 "Convert SPN per Version 4" 1 "Convert SPN per Version 1, 2 or 3" ;
VAL_ 2566834739 SPNConversionMethod3 0 "Convert SPN per Version 4" 1 "Convert SPN per Version 1, 2 or 3" ;
VAL_ 2566834739 SPNConversionMethod4 0 "Convert SPN per Version 4" 1 "Convert SPN per Version 1, 2 or 3" ;
VAL_ 2566834739 SPNConversionMethod5 0 "Convert SPN per Version 4" 1 "Convert SPN per Version 1, 2 or 3" ;
VAL_ 2566834739 SPNConversionMethod6 0 "Convert SPN per Version 4" 1 "Convert SPN per Version 1, 2 or 3" ;
VAL_ 2566834739 SPNConversionMethod7 0 "Convert SPN per Version 4" 1 "Convert SPN per Version 1, 2 or 3" ;
VAL_ 2566834739 SPNConversionMethod8 0 "Convert SPN per Version 4" 1 "Convert SPN per Version 1, 2 or 3" ;
VAL_ 2566834739 SPNConversionMethod9 0 "Convert SPN per Version 4" 1 "Convert SPN per Version 1, 2 or 3" ;
VAL_ 2566834739 SPNConversionMethod10 0 "Convert SPN per Version 4" 1 "Convert SPN per Version 1, 2 or 3" ;
VAL_ 2566834739 SPNConversionMethod11 0 "Convert SPN per Version 4" 1 "Convert SPN per Version 1, 2 or 3" ;
VAL_ 2566834739 SPNConversionMethod12 0 "Convert SPN per Version 4" 1 "Convert SPN per Version 1, 2 or 3" ;
VAL_ 2566834699 ProtectLamp 0 "Lamp Off" 1 "Lamp On" 2 "Reserved" 3 "Not available" ;
VAL_ 2566834699 AmberWarningLamp 0 "Lamp Off" 1 "Lamp On" 2 "Reserved" 3 "Not available" ;
VAL_ 2566834699 RedStopLamp 0 "Lamp Off" 1 "Lamp On" 2 "Reserved" 3 "Not available" ;
VAL_ 2566834699 MalfunctionIndicatorLamp 0 "Lamp Off" 1 "Lamp On" 2 "Short MIL for WWH OBD" 3 "Not available" ;
VAL_ 2566834699 FlashProtectLamp 0 "Slow Flash (1 Hz, 50 % duty cycle)" 1 "Fast Flash (2 Hz or faster, 50% duty cycle)" 2 "Reserved" 3 "Unavailable / Do Not Flash" ;
VAL_ 2566834699 FlashAmberWarningLamp 0 "Slow Flash (1 Hz, 50 % duty cycle)" 1 "Fast Flash (2 Hz or faster, 50% duty cycle)" 2 "Reserved" 3 "Unavailable / Do Not Flash" ;
VAL_ 2566834699 FlashRedStopLamp 0 "Slow Flash (1 Hz, 50 % duty cycle)" 1 "Fast Flash (2 Hz or faster, 50% duty cycle)" 2 "Reserved" 3 "Unavailable / Do Not Flash" ;
VAL_ 2566834699 FlashMalfunctionIndicatorLamp 0 "Slow Flash (1 Hz, 50 % duty cycle)" 1 "Fast Flash (2 Hz or faster, 50% duty cycle)" 2 "Class C DTC" 3 "Unavailable / Do Not Flash" ;
VAL_ 2566834699 SPNConversionMethod 0 "Convert SPN per Version 4" 1 "Convert SPN per Version 1, 2 or 3" ;
VAL_ 2566834699 SPNConversionMethod2 0 "Convert SPN per Version 4" 1 "Convert SPN per Version 1, 2 or 3" ;
VAL_ 2566834699 SPNConversionMethod3 0 "Convert SPN per Version 4" 1 "Convert SPN per Version 1, 2 or 3" ;
VAL_ 2566834699 SPNConversionMethod4 0 "Convert SPN per Version 4" 1 "Convert SPN per Version 1, 2 or 3" ;
VAL_ 2566834699 SPNConversionMethod5 0 "Convert SPN per Version 4" 1 "Convert SPN per Version 1, 2 or 3" ;
VAL_ 2566834699 SPNConversionMethod6 0 "Convert SPN per Version 4" 1 "Convert SPN per Version 1, 2 or 3" ;
VAL_ 2566834699 SPNConversionMethod7 0 "Convert SPN per Version 4" 1 "Convert SPN per Version 1, 2 or 3" ;
VAL_ 2566834699 SPNConversionMethod8 0 "Convert SPN per Version 4" 1 "Convert SPN per Version 1, 2 or 3" ;
VAL_ 2566834699 SPNConversionMethod9 0 "Convert SPN per Version 4" 1 "Convert SPN per Version 1, 2 or 3" ;
VAL_ 2566834699 SPNConversionMethod10 0 "Convert SPN per Version 4" 1 "Convert SPN per Version 1, 2 or 3" ;
VAL_ 2566834699 SPNConversionMethod11 0 "Convert SPN per Version 4" 1 "Convert SPN per Version 1, 2 or 3" ;
VAL_ 2566834699 SPNConversionMethod12 0 "Convert SPN per Version 4" 1 "Convert SPN per Version 1, 2 or 3" ;
VAL_ 2566759719 LockStatusOfDoor1 0 "Unlocked" 1 "Locked" 2 "Error" 3 "Not available" ;
VAL_ 2566759719 OpenStatusOfDoor1 0 "Door closed" 1 "Door opened" 2 "Error" 3 "Not available" ;
VAL_ 2566759719 EnableStatusOfDoor1 0 "Door disabled" 1 "Door enabled" 2 "Error" 3 "Not available" ;
VAL_ 2566759719 LockStatusOfDoor2 0 "Unlocked" 1 "Locked" 2 "Error" 3 "Not available" ;
VAL_ 2566759719 OpenStatusOfDoor2 0 "Door closed" 1 "Door opened" 2 "Error" 3 "Not available" ;
VAL_ 2566759719 EnableStatusOfDoor2 0 "Door disabled" 1 "Door enabled" 2 "Error" 3 "Not available" ;
VAL_ 2566759719 LockStatusOfDoor3 0 "Unlocked" 1 "Locked" 2 "Error" 3 "Not available" ;
VAL_ 2566759719 OpenStatusOfDoor3 0 "Door closed" 1 "Door opened" 2 "Error" 3 "Not available" ;
VAL_ 2566759719 EnableStatusOfDoor3 0 "Door disabled" 1 "Door enabled" 2 "Error" 3 "Not available" ;
VAL_ 2566759719 LockStatusOfDoor4 0 "Unlocked" 1 "Locked" 2 "Error" 3 "Not available" ;
VAL_ 2566759719 OpenStatusOfDoor4 0 "Door closed" 1 "Door opened" 2 "Error" 3 "Not available" ;
VAL_ 2566759719 EnableStatusOfDoor4 0 "Door disabled" 1 "Door enabled" 2 "Error" 3 "Not available" ;
VAL_ 2566759719 LockStatusOfDoor5 0 "Unlocked" 1 "Locked" 2 "Error" 3 "Not available" ;
VAL_ 2566759719 OpenStatusOfDoor5 0 "Door closed" 1 "Door opened" 2 "Error" 3 "Not available" ;
VAL_ 2566759719 EnableStatusOfDoor5 0 "Door disabled" 1 "Door enabled" 2 "Error" 3 "Not available" ;
VAL_ 2566759719 LockStatusOfDoor6 0 "Unlocked" 1 "Locked" 2 "Error" 3 "Not available" ;
VAL_ 2566759719 OpenStatusOfDoor6 0 "Door closed" 1 "Door opened" 2 "Error" 3 "Not available" ;
VAL_ 2566759719 EnableStatusOfDoor6 0 "Door disabled" 1 "Door enabled" 2 "Error" 3 "Not available" ;
VAL_ 2566759719 LockStatusOfDoor7 0 "Unlocked" 1 "Locked" 2 "Error" 3 "Not available" ;
VAL_ 2566759719 OpenStatusOfDoor7 0 "Door closed" 1 "Door opened" 2 "Error" 3 "Not available" ;
VAL_ 2566759719 EnableStatusOfDoor7 0 "Door disabled" 1 "Door enabled" 2 "Error" 3 "Not available" ;
VAL_ 2566759719 LockStatusOfDoor8 0 "Unlocked" 1 "Locked" 2 "Error" 3 "Not available" ;
VAL_ 2566759719 OpenStatusOfDoor8 0 "Door closed" 1 "Door opened" 2 "Error" 3 "Not available" ;
VAL_ 2566759719 EnableStatusOfDoor8 0 "Door disabled" 1 "Door enabled" 2 "Error" 3 "Not available" ;
VAL_ 2566759719 LockStatusOfDoor9 0 "Unlocked" 1 "Locked" 2 "Error" 3 "Not available" ;
VAL_ 2566759719 OpenStatusOfDoor9 0 "Door closed" 1 "Door opened" 2 "Error" 3 "Not available" ;
VAL_ 2566759719 EnableStatusOfDoor9 0 "Door disabled" 1 "Door enabled" 2 "Error" 3 "Not available" ;
VAL_ 2566759719 LockStatusOfDoor10 0 "Unlocked" 1 "Locked" 2 "Error" 3 "Not available" ;
VAL_ 2566759719 OpenStatusOfDoor10 0 "Door closed" 1 "Door opened" 2 "Error" 3 "Not available" ;
VAL_ 2566759719 EnableStatusOfDoor10 0 "Door disabled" 1 "Door enabled" 2 "Error" 3 "Not available" ;
VAL_ 2364539648 AcceleratorPedal1LowIdleSwitch 0 "Not Available,3" ;
VAL_ 2364539648 AcceleratorPedalKickdownSwitch 0 "Not Available ,3" ;
VAL_ 2364539648 RoadSpeedLimitStatus 0 "Active" 1 "Not Active" 2 "Error" 3 "Not available" ;
VAL_ 2364539648 AcceleratorPedal2LowIdleSwitch 0 "Accelerator pedal 2 not in low idle condition" 1 "Accelerator pedal 2 in low idle condition" 2 "Error" 3 "Not available" ;
VAL_ 2364539648 VehicleAccltnRateLimitStatus 0 "Limit not active" 1 "Limit active" 2 "Reserved" 3 "Not available" ;
VAL_ 2364539648 MomentaryEngMaxPowerEnblFdbck 0 "disabled" 1 "supported" 2 "reserved" 3 "don't care" ;
VAL_ 2364539648 DPFThermalManagementActive 0 "DPF Thermal Management is not active" 1 "DPF Thermal Management is active" 2 "Reserved" 3 "Don't care" ;
VAL_ 2364539648 SCRThermalManagementActive 0 "SCR Thermal Management is not active" 1 "SCR Thermal Management is active" 2 "Reserved" 3 "Don't care" ;
